VERSION ""

NS_ :

BS_:

BU_: WPC2 RLPSU DPSU APSU PSB SHVU_RR vHS_B2 FCS EMCU SLB ARS RCM CGW_CCU vDummy_HS_B ATS RLHV SGU PFSU ALBCU DSAU SWRC SHVU_FR RCS RRPSU BLTN_CAM SCM DLBCU OHCL RWPC RRHV WPC HOD ASAU

BO_ 862 SBCM_RL_01_200ms: 8 CGW_CCU
 SG_ SBCM_RL_Crc1Val : 0|8@1+ (1,0) [0|0] ""  Vector__XXX
 SG_ RL_CrashUnlockCmd : 10|1@1+ (1,0) [0|0] ""  BLTN_CAM
 SG_ SBCM_RL_AlvCnt1Val : 12|4@1+ (1,0) [0|0] ""  Vector__XXX
 SG_ Warn_RrLftDrSwSta_SBCM : 16|2@1+ (1,0) [0|0] ""  WPC,RWPC,APSU,ATS,BLTN_CAM,WPC2
 SG_ DoorLock_RrLftDrUnLkSta_SBCM : 18|2@1+ (1,0) [0|0] ""  ATS
 SG_ RL_SEAActivated : 20|2@1+ (1,0) [0|0] ""  Vector__XXX
 SG_ RL_SEAWarn : 22|2@1+ (1,0) [0|0] ""  Vector__XXX
 SG_ RL_SEWWarn : 24|2@1+ (1,0) [0|0] ""  Vector__XXX
 SG_ RL_ReleaseWarn : 26|2@1+ (1,0) [0|0] ""  Vector__XXX
 SG_ RL_SWFailAlarm : 28|2@1+ (1,0) [0|0] ""  Vector__XXX
 SG_ RL_ChildLock_ActnFlSta : 30|2@1+ (1,0) [0|0] ""  Vector__XXX
 SG_ RL_MRActivationAlarm : 32|2@1+ (1,0) [0|0] ""  Vector__XXX
 SG_ RL_ChildLock_Status : 34|2@1+ (1,0) [0|0] ""  Vector__XXX
 SG_ USM_RLGhostDoorSta : 36|2@1+ (1,0) [0|0] ""  Vector__XXX
 SG_ DoorLock_PDSLkSwSta_RL : 40|2@1+ (1,0) [0|0] ""  Vector__XXX
 SG_ PDS_TypeOption_RL : 42|2@1+ (1,0) [0|0] ""  Vector__XXX
 SG_ RLDoorPushAlarm : 8|2@1+ (1,0) [0|0] ""  Vector__XXX

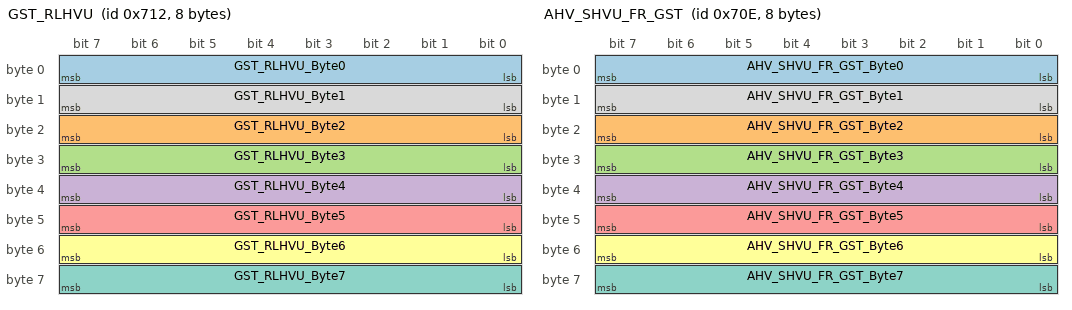
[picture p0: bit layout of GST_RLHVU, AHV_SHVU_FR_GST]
BO_ 1810 GST_RLHVU: 8 CGW_CCU
 SG_ GST_RLHVU_Byte0 : 0|8@1+ (1,0) [0|0] ""  RLHV,RLPSU
 SG_ GST_RLHVU_Byte2 : 16|8@1+ (1,0) [0|0] ""  RLHV,RLPSU
 SG_ GST_RLHVU_Byte3 : 24|8@1+ (1,0) [0|0] ""  RLHV,RLPSU
 SG_ GST_RLHVU_Byte4 : 32|8@1+ (1,0) [0|0] ""  RLHV,RLPSU
 SG_ GST_RLHVU_Byte5 : 40|8@1+ (1,0) [0|0] ""  RLHV,RLPSU
 SG_ GST_RLHVU_Byte6 : 48|8@1+ (1,0) [0|0] ""  RLHV,RLPSU
 SG_ GST_RLHVU_Byte7 : 56|8@1+ (1,0) [0|0] ""  RLHV,RLPSU
 SG_ GST_RLHVU_Byte1 : 8|8@1+ (1,0) [0|0] ""  RLHV,RLPSU

BO_ 1806 AHV_SHVU_FR_GST: 8 SHVU_FR
 SG_ AHV_SHVU_FR_GST_Byte0 : 0|8@1+ (1,0) [0|0] ""  CGW_CCU
 SG_ AHV_SHVU_FR_GST_Byte2 : 16|8@1+ (1,0) [0|0] ""  CGW_CCU
 SG_ AHV_SHVU_FR_GST_Byte3 : 24|8@1+ (1,0) [0|0] ""  CGW_CCU
 SG_ AHV_SHVU_FR_GST_Byte4 : 32|8@1+ (1,0) [0|0] ""  CGW_CCU
 SG_ AHV_SHVU_FR_GST_Byte5 : 40|8@1+ (1,0) [0|0] ""  CGW_CCU
 SG_ AHV_SHVU_FR_GST_Byte6 : 48|8@1+ (1,0) [0|0] ""  CGW_CCU
 SG_ AHV_SHVU_FR_GST_Byte7 : 56|8@1+ (1,0) [0|0] ""  CGW_CCU
 SG_ AHV_SHVU_FR_GST_Byte1 : 8|8@1+ (1,0) [0|0] ""  CGW_CCU

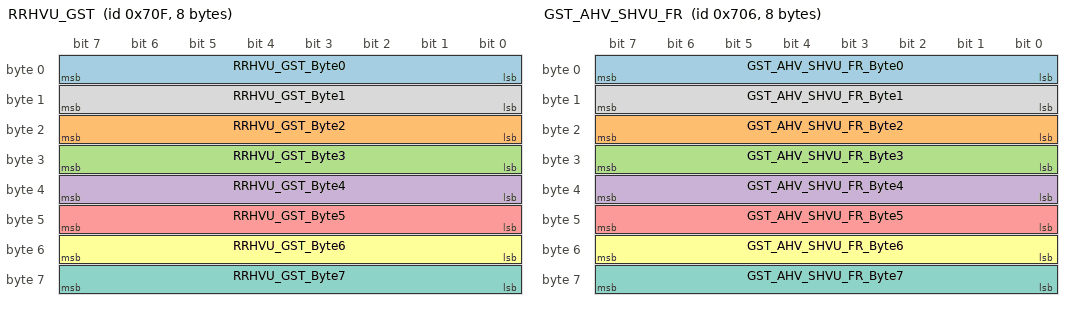
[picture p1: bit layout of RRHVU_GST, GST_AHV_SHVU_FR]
BO_ 1807 RRHVU_GST: 8 RRHV
 SG_ RRHVU_GST_Byte0 : 0|8@1+ (1,0) [0|0] ""  CGW_CCU
 SG_ RRHVU_GST_Byte2 : 16|8@1+ (1,0) [0|0] ""  CGW_CCU
 SG_ RRHVU_GST_Byte3 : 24|8@1+ (1,0) [0|0] ""  CGW_CCU
 SG_ RRHVU_GST_Byte4 : 32|8@1+ (1,0) [0|0] ""  CGW_CCU
 SG_ RRHVU_GST_Byte5 : 40|8@1+ (1,0) [0|0] ""  CGW_CCU
 SG_ RRHVU_GST_Byte6 : 48|8@1+ (1,0) [0|0] ""  CGW_CCU
 SG_ RRHVU_GST_Byte7 : 56|8@1+ (1,0) [0|0] ""  CGW_CCU
 SG_ RRHVU_GST_Byte1 : 8|8@1+ (1,0) [0|0] ""  CGW_CCU

BO_ 1798 GST_AHV_SHVU_FR: 8 CGW_CCU
 SG_ GST_AHV_SHVU_FR_Byte0 : 0|8@1+ (1,0) [0|0] ""  SHVU_FR
 SG_ GST_AHV_SHVU_FR_Byte2 : 16|8@1+ (1,0) [0|0] ""  SHVU_FR
 SG_ GST_AHV_SHVU_FR_Byte3 : 24|8@1+ (1,0) [0|0] ""  SHVU_FR
 SG_ GST_AHV_SHVU_FR_Byte4 : 32|8@1+ (1,0) [0|0] ""  SHVU_FR
 SG_ GST_AHV_SHVU_FR_Byte5 : 40|8@1+ (1,0) [0|0] ""  SHVU_FR
 SG_ GST_AHV_SHVU_FR_Byte6 : 48|8@1+ (1,0) [0|0] ""  SHVU_FR
 SG_ GST_AHV_SHVU_FR_Byte7 : 56|8@1+ (1,0) [0|0] ""  SHVU_FR
 SG_ GST_AHV_SHVU_FR_Byte1 : 8|8@1+ (1,0) [0|0] ""  SHVU_FR

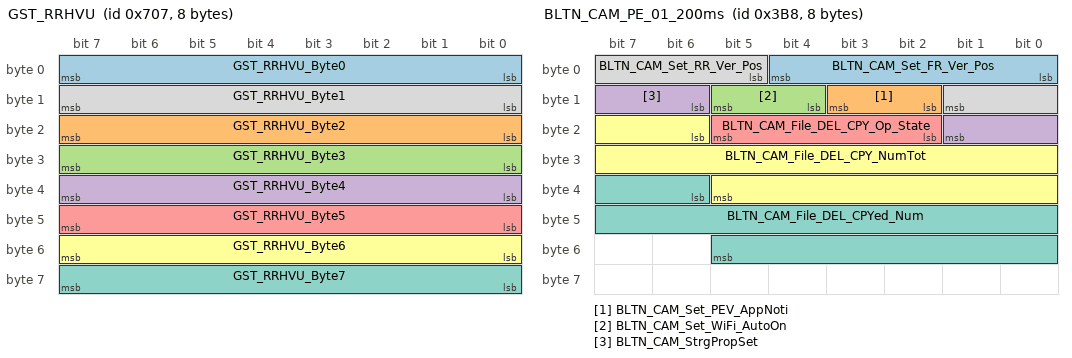
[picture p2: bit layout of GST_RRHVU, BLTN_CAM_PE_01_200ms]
BO_ 1799 GST_RRHVU: 8 CGW_CCU
 SG_ GST_RRHVU_Byte0 : 0|8@1+ (1,0) [0|0] ""  RRHV,SHVU_RR,RRPSU
 SG_ GST_RRHVU_Byte2 : 16|8@1+ (1,0) [0|0] ""  RRHV,SHVU_RR,RRPSU
 SG_ GST_RRHVU_Byte3 : 24|8@1+ (1,0) [0|0] ""  RRHV,SHVU_RR,RRPSU
 SG_ GST_RRHVU_Byte4 : 32|8@1+ (1,0) [0|0] ""  RRHV,SHVU_RR,RRPSU
 SG_ GST_RRHVU_Byte5 : 40|8@1+ (1,0) [0|0] ""  RRHV,SHVU_RR,RRPSU
 SG_ GST_RRHVU_Byte6 : 48|8@1+ (1,0) [0|0] ""  RRHV,SHVU_RR,RRPSU
 SG_ GST_RRHVU_Byte7 : 56|8@1+ (1,0) [0|0] ""  RRHV,SHVU_RR,RRPSU
 SG_ GST_RRHVU_Byte1 : 8|8@1+ (1,0) [0|0] ""  RRHV,SHVU_RR,RRPSU

BO_ 847 Drv_SHVU_03_200ms: 8 SHVU_FR
 SG_ Drv_SHVU_DTCdisplay : 0|8@1+ (1,0) [0|0] ""  Vector__XXX
 SG_ Drv_SHVU_DiagMode : 8|2@1+ (1,0) [0|0] ""  Vector__XXX

BO_ 952 BLTN_CAM_PE_01_200ms: 8 BLTN_CAM
 SG_ BLTN_CAM_Set_FR_Ver_Pos : 0|5@1+ (1,0) [0|0] ""  CGW_CCU
 SG_ BLTN_CAM_Set_PEV_AppNoti : 10|2@1+ (1,0) [0|0] ""  CGW_CCU
 SG_ BLTN_CAM_Set_WiFi_AutoOn : 12|2@1+ (1,0) [0|0] ""  CGW_CCU
 SG_ BLTN_CAM_StrgPropSet : 14|4@1+ (1,0) [0|0] ""  CGW_CCU
 SG_ BLTN_CAM_File_DEL_CPY_Op_State : 18|4@1+ (1,0) [0|0] ""  CGW_CCU
 SG_ BLTN_CAM_File_DEL_CPY_NumTot : 22|16@1+ (1,0) [0|0] ""  CGW_CCU
 SG_ BLTN_CAM_File_DEL_CPYed_Num : 38|16@1+ (1,0) [0|0] ""  CGW_CCU
 SG_ BLTN_CAM_Set_RR_Ver_Pos : 5|5@1+ (1,0) [0|0] ""  CGW_CCU

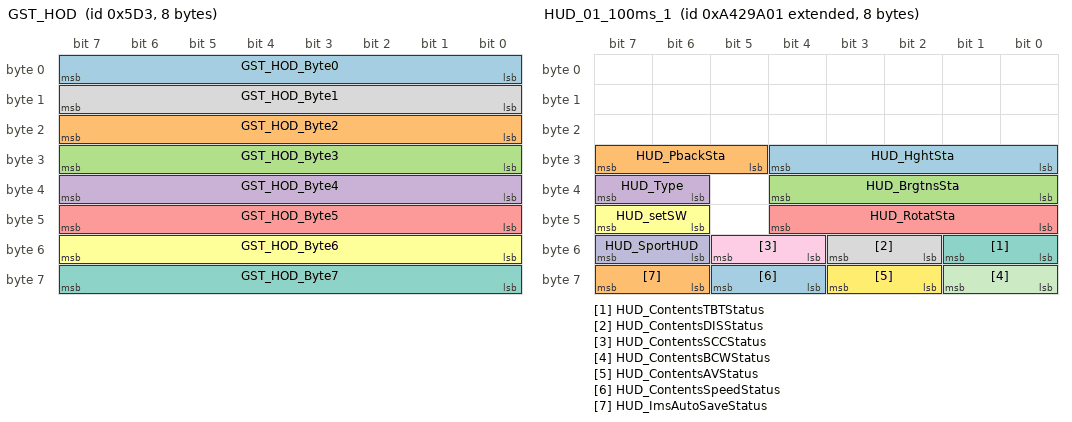
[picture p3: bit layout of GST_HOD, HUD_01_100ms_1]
BO_ 1491 GST_HOD: 8 CGW_CCU
 SG_ GST_HOD_Byte0 : 0|8@1+ (1,0) [0|0] ""  HOD
 SG_ GST_HOD_Byte2 : 16|8@1+ (1,0) [0|0] ""  HOD
 SG_ GST_HOD_Byte3 : 24|8@1+ (1,0) [0|0] ""  HOD
 SG_ GST_HOD_Byte4 : 32|8@1+ (1,0) [0|0] ""  HOD
 SG_ GST_HOD_Byte5 : 40|8@1+ (1,0) [0|0] ""  HOD
 SG_ GST_HOD_Byte6 : 48|8@1+ (1,0) [0|0] ""  HOD
 SG_ GST_HOD_Byte7 : 56|8@1+ (1,0) [0|0] ""  HOD
 SG_ GST_HOD_Byte1 : 8|8@1+ (1,0) [0|0] ""  HOD

BO_ 2319620609 HUD_01_100ms_1: 8 CGW_CCU
 SG_ HUD_HghtSta : 24|5@1+ (1,0) [0|0] ""  Vector__XXX
 SG_ HUD_PbackSta : 29|3@1+ (1,0) [0|0] ""  DPSU
 SG_ HUD_BrgtnsSta : 32|5@1+ (1,0) [0|0] ""  Vector__XXX
 SG_ HUD_Type : 38|2@1+ (1,0) [0|0] ""  Vector__XXX
 SG_ HUD_RotatSta : 40|5@1+ (1,0) [0|0] ""  Vector__XXX
 SG_ HUD_setSW : 46|2@1+ (1,0) [0|0] ""  Vector__XXX
 SG_ HUD_ContentsTBTStatus : 48|2@1+ (1,0) [0|0] ""  Vector__XXX
 SG_ HUD_ContentsDISStatus : 50|2@1+ (1,0) [0|0] ""  Vector__XXX
 SG_ HUD_ContentsSCCStatus : 52|2@1+ (1,0) [0|0] ""  Vector__XXX
 SG_ HUD_SportHUD : 54|2@1+ (1,0) [0|0] ""  Vector__XXX
 SG_ HUD_ContentsBCWStatus : 56|2@1+ (1,0) [0|0] ""  Vector__XXX
 SG_ HUD_ContentsAVStatus : 58|2@1+ (1,0) [0|0] ""  Vector__XXX
 SG_ HUD_ContentsSpeedStatus : 60|2@1+ (1,0) [0|0] ""  Vector__XXX
 SG_ HUD_ImsAutoSaveStatus : 62|2@1+ (1,0) [0|0] ""  Vector__XXX

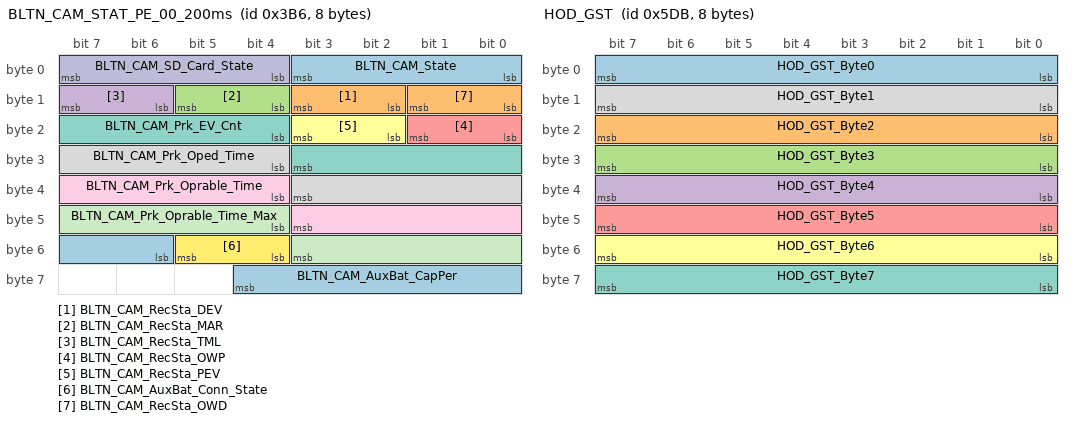
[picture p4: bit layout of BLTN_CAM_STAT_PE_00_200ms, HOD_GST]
BO_ 950 BLTN_CAM_STAT_PE_00_200ms: 8 BLTN_CAM
 SG_ BLTN_CAM_State : 0|4@1+ (1,0) [0|0] ""  CGW_CCU
 SG_ BLTN_CAM_RecSta_DEV : 10|2@1+ (1,0) [0|0] ""  CGW_CCU
 SG_ BLTN_CAM_RecSta_MAR : 12|2@1+ (1,0) [0|0] ""  CGW_CCU
 SG_ BLTN_CAM_RecSta_TML : 14|2@1+ (1,0) [0|0] ""  CGW_CCU
 SG_ BLTN_CAM_RecSta_OWP : 16|2@1+ (1,0) [0|0] ""  CGW_CCU
 SG_ BLTN_CAM_RecSta_PEV : 18|2@1+ (1,0) [0|0] ""  CGW_CCU
 SG_ BLTN_CAM_Prk_EV_Cnt : 20|8@1+ (1,0) [0|0] ""  CGW_CCU
 SG_ BLTN_CAM_Prk_Oped_Time : 28|8@1+ (1,0) [0|0] "Hour"  CGW_CCU
 SG_ BLTN_CAM_Prk_Oprable_Time : 36|8@1+ (1,0) [0|0] "Hour"  CGW_CCU
 SG_ BLTN_CAM_SD_Card_State : 4|4@1+ (1,0) [0|0] ""  CGW_CCU
 SG_ BLTN_CAM_Prk_Oprable_Time_Max : 44|8@1+ (1,0) [0|0] "Hour"  CGW_CCU
 SG_ BLTN_CAM_AuxBat_Conn_State : 52|2@1+ (1,0) [0|0] ""  CGW_CCU
 SG_ BLTN_CAM_AuxBat_CapPer : 54|7@1+ (1,0) [0|0] "%"  CGW_CCU
 SG_ BLTN_CAM_RecSta_OWD : 8|2@1+ (1,0) [0|0] ""  CGW_CCU

BO_ 951 BLTN_CAM_PE_00_200ms: 8 BLTN_CAM
 SG_ BLTN_CAM_RecSet_OWD : 0|2@1+ (1,0) [0|0] ""  CGW_CCU
 SG_ BLTN_CAM_Set_Tim_Stm : 10|2@1+ (1,0) [0|0] ""  CGW_CCU
 SG_ BLTN_CAM_Set_Spd_Stm : 12|2@1+ (1,0) [0|0] ""  CGW_CCU
 SG_ BLTN_CAM_Set_Locatn_Stm : 14|2@1+ (1,0) [0|0] ""  CGW_CCU
 SG_ BLTN_CAM_Set_TrnSig_Stm : 16|2@1+ (1,0) [0|0] ""  CGW_CCU
 SG_ BLTN_CAM_Set_AclBrk_Stm : 18|2@1+ (1,0) [0|0] ""  CGW_CCU
 SG_ BLTN_CAM_RecSet_DEV : 2|2@1+ (1,0) [0|0] ""  CGW_CCU
 SG_ BLTN_CAM_Set_GearPos_Stm : 20|2@1+ (1,0) [0|0] ""  CGW_CCU
 SG_ BLTN_CAM_Set_EVSen_Stm : 22|2@1+ (1,0) [0|0] ""  CGW_CCU
 SG_ BLTN_CAM_Set_StrAngl_Stm : 24|2@1+ (1,0) [0|0] ""  CGW_CCU
 SG_ BLTN_CAM_Set_PrkTime : 30|8@1+ (1,0) [0|0] "Hour"  CGW_CCU
 SG_ BLTN_CAM_Set_EV_BfrTime : 38|5@1+ (1,0) [0|0] ""  CGW_CCU
 SG_ BLTN_CAM_RecSet_OWP : 4|2@1+ (1,0) [0|0] ""  CGW_CCU
 SG_ BLTN_CAM_Set_EV_AftTime : 43|5@1+ (1,0) [0|0] ""  CGW_CCU
 SG_ BLTN_CAM_Set_Drv_TML_Int : 48|4@1+ (1,0) [0|0] ""  CGW_CCU
 SG_ BLTN_CAM_SenSet_DEV : 52|4@1+ (1,0) [0|0] ""  CGW_CCU
 SG_ BLTN_CAM_SenSet_PEV : 56|4@1+ (1,0) [0|0] ""  CGW_CCU
 SG_ BLTN_CAM_RecSet_PEV : 6|2@1+ (1,0) [0|0] ""  CGW_CCU
 SG_ BLTN_CAM_AudRec_Set : 8|2@1+ (1,0) [0|0] ""  CGW_CCU

BO_ 1499 HOD_GST: 8 HOD
 SG_ HOD_GST_Byte0 : 0|8@1+ (1,0) [0|0] ""  CGW_CCU
 SG_ HOD_GST_Byte2 : 16|8@1+ (1,0) [0|0] ""  CGW_CCU
 SG_ HOD_GST_Byte3 : 24|8@1+ (1,0) [0|0] ""  CGW_CCU
 SG_ HOD_GST_Byte4 : 32|8@1+ (1,0) [0|0] ""  CGW_CCU
 SG_ HOD_GST_Byte5 : 40|8@1+ (1,0) [0|0] ""  CGW_CCU
 SG_ HOD_GST_Byte6 : 48|8@1+ (1,0) [0|0] ""  CGW_CCU
 SG_ HOD_GST_Byte7 : 56|8@1+ (1,0) [0|0] ""  CGW_CCU
 SG_ HOD_GST_Byte1 : 8|8@1+ (1,0) [0|0] ""  CGW_CCU

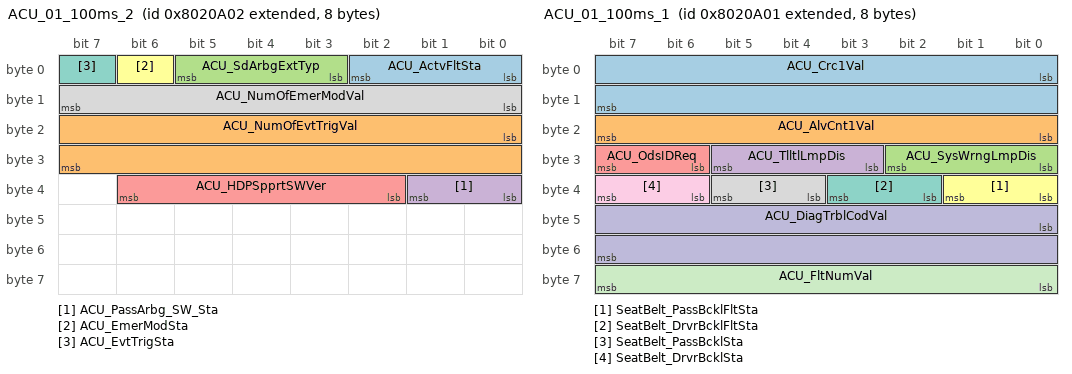
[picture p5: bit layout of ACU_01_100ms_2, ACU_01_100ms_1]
BO_ 2281835010 ACU_01_100ms_2: 8 CGW_CCU
 SG_ ACU_ActvFltSta : 0|3@1+ (1,0) [0|0] ""  Vector__XXX
 SG_ ACU_NumOfEvtTrigVal : 16|16@1+ (1,0) [0|0] ""  Vector__XXX
 SG_ ACU_SdArbgExtTyp : 3|3@1+ (1,0) [0|0] ""  Vector__XXX
 SG_ ACU_PassArbg_SW_Sta : 32|2@1+ (1,0) [0|0] ""  Vector__XXX
 SG_ ACU_HDPSpprtSWVer : 34|5@1+ (1,0) [0|0] ""  Vector__XXX
 SG_ ACU_EmerModSta : 6|1@1+ (1,0) [0|0] ""  Vector__XXX
 SG_ ACU_EvtTrigSta : 7|1@1+ (1,0) [0|0] ""  Vector__XXX
 SG_ ACU_NumOfEmerModVal : 8|8@1+ (1,0) [0|0] ""  Vector__XXX

BO_ 2281835009 ACU_01_100ms_1: 8 CGW_CCU
 SG_ ACU_Crc1Val : 0|16@1+ (1,0) [0|0] ""  OHCL
 SG_ ACU_AlvCnt1Val : 16|8@1+ (1,0) [0|0] ""  OHCL
 SG_ ACU_SysWrngLmpDis : 24|3@1+ (1,0) [0|0] ""  Vector__XXX
 SG_ ACU_TlltlLmpDis : 27|3@1+ (1,0) [0|0] ""  OHCL
 SG_ ACU_OdsIDReq : 30|2@1+ (1,0) [0|0] ""  Vector__XXX
 SG_ SeatBelt_PassBcklFltSta : 32|2@1+ (1,0) [0|0] ""  PSB
 SG_ SeatBelt_DrvrBcklFltSta : 34|2@1+ (1,0) [0|0] ""  PSB
 SG_ SeatBelt_PassBcklSta : 36|2@1+ (1,0) [0|0] ""  PSB,APSU,ATS
 SG_ SeatBelt_DrvrBcklSta : 38|2@1+ (1,0) [0|0] ""  PSB
 SG_ ACU_DiagTrblCodVal : 40|16@1+ (1,0) [0|0] ""  Vector__XXX
 SG_ ACU_FltNumVal : 56|8@1+ (1,0) [0|0] ""  Vector__XXX

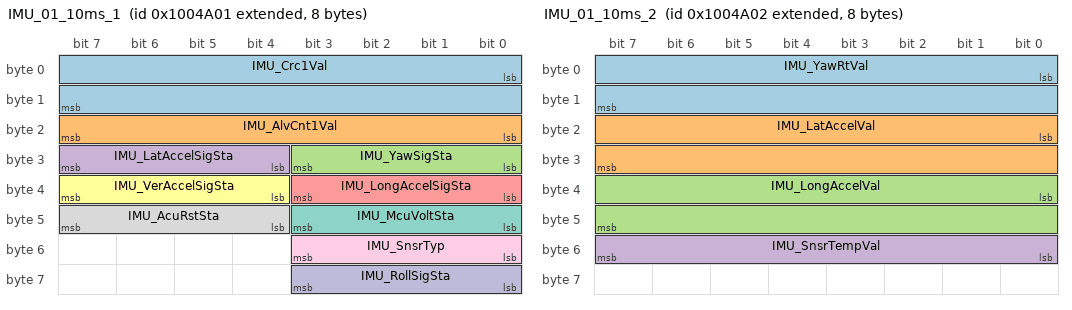
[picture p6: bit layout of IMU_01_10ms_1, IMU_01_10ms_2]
BO_ 2164279809 IMU_01_10ms_1: 8 CGW_CCU
 SG_ IMU_Crc1Val : 0|16@1+ (1,0) [0|0] ""  Vector__XXX
 SG_ IMU_AlvCnt1Val : 16|8@1+ (1,0) [0|0] ""  Vector__XXX
 SG_ IMU_YawSigSta : 24|4@1+ (1,0) [0|0] ""  PSB
 SG_ IMU_LatAccelSigSta : 28|4@1+ (1,0) [0|0] ""  PSB
 SG_ IMU_LongAccelSigSta : 32|4@1+ (1,0) [0|0] ""  PSB
 SG_ IMU_VerAccelSigSta : 36|4@1+ (1,0) [0|0] ""  Vector__XXX
 SG_ IMU_McuVoltSta : 40|4@1+ (1,0) [0|0] ""  Vector__XXX
 SG_ IMU_AcuRstSta : 44|4@1+ (1,0) [0|0] ""  Vector__XXX
 SG_ IMU_SnsrTyp : 48|4@1+ (1,0) [0|0] ""  Vector__XXX
 SG_ IMU_RollSigSta : 56|4@1+ (1,0) [0|0] ""  Vector__XXX

BO_ 2164279811 IMU_01_10ms_3: 8 CGW_CCU
 SG_ IMU_SeralNumVal : 0|48@1+ (1,0) [0|0] ""  Vector__XXX

BO_ 2164279810 IMU_01_10ms_2: 8 CGW_CCU
 SG_ IMU_YawRtVal : 0|16@1+ (0.005,-163.84) [0|0] "¢ª/s"  PSB
 SG_ IMU_LatAccelVal : 16|16@1+ (1.27465E-4,-4.17677312) [0|0] "g"  PSB
 SG_ IMU_LongAccelVal : 32|16@1+ (1.27465E-4,-4.17677312) [0|0] "g"  PSB
 SG_ IMU_SnsrTempVal : 48|8@1+ (1,-68) [0|0] "¡É"  Vector__XXX

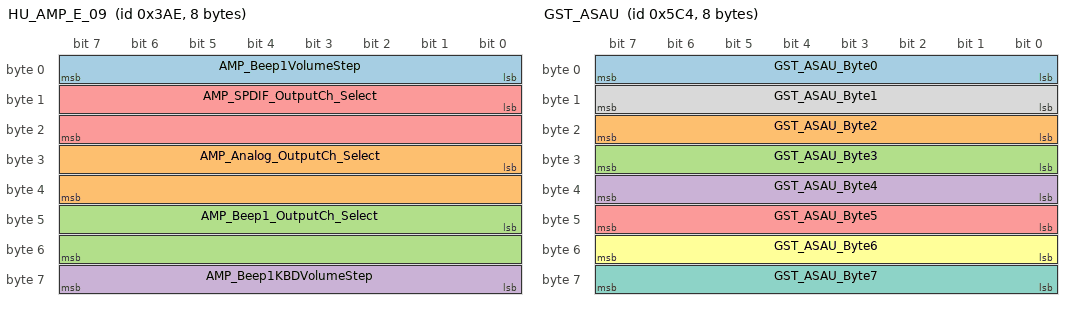
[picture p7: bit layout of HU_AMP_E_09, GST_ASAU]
BO_ 942 HU_AMP_E_09: 8 CGW_CCU
 SG_ AMP_Beep1VolumeStep : 0|8@1+ (1,0) [0|0] ""  ATS
 SG_ AMP_Analog_OutputCh_Select : 24|16@1+ (1,0) [0|0] ""  Vector__XXX
 SG_ AMP_Beep1_OutputCh_Select : 40|16@1+ (1,0) [0|0] ""  Vector__XXX
 SG_ AMP_Beep1KBDVolumeStep : 56|8@1+ (1,0) [0|0] ""  Vector__XXX
 SG_ AMP_SPDIF_OutputCh_Select : 8|16@1+ (1,0) [0|0] ""  Vector__XXX

BO_ 1476 GST_ASAU: 8 CGW_CCU
 SG_ GST_ASAU_Byte0 : 0|8@1+ (1,0) [0|0] ""  ASAU
 SG_ GST_ASAU_Byte2 : 16|8@1+ (1,0) [0|0] ""  ASAU
 SG_ GST_ASAU_Byte3 : 24|8@1+ (1,0) [0|0] ""  ASAU
 SG_ GST_ASAU_Byte4 : 32|8@1+ (1,0) [0|0] ""  ASAU
 SG_ GST_ASAU_Byte5 : 40|8@1+ (1,0) [0|0] ""  ASAU
 SG_ GST_ASAU_Byte6 : 48|8@1+ (1,0) [0|0] ""  ASAU
 SG_ GST_ASAU_Byte7 : 56|8@1+ (1,0) [0|0] ""  ASAU
 SG_ GST_ASAU_Byte1 : 8|8@1+ (1,0) [0|0] ""  ASAU

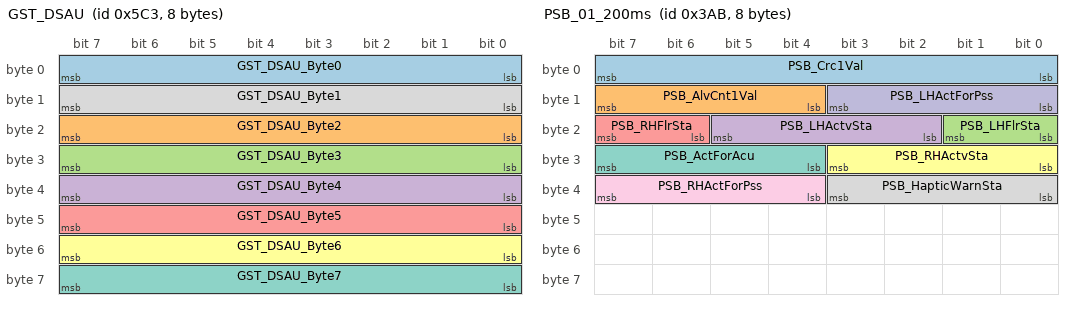
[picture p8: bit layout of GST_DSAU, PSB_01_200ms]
BO_ 1475 GST_DSAU: 8 CGW_CCU
 SG_ GST_DSAU_Byte0 : 0|8@1+ (1,0) [0|0] ""  DSAU
 SG_ GST_DSAU_Byte2 : 16|8@1+ (1,0) [0|0] ""  DSAU
 SG_ GST_DSAU_Byte3 : 24|8@1+ (1,0) [0|0] ""  DSAU
 SG_ GST_DSAU_Byte4 : 32|8@1+ (1,0) [0|0] ""  DSAU
 SG_ GST_DSAU_Byte5 : 40|8@1+ (1,0) [0|0] ""  DSAU
 SG_ GST_DSAU_Byte6 : 48|8@1+ (1,0) [0|0] ""  DSAU
 SG_ GST_DSAU_Byte7 : 56|8@1+ (1,0) [0|0] ""  DSAU
 SG_ GST_DSAU_Byte1 : 8|8@1+ (1,0) [0|0] ""  DSAU

BO_ 2164279812 IMU_01_10ms_4: 8 CGW_CCU
 SG_ IMU_RollRtVal : 0|16@1+ (0.005,-163.84) [0|0] "¢ª/s"  Vector__XXX
 SG_ IMU_VerAccelVal : 16|16@1+ (1.27465E-4,-4.17677312) [0|0] "g"  Vector__XXX

BO_ 939 PSB_01_200ms: 8 PSB
 SG_ PSB_Crc1Val : 0|8@1+ (1,0) [0|0] ""  CGW_CCU
 SG_ PSB_AlvCnt1Val : 12|4@1+ (1,0) [0|0] ""  CGW_CCU
 SG_ PSB_LHFlrSta : 16|2@1+ (1,0) [0|0] ""  CGW_CCU
 SG_ PSB_LHActvSta : 18|4@1+ (1,0) [0|0] ""  CGW_CCU
 SG_ PSB_RHFlrSta : 22|2@1+ (1,0) [0|0] ""  CGW_CCU
 SG_ PSB_RHActvSta : 24|4@1+ (1,0) [0|0] ""  APSU,CGW_CCU
 SG_ PSB_ActForAcu : 28|4@1+ (1,0) [0|0] ""  CGW_CCU
 SG_ PSB_HapticWarnSta : 32|4@1+ (1,0) [0|0] ""  CGW_CCU
 SG_ PSB_RHActForPss : 36|4@1+ (1,0) [0|0] ""  APSU,RLPSU,RRPSU
 SG_ PSB_LHActForPss : 8|4@1+ (1,0) [0|0] ""  RLPSU,RRPSU

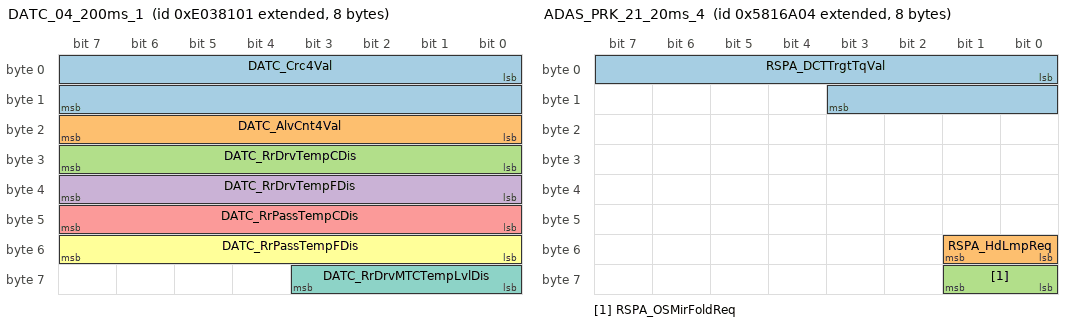
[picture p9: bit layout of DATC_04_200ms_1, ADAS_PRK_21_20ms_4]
BO_ 2382594305 DATC_04_200ms_1: 8 CGW_CCU
 SG_ DATC_Crc4Val : 0|16@1+ (1,0) [0|0] ""  Vector__XXX
 SG_ DATC_AlvCnt4Val : 16|8@1+ (1,0) [0|0] ""  Vector__XXX
 SG_ DATC_RrDrvTempCDis : 24|8@1+ (0.5,14) [0|0] "¡É"  ATS
 SG_ DATC_RrDrvTempFDis : 32|8@1+ (1,56) [0|0] "¢µ"  ATS
 SG_ DATC_RrPassTempCDis : 40|8@1+ (0.5,14) [0|0] "¡É"  Vector__XXX
 SG_ DATC_RrPassTempFDis : 48|8@1+ (1,56) [0|0] "¢µ"  Vector__XXX
 SG_ DATC_RrDrvMTCTempLvlDis : 56|4@1+ (1,0) [0|0] ""  Vector__XXX

BO_ 2239851012 ADAS_PRK_21_20ms_4: 8 CGW_CCU
 SG_ RSPA_DCTTrgtTqVal : 0|12@1- (1,0) [0|0] "Nm"  Vector__XXX
 SG_ RSPA_HdLmpReq : 48|2@1+ (1,0) [0|0] ""  Vector__XXX
 SG_ RSPA_OSMirFoldReq : 56|2@1+ (1,0) [0|0] ""  Vector__XXX

BO_ 934 PTGM_01_200ms: 8 CGW_CCU
 SG_ PTGM_Crc1Val : 0|8@1+ (1,0) [0|0] ""  Vector__XXX
 SG_ PTGM_AlvCnt1Val : 12|4@1+ (1,0) [0|0] ""  Vector__XXX
 SG_ PTGM_HazardSta : 16|2@1+ (1,0) [0|0] ""  Vector__XXX
 SG_ PTGM_ModSta : 18|2@1+ (1,0) [0|0] ""  Vector__XXX
 SG_ PTGM_MovSta : 20|2@1+ (1,0) [0|0] ""  Vector__XXX
 SG_ PTGM_OptTyp : 22|2@1+ (1,0) [0|0] ""  Vector__XXX
 SG_ PTGM_ReleaseRlySta : 24|2@1+ (1,0) [0|0] ""  APSU,PFSU
 SG_ PTGM_TrnkLkSwSta : 26|2@1+ (1,0) [0|0] ""  Vector__XXX
 SG_ PTGM_UsmSetSta : 28|2@1+ (1,0) [0|0] ""  Vector__XXX
 SG_ PTGM_HeightRValue : 32|3@1+ (1,0) [0|0] ""  Vector__XXX
 SG_ PTGM_OpnClsState : 35|4@1+ (1,0) [0|0] ""  Vector__XXX
 SG_ PTGM_CmdWarn : 40|3@1+ (1,0) [0|0] ""  Vector__XXX
 SG_ PTGM_AntiPinchSnsr : 43|2@1+ (1,0) [0|0] ""  Vector__XXX
 SG_ PTGM_AutoWashModeSta : 45|3@1+ (1,0) [0|0] ""  Vector__XXX
 SG_ PTGM_FobSrch_Req : 52|2@1+ (1,0) [0|0] ""  Vector__XXX
 SG_ PTGM_TlgtAwayCloseRValue : 54|2@1+ (1,0) [0|0] ""  Vector__XXX
 SG_ PTGM_TrnkTlgtOption : 56|2@1+ (1,0) [0|0] ""  Vector__XXX
 SG_ PTGM_LatchType : 58|2@1+ (1,0) [0|0] ""  Vector__XXX
 SG_ PTGM_SpeedRValue : 8|4@1+ (1,0) [0|0] ""  Vector__XXX

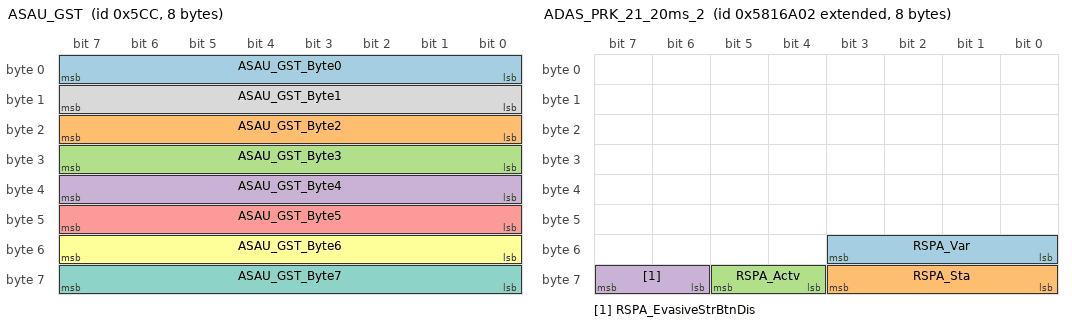
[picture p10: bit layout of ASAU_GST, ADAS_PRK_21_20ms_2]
BO_ 1484 ASAU_GST: 8 ASAU
 SG_ ASAU_GST_Byte0 : 0|8@1+ (1,0) [0|0] ""  CGW_CCU
 SG_ ASAU_GST_Byte2 : 16|8@1+ (1,0) [0|0] ""  CGW_CCU
 SG_ ASAU_GST_Byte3 : 24|8@1+ (1,0) [0|0] ""  CGW_CCU
 SG_ ASAU_GST_Byte4 : 32|8@1+ (1,0) [0|0] ""  CGW_CCU
 SG_ ASAU_GST_Byte5 : 40|8@1+ (1,0) [0|0] ""  CGW_CCU
 SG_ ASAU_GST_Byte6 : 48|8@1+ (1,0) [0|0] ""  CGW_CCU
 SG_ ASAU_GST_Byte7 : 56|8@1+ (1,0) [0|0] ""  CGW_CCU
 SG_ ASAU_GST_Byte1 : 8|8@1+ (1,0) [0|0] ""  CGW_CCU

BO_ 929 SCM_03_200ms: 8 SCM
 SG_ SCM_Opt : 0|2@1+ (1,0) [0|0] ""  DPSU,CGW_CCU
 SG_ Tilt_VirtualLimExist : 10|2@1+ (1,0) [0|0] ""  CGW_CCU
 SG_ Tele_SnsrErr : 12|2@1+ (1,0) [0|0] ""  CGW_CCU
 SG_ Tele_VirtualLim : 14|2@1+ (1,0) [0|0] ""  CGW_CCU
 SG_ Tele_VirtualLimExist : 16|2@1+ (1,0) [0|0] ""  CGW_CCU
 SG_ TiltTele_Profile1MemoryExist : 18|2@1+ (1,0) [0|0] ""  CGW_CCU
 SG_ Tilt_MnlSwSta : 2|2@1+ (1,0) [0|0] ""  CGW_CCU
 SG_ TiltTele_Profile2MemoryExist : 20|2@1+ (1,0) [0|0] ""  CGW_CCU
 SG_ TiltTele_GuestMemoryExist : 22|2@1+ (1,0) [0|0] ""  CGW_CCU
 SG_ TiltTele_IMS1MemoryExist : 24|2@1+ (1,0) [0|0] ""  CGW_CCU
 SG_ TiltTele_IMS2MemoryExist : 26|2@1+ (1,0) [0|0] ""  CGW_CCU
 SG_ TiltTele_IMS3MemoryExist : 28|2@1+ (1,0) [0|0] ""  CGW_CCU
 SG_ TiltTele_ReturnMemoryExist : 30|2@1+ (1,0) [0|0] ""  CGW_CCU
 SG_ Tilt_OpSta : 32|2@1+ (1,0) [0|0] ""  CGW_CCU
 SG_ Tele_OpSta : 34|2@1+ (1,0) [0|0] ""  CGW_CCU
 SG_ Tele_MnlSwSta : 4|2@1+ (1,0) [0|0] ""  CGW_CCU
 SG_ Tilt_SnsrErr : 6|2@1+ (1,0) [0|0] ""  CGW_CCU
 SG_ Tilt_VirtualLim : 8|2@1+ (1,0) [0|0] ""  CGW_CCU

BO_ 2239851010 ADAS_PRK_21_20ms_2: 8 CGW_CCU
 SG_ RSPA_Var : 48|4@1+ (1,0) [0|0] ""  Vector__XXX
 SG_ RSPA_Sta : 56|4@1+ (1,0) [0|0] ""  Vector__XXX
 SG_ RSPA_Actv : 60|2@1+ (1,0) [0|0] ""  Vector__XXX
 SG_ RSPA_EvasiveStrBtnDis : 62|2@1+ (1,0) [0|0] ""  Vector__XXX

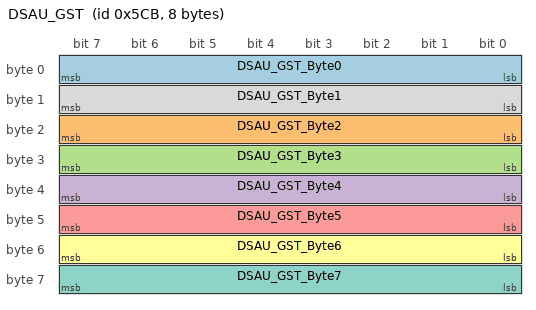
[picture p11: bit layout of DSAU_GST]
BO_ 1483 DSAU_GST: 8 DSAU
 SG_ DSAU_GST_Byte0 : 0|8@1+ (1,0) [0|0] ""  CGW_CCU
 SG_ DSAU_GST_Byte2 : 16|8@1+ (1,0) [0|0] ""  CGW_CCU
 SG_ DSAU_GST_Byte3 : 24|8@1+ (1,0) [0|0] ""  CGW_CCU
 SG_ DSAU_GST_Byte4 : 32|8@1+ (1,0) [0|0] ""  CGW_CCU
 SG_ DSAU_GST_Byte5 : 40|8@1+ (1,0) [0|0] ""  CGW_CCU
 SG_ DSAU_GST_Byte6 : 48|8@1+ (1,0) [0|0] ""  CGW_CCU
 SG_ DSAU_GST_Byte7 : 56|8@1+ (1,0) [0|0] ""  CGW_CCU
 SG_ DSAU_GST_Byte1 : 8|8@1+ (1,0) [0|0] ""  CGW_CCU

BO_TX_BU_ 1807 : RRHV,RRPSU,SHVU_RR;
CM_ BO_ 2281835009 "[P] Periodic";
CM_ SG_ 2281835009 ACU_Crc1Val "ACU_CyclicRedundancyCheck1Value";
CM_ SG_ 2281835009 ACU_AlvCnt1Val "ACU_AliveCounter1Value";
CM_ SG_ 2281835009 ACU_SysWrngLmpDis "ACU_SystemWarningLampDisplay ##2G##ACU - ACU14 - CF_SWL_Ind";
CM_ SG_ 2281835009 ACU_TlltlLmpDis "PAB ON OFF Lamp indication bit. 00X : PAB OFF LAMP, 0YO : PAB ON LAMP";
CM_ SG_ 2281835009 ACU_OdsIDReq "ACU_OdsIDRequest ##2G##ACU - ACU11 - CF_Ods_IDRcv";
CM_ SG_ 2281835009 SeatBelt_PassBcklFltSta "SeatBelt_PassengerBuckleFaultStatus ##2G##ACU - ACU11 - CF_PasBkl_FltStat";
CM_ SG_ 2281835009 SeatBelt_DrvrBcklFltSta "SeatBelt_DriverBuckleFaultStatus ##2G##ACU - ACU11 - CF_DriBkl_FltStat";
CM_ SG_ 2281835009 SeatBelt_PassBcklSta "SeatBelt_PassengerBuckleStatus ##2G##ACU - ACU11 - CF_PasBkl_Stat";
CM_ SG_ 2281835009 SeatBelt_DrvrBcklSta "SeatBelt_DriverBuckleStatus ##2G##ACU - ACU11 - CF_DriBkl_Stat";
CM_ SG_ 2281835009 ACU_DiagTrblCodVal "ACU_DiagnosticTroubleCodeValue ##2G##ACU - ACU11 - CF_Acu_Dtc";
CM_ SG_ 2281835009 ACU_FltNumVal "ACU_FaultNumberValue ##2G##ACU - ACU11 - CF_Acu_NumOfFlt";
CM_ BO_ 2281835010 "[P] Periodic";
CM_ SG_ 2281835010 ACU_ActvFltSta "ACU_ActiveFaultStatus ##2G##ACU - ACU11 - CF_Acu_FltStat";
CM_ SG_ 2281835010 ACU_NumOfEvtTrigVal "EDR trigger counter";
CM_ SG_ 2281835010 ACU_SdArbgExtTyp "ACU_SideAirbagExistanceType ##2G##ACU - ACU11 - CF_Acu_ExtOfSab";
CM_ SG_ 2281835010 ACU_PassArbg_SW_Sta "PAB ON_OFF S/W state for USM";
CM_ SG_ 2281835010 ACU_HDPSpprtSWVer "Software version information of signals related to HDP cooperative control";
CM_ SG_ 2281835010 ACU_EvtTrigSta "EDR triggered information bit";
CM_ SG_ 2281835010 ACU_NumOfEmerModVal "Emergency mode counter";
CM_ BO_ 2239851010 "[P] Periodic";
CM_ SG_ 2239851010 RSPA_Var "RSPA_Variation";
CM_ SG_ 2239851010 RSPA_Sta "RSPA_Status";
CM_ SG_ 2239851010 RSPA_Actv "RSPA_Actvation";
CM_ SG_ 2239851010 RSPA_EvasiveStrBtnDis "RSPA_EvasiveSteeringButtonDisplay";
CM_ BO_ 2239851012 "[P] Periodic";
CM_ SG_ 2239851012 RSPA_DCTTrgtTqVal "RSPA_DCTTargetTorqueValue";
CM_ SG_ 2239851012 RSPA_HdLmpReq "RSPA Head Lamp Request";
CM_ SG_ 2239851012 RSPA_OSMirFoldReq "RSPA_OSMirrorFoldRequest";
CM_ BO_ 1806 "[TP] Transport Protocol";
CM_ BO_ 1484 "[TP] Transport Protocol";
CM_ SG_ 1484 ASAU_GST_Byte0 "Diag Response from ASAU";
CM_ SG_ 1484 ASAU_GST_Byte2 "Diag Response from ASAU";
CM_ SG_ 1484 ASAU_GST_Byte3 "Diag Response from ASAU";
CM_ SG_ 1484 ASAU_GST_Byte4 "Diag Response from ASAU";
CM_ SG_ 1484 ASAU_GST_Byte5 "Diag Response from ASAU";
CM_ SG_ 1484 ASAU_GST_Byte6 "Diag Response from ASAU";
CM_ SG_ 1484 ASAU_GST_Byte7 "Diag Response from ASAU";
CM_ SG_ 1484 ASAU_GST_Byte1 "Diag Response from ASAU";
CM_ BO_ 951 "[PE] Periodic and On Event";
CM_ SG_ 951 BLTN_CAM_RecSet_OWD "Record On/Off Set of On While Driving";
CM_ SG_ 951 BLTN_CAM_Set_Tim_Stm "Record Set of Date and Time Stamp";
CM_ SG_ 951 BLTN_CAM_Set_Spd_Stm "Record Set of Speed Stamp";
CM_ SG_ 951 BLTN_CAM_Set_Locatn_Stm "Record Set of Location Stamp";
CM_ SG_ 951 BLTN_CAM_Set_TrnSig_Stm "Record Set of Turn Signal Stamp";
CM_ SG_ 951 BLTN_CAM_Set_AclBrk_Stm "Record Set of Accelerator Brake Stamp";
CM_ SG_ 951 BLTN_CAM_RecSet_DEV "Record On/Off Set of Driving Event";
CM_ SG_ 951 BLTN_CAM_Set_GearPos_Stm "Record Set of Gear Position Stamp";
CM_ SG_ 951 BLTN_CAM_Set_EVSen_Stm "Record Set of Event Sensitivity Stamp";
CM_ SG_ 951 BLTN_CAM_Set_StrAngl_Stm "Record Set of Steering Angle Stamp";
CM_ SG_ 951 BLTN_CAM_Set_PrkTime "Parking Operation Setting Time, Resolution : hr";
CM_ SG_ 951 BLTN_CAM_Set_EV_BfrTime "Driving Event Time Setting - Before, Resolution : sec";
CM_ SG_ 951 BLTN_CAM_RecSet_OWP "Record On/Off Set of On While Parked, 0x0(Default) : Parking recording function not supported";
CM_ SG_ 951 BLTN_CAM_Set_EV_AftTime "Driving Event Time Setting - After, Resolution : sec";
CM_ SG_ 951 BLTN_CAM_Set_Drv_TML_Int "Record Set of Time-lapse Interval, Resolution : sec";
CM_ SG_ 951 BLTN_CAM_SenSet_DEV "Set of Event  Detection Sensitivity of Driving Mode";
CM_ SG_ 951 BLTN_CAM_SenSet_PEV "Set of Event  Detection Sensitivity of Parking Mode";
CM_ SG_ 951 BLTN_CAM_RecSet_PEV "Record Set of Parked Event, 0x0(Default) : Parking recording function not supported";
CM_ SG_ 951 BLTN_CAM_AudRec_Set "Audio Record On/Off Set";
CM_ BO_ 952 "[PE] Periodic and On Event";
CM_ SG_ 952 BLTN_CAM_Set_FR_Ver_Pos "Front Camera Vertical position setting value.";
CM_ SG_ 952 BLTN_CAM_Set_PEV_AppNoti "Parked Event notification to Connectivity Phone App. On/Off";
CM_ SG_ 952 BLTN_CAM_Set_WiFi_AutoOn "Wifi On/Off User setting";
CM_ SG_ 952 BLTN_CAM_StrgPropSet "Propotion of built-in Cam SD card Propotion set of the Recording Categories";
CM_ SG_ 952 BLTN_CAM_File_DEL_CPY_Op_State "Bulil in Cam Fily copy and delete operating state.";
CM_ SG_ 952 BLTN_CAM_File_DEL_CPY_NumTot "Number of Copied or Deleted files.";
CM_ SG_ 952 BLTN_CAM_File_DEL_CPYed_Num "Total number of the copy or delete file.";
CM_ SG_ 952 BLTN_CAM_Set_RR_Ver_Pos "Rear Camera Vertical position setting value.";
CM_ BO_ 950 "[PE] Periodic and On Event";
CM_ SG_ 950 BLTN_CAM_State "This Signal is for cluster warning popup.";
CM_ SG_ 950 BLTN_CAM_RecSta_DEV "This Signal inform recording status of Driving Event.";
CM_ SG_ 950 BLTN_CAM_RecSta_MAR "This Signal inform recording status of Manual Recording.";
CM_ SG_ 950 BLTN_CAM_RecSta_TML "This Signal inform recording status of Time-lapse.";
CM_ SG_ 950 BLTN_CAM_RecSta_OWP "This Signal inform recording status of On While Parked.";
CM_ SG_ 950 BLTN_CAM_RecSta_PEV "This Signal inform recording status of Parked Event.";
CM_ SG_ 950 BLTN_CAM_Prk_EV_Cnt "The count number of a parked Event.";
CM_ SG_ 950 BLTN_CAM_Prk_Oped_Time "The Parked Opreated time ingormation";
CM_ SG_ 950 BLTN_CAM_Prk_Oprable_Time "The hours of Park Mode Operatable, the time is limited by user max oper. Set.";
CM_ SG_ 950 BLTN_CAM_SD_Card_State "This Signal is for SD card Status in Built-in App menu and CCS Phone App.";
CM_ SG_ 950 BLTN_CAM_Prk_Oprable_Time_Max "The hours of Park Mode Operatable, the time has no limit.";
CM_ SG_ 950 BLTN_CAM_AuxBat_Conn_State "0x0 : Default / 0x1 : Auxiliary Battery is connected.(P-LBM or B-LBM) / 0x2 : Auxiliary Battery Is not connected. - Auxiliary Battery applicable on this vehicle model / 0x3:  Auxiliary Battery is not connected. ? Auxiliary Battery not applicable on this vehicle model";
CM_ SG_ 950 BLTN_CAM_AuxBat_CapPer "The percentage of Aux. Bat.";
CM_ SG_ 950 BLTN_CAM_RecSta_OWD "This Signal inform recording status of On While Driving.";
CM_ BO_ 2382594305 "[PE] Periodic and On Event";
CM_ SG_ 2382594305 DATC_Crc4Val "DATC_CyclicRedundancyCheck4Value";
CM_ SG_ 2382594305 DATC_AlvCnt4Val "DATC_AliveCounter4Value";
CM_ SG_ 2382594305 DATC_RrDrvTempCDis "DATC_RearDriverTemperatureCelciusDisplay";
CM_ SG_ 2382594305 DATC_RrDrvTempFDis "DATC_RearDriverTemperatureFahrenheitDisplay";
CM_ SG_ 2382594305 DATC_RrPassTempCDis "DATC_RearPassengerTemperatureCelciusDisplay";
CM_ SG_ 2382594305 DATC_RrPassTempFDis "DATC_RearPassengerTemperatureFahrenheitDisplay";
CM_ SG_ 2382594305 DATC_RrDrvMTCTempLvlDis "DATC_RearDriverMTCTemperatureLevelDisplay";
CM_ BO_ 1483 "[TP] Transport Protocol";
CM_ SG_ 1483 DSAU_GST_Byte0 "Diag Response from DSAU";
CM_ SG_ 1483 DSAU_GST_Byte2 "Diag Response from DSAU";
CM_ SG_ 1483 DSAU_GST_Byte3 "Diag Response from DSAU";
CM_ SG_ 1483 DSAU_GST_Byte4 "Diag Response from DSAU";
CM_ SG_ 1483 DSAU_GST_Byte5 "Diag Response from DSAU";
CM_ SG_ 1483 DSAU_GST_Byte6 "Diag Response from DSAU";
CM_ SG_ 1483 DSAU_GST_Byte7 "Diag Response from DSAU";
CM_ SG_ 1483 DSAU_GST_Byte1 "Diag Response from DSAU";
CM_ BO_ 847 "[PE] Periodic and On Event";
CM_ BO_ 1798 "[TP] Transport Protocol";
CM_ BO_ 1476 "[TP] Transport Protocol";
CM_ SG_ 1476 GST_ASAU_Byte0 "Diag Request for ASAU";
CM_ SG_ 1476 GST_ASAU_Byte2 "Diag Request for ASAU";
CM_ SG_ 1476 GST_ASAU_Byte3 "Diag Request for ASAU";
CM_ SG_ 1476 GST_ASAU_Byte4 "Diag Request for ASAU";
CM_ SG_ 1476 GST_ASAU_Byte5 "Diag Request for ASAU";
CM_ SG_ 1476 GST_ASAU_Byte6 "Diag Request for ASAU";
CM_ SG_ 1476 GST_ASAU_Byte7 "Diag Request for ASAU";
CM_ SG_ 1476 GST_ASAU_Byte1 "Diag Request for ASAU";
CM_ BO_ 1475 "[TP] Transport Protocol";
CM_ SG_ 1475 GST_DSAU_Byte0 "Diag Request for DSAU";
CM_ SG_ 1475 GST_DSAU_Byte2 "Diag Request for DSAU";
CM_ SG_ 1475 GST_DSAU_Byte3 "Diag Request for DSAU";
CM_ SG_ 1475 GST_DSAU_Byte4 "Diag Request for DSAU";
CM_ SG_ 1475 GST_DSAU_Byte5 "Diag Request for DSAU";
CM_ SG_ 1475 GST_DSAU_Byte6 "Diag Request for DSAU";
CM_ SG_ 1475 GST_DSAU_Byte7 "Diag Request for DSAU";
CM_ SG_ 1475 GST_DSAU_Byte1 "Diag Request for DSAU";
CM_ BO_ 1491 "[TP] Transport Protocol";
CM_ SG_ 1491 GST_HOD_Byte0 "Diag Request for HOD";
CM_ SG_ 1491 GST_HOD_Byte2 "Diag Request for HOD";
CM_ SG_ 1491 GST_HOD_Byte3 "Diag Request for HOD";
CM_ SG_ 1491 GST_HOD_Byte4 "Diag Request for HOD";
CM_ SG_ 1491 GST_HOD_Byte5 "Diag Request for HOD";
CM_ SG_ 1491 GST_HOD_Byte6 "Diag Request for HOD";
CM_ SG_ 1491 GST_HOD_Byte7 "Diag Request for HOD";
CM_ SG_ 1491 GST_HOD_Byte1 "Diag Request for HOD";
CM_ BO_ 1810 "[TP] Transport Protocol";
CM_ BO_ 1799 "[TP] Transport Protocol";
CM_ BO_ 1499 "[TP] Transport Protocol";
CM_ SG_ 1499 HOD_GST_Byte0 "Diag Response from HOD";
CM_ SG_ 1499 HOD_GST_Byte2 "Diag Response from HOD";
CM_ SG_ 1499 HOD_GST_Byte3 "Diag Response from HOD";
CM_ SG_ 1499 HOD_GST_Byte4 "Diag Response from HOD";
CM_ SG_ 1499 HOD_GST_Byte5 "Diag Response from HOD";
CM_ SG_ 1499 HOD_GST_Byte6 "Diag Response from HOD";
CM_ SG_ 1499 HOD_GST_Byte7 "Diag Response from HOD";
CM_ SG_ 1499 HOD_GST_Byte1 "Diag Response from HOD";
CM_ BO_ 2319620609 "[PE] Periodic and On Event";
CM_ SG_ 2319620609 HUD_HghtSta "HUD_HeightStatus";
CM_ SG_ 2319620609 HUD_PbackSta "HUD_PbackStatus";
CM_ SG_ 2319620609 HUD_BrgtnsSta "HUD_BrightnessStatus";
CM_ SG_ 2319620609 HUD_Type "the type of head up display (ex : combiner type, windshield type)";
CM_ SG_ 2319620609 HUD_RotatSta "HUD_RotateStatus";
CM_ SG_ 2319620609 HUD_setSW "the status of head up display on/off";
CM_ SG_ 2319620609 HUD_ContentsTBTStatus "this signal shows the display contents setting status of TBT on HUD";
CM_ SG_ 2319620609 HUD_ContentsDISStatus "this signal shows the display contents status of DIS on HUD";
CM_ SG_ 2319620609 HUD_ContentsSCCStatus "this signal shows the display contents status of SCC on HUD";
CM_ SG_ 2319620609 HUD_SportHUD "this signal shows the display contents status of Sport mode HUD";
CM_ SG_ 2319620609 HUD_ContentsBCWStatus "this signal shows the display contents status of BCW on HUD";
CM_ SG_ 2319620609 HUD_ContentsAVStatus "this signal shows the display contents status of AV on HUD";
CM_ SG_ 2319620609 HUD_ContentsSpeedStatus "this signal shows the Speedometer contents status of HUD";
CM_ SG_ 2319620609 HUD_ImsAutoSaveStatus "this signal shows that Ims Auto Save function status";
CM_ BO_ 942 "[EC] On Event and On Change";
CM_ SG_ 942 AMP_Beep1VolumeStep "Command for Touch Beep Sound Volume Setting 
-range : 0 ~ max
-max : value of AMP_MaxBeep1VolumeState(0x087)
Harman AMP Only
-This Signal's Feedback is AMP_Beep1VolumeState(0x08A)@AMP";
CM_ BO_ 2164279809 "[P] Periodic";
CM_ SG_ 2164279809 IMU_Crc1Val "IMU_CyclicRedundancyCheck1Value";
CM_ SG_ 2164279809 IMU_AlvCnt1Val "IMU_AliveCounter1Value";
CM_ SG_ 2164279809 IMU_YawSigSta "IMU_YawSignalStatus ##2G##YRS - YRS11 - CF_Yrs_YrStat";
CM_ SG_ 2164279809 IMU_LatAccelSigSta "IMU_LateralAccelerationSignalStatus ##2G##YRS - YRS11 - CF_Yrs_LatAcStat";
CM_ SG_ 2164279809 IMU_LongAccelSigSta "IMU_LongitudinalAccelerationSignalStatus ##2G##YRS - YRS12 - CF_Yrs_LongAcStat";
CM_ SG_ 2164279809 IMU_VerAccelSigSta "IMU_Vertial Acceleration Signal Status";
CM_ SG_ 2164279809 IMU_McuVoltSta "IMU_McuVoltageStatus ##2G##YRS - YRS11 - CF_Yrs_MCUStat";
CM_ SG_ 2164279809 IMU_AcuRstSta "IMU_AcuResetStatus ##2G##YRS - YRS12 - CF_IMU_ResetStat";
CM_ SG_ 2164279809 IMU_SnsrTyp "IMU SensorType (Axis information)##2G##YRS - YRS12 - CF_Yrs_Type";
CM_ SG_ 2164279809 IMU_RollSigSta "IMU Rollrate signal status";
CM_ BO_ 2164279810 "[P] Periodic";
CM_ SG_ 2164279810 IMU_YawRtVal "IMU_YawRateValue ##2G##YRS - YRS11 - CR_Yrs_Yr";
CM_ SG_ 2164279810 IMU_LatAccelVal "IMU_LateralAccelerationValue ##2G##YRS - YRS11 - CR_Yrs_LatAc";
CM_ SG_ 2164279810 IMU_LongAccelVal "IMU_LongitudinalAccelerationValue ##2G##YRS - YRS12 - CR_Yrs_LongAc";
CM_ SG_ 2164279810 IMU_SnsrTempVal "IMU_SensorTemperatureValue ##2G##YRS - YRS12 - YRS_Temp";
CM_ BO_ 2164279811 "[P] Periodic";
CM_ SG_ 2164279811 IMU_SeralNumVal "IMU_SerialNumberValue ##2G##YRS - YRS13 - YRS_SeralNo";
CM_ BO_ 2164279812 "[P] Periodic";
CM_ SG_ 2164279812 IMU_RollRtVal "IMU_Roll rate signal value";
CM_ SG_ 2164279812 IMU_VerAccelVal "IMU_Vertial Acceleration value";
CM_ BO_ 939 "[P] Periodic";
CM_ SG_ 939 PSB_Crc1Val "PSB_CyclicRedundancyCheck1Value";
CM_ SG_ 939 PSB_AlvCnt1Val "PSB_AliveCounter1Value";
CM_ SG_ 939 PSB_LHFlrSta "PSB_LeftHandedFailureStatus";
CM_ SG_ 939 PSB_LHActvSta "PSB_LeftHandedActiveStatus";
CM_ SG_ 939 PSB_RHFlrSta "PSB_RightHandedFailureStatus";
CM_ SG_ 939 PSB_RHActvSta "PSB_RightHandedActiveStatus";
CM_ SG_ 939 PSB_ActForAcu "PSB_ActiveForAcu";
CM_ SG_ 939 PSB_HapticWarnSta "PSB_Haptic_Warning_Status";
CM_ SG_ 939 PSB_RHActForPss "PSB_RightHandedActiveStatus_forPss";
CM_ SG_ 939 PSB_LHActForPss "PSB_LeftHandedActiveStatus_forPss";
CM_ BO_ 934 "[PE] Periodic and On Event";
CM_ SG_ 934 PTGM_Crc1Val "PTGM_CyclicRedundancyCheck1Value";
CM_ SG_ 934 PTGM_AlvCnt1Val "PTGM_AliveCounter1Value";
CM_ SG_ 934 PTGM_HazardSta "PTGM_HazardStatus";
CM_ SG_ 934 PTGM_ModSta "PTGM_ModuleStatus";
CM_ SG_ 934 PTGM_MovSta "PTGM_MovingStatus";
CM_ SG_ 934 PTGM_OptTyp "PTGM_OptionType";
CM_ SG_ 934 PTGM_ReleaseRlySta "PTGM_ReleaseRelayStatus";
CM_ SG_ 934 PTGM_TrnkLkSwSta "PTGM_TrunkLockSwitchStatus";
CM_ SG_ 934 PTGM_UsmSetSta "PTGM_UsmSettingStatus";
CM_ SG_ 934 PTGM_FobSrch_Req "FOB Search Request";
CM_ SG_ 934 PTGM_TlgtAwayCloseRValue "PTGM_TailgateAwayCloseRValue";
CM_ SG_ 934 PTGM_TrnkTlgtOption "PTGM_TrnkTlgtOption";
CM_ SG_ 934 PTGM_LatchType "PTGM_LatchType";
CM_ BO_ 1807 "[TP] Transport Protocol";
CM_ BO_ 862 "[PE] Periodic and On Event";
CM_ SG_ 862 SBCM_RL_Crc1Val "SBCM_RL_CyclicRedundancyCheck1Value";
CM_ SG_ 862 RL_CrashUnlockCmd "Rear Lefr Crash Unlock Command";
CM_ SG_ 862 SBCM_RL_AlvCnt1Val "SBCM_RL_AliveCounter1Value";
CM_ SG_ 862 Warn_RrLftDrSwSta_SBCM "Warn_RearLeftDoorSwitchStatus ##2G## -  - C_RLDrSw,CF_Gway_RLDrSw,Warn_RrLftDrSwSta";
CM_ SG_ 862 DoorLock_RrLftDrUnLkSta_SBCM "DoorLock_RearLeftDoorUnLockStatus ##2G## -  - C_RLUnlockState,DoorLock_RrLftDrUnLkSta";
CM_ SG_ 862 RL_SEAActivated "RearLeftSEAActivated";
CM_ SG_ 862 RL_SEAWarn "Rear Left SEA Warning";
CM_ BO_ 929 "[PE] Periodic and On Event";
BA_DEF_ BO_ "DiagState" ENUM "No","Yes" ;
BA_DEF_ BO_ "DiagResponse" ENUM "No","Yes" ;
BA_DEF_ BO_ "DiagRequest" ENUM "No","Yes" ;
BA_DEF_ BO_ "TpMessage" ENUM "No","Yes" ;
BA_DEF_ BO_ "UsrMsgIDSforwardDeviation" INT 0 100 ;
BA_DEF_ BO_ "UsrMsgIDSbackwardDeviation" INT 50 1000 ;
BA_DEF_ BO_ "GenMsgCycleTime" INT 0 2000 ;
BA_DEF_ BO_ "GenMsgStartDelayTime" INT 0 2000 ;
BA_DEF_ BO_ "GenMsgSendType" ENUM "Cyclic","NoMsgSendType" ;
BA_DEF_ BO_ "GenMsgCycleTimeFast" INT 0 500 ;
BA_DEF_ BO_ "GenMsgDelayTime" INT 0 20 ;
BA_DEF_ BO_ "GenMsgILSupport" ENUM "No","Yes" ;
BA_DEF_ BO_ "GenMsgNrOfRepetition" INT 0 3 ;
BA_DEF_ BO_ "NmMessage" ENUM "No","Yes" ;
BA_DEF_ BO_ "NWM-Botschaft" ENUM "No","Yes" ;
BA_DEF_ BO_ "TpTxIndex" INT 0 255 ;
BA_DEF_ BO_ "VFrameFormat" ENUM "StandardCAN","ExtendedCAN","reserved","reserved","reserved","reserved","reserved","reserved","reserved","reserved","reserved","reserved","reserved","reserved","StandardCAN_FD","ExtendedCAN_FD" ;
BA_DEF_ SG_ "UserSigValidity" ENUM "B+","ACC","IG","IG1","IG2","IG3","IG1 or IG2","IG1 or IG3","Undef" ;
BA_DEF_ SG_ "TimeoutValue" STRING ;
BA_DEF_ SG_ "UsrSigPurpose" ENUM "Undef","FN","DIAG","DIAG(Req)","DIAG(Res)","DIAG(Phy)","DEV","CCP(Req)","CCP(Res)","NM","TP" ;
BA_DEF_ SG_ "GenSigStartValue" INT 0 1215752192 ;
BA_DEF_ SG_ "NetworkRequest" ENUM "Yes","No" ;
BA_DEF_ SG_ "NetworkRequestHoldingTime" INT 0 65535 ;
BA_DEF_ SG_ "Description" STRING ;
BA_DEF_ SG_ "Version" STRING ;
BA_DEF_ SG_ "GenSigEnvVarType" ENUM "Int","Float","Undef" ;
BA_DEF_ SG_ "GenSigSendType" ENUM "Cyclic","OnWrite","OnWriteWithRepetition","OnChange","OnChangeWithRepetition","IfActive","IfActiveWithRepetition","NoSigSendType","OnChangeAndIfActive","OnChangeAndIfActiveWithRepetition" ;
BA_DEF_ SG_ "GwSigLatencyTime" INT 0 65536 ;
BA_DEF_ SG_ "GwSigMissingSourceType" ENUM "Undef","OldValue","DefaultValue","InitialValue" ;
BA_DEF_ SG_ "NWM-WakeupAllowed" ENUM "<n.a.>" ;
BA_DEF_ SG_ "RoutingFactor" INT 1 1215752192 ;
BA_DEF_REL_ BU_SG_REL_ "GenSigTimeoutTime" INT 0 7000 ;
BA_DEF_DEF_ "DiagState" "No" ;
BA_DEF_DEF_ "DiagResponse" "No" ;
BA_DEF_DEF_ "DiagRequest" "No" ;
BA_DEF_DEF_ "TpMessage" "No" ;
BA_DEF_DEF_ "UsrMsgIDSforwardDeviation" 10 ;
BA_DEF_DEF_ "UsrMsgIDSbackwardDeviation" 100 ;
BA_DEF_DEF_ "GenMsgCycleTime" 200 ;
BA_DEF_DEF_ "GenMsgStartDelayTime" 0 ;
BA_DEF_DEF_ "GenMsgSendType" "NoMsgSendType" ;
BA_DEF_DEF_ "GenMsgCycleTimeFast" 40 ;
BA_DEF_DEF_ "GenMsgDelayTime" 20 ;
BA_DEF_DEF_ "GenMsgILSupport" "Yes" ;
BA_DEF_DEF_ "GenMsgNrOfRepetition" 3 ;
BA_DEF_DEF_ "NmMessage" "No" ;
BA_DEF_DEF_ "NWM-Botschaft" "No" ;
BA_DEF_DEF_ "TpTxIndex" 0 ;
BA_DEF_DEF_ "VFrameFormat" "StandardCAN" ;
BA_DEF_DEF_ "UserSigValidity" "IG" ;
BA_DEF_DEF_ "TimeoutValue" "" ;
BA_DEF_DEF_ "UsrSigPurpose" "FN" ;
BA_DEF_DEF_ "GenSigStartValue" 0 ;
BA_DEF_DEF_ "NetworkRequest" "No" ;
BA_DEF_DEF_ "NetworkRequestHoldingTime" 0 ;
BA_DEF_DEF_ "Description" "" ;
BA_DEF_DEF_ "Version" "" ;
BA_DEF_DEF_ "GenSigEnvVarType" "Undef" ;
BA_DEF_DEF_ "GenSigSendType" "NoSigSendType" ;
BA_DEF_DEF_ "GwSigLatencyTime" 40 ;
BA_DEF_DEF_ "GwSigMissingSourceType" "Undef" ;
BA_DEF_DEF_ "NWM-WakeupAllowed" "<n.a.>" ;
BA_DEF_DEF_ "RoutingFactor" 1 ;
BA_DEF_DEF_REL_ "GenSigTimeoutTime" 500 ;
BA_ "GenMsgSendType" BO_ 2281835009 0;
BA_ "GenMsgCycleTime" BO_ 2281835009 100;
BA_ "GenMsgCycleTimeFast" BO_ 2281835009 0;
BA_ "GenMsgNrOfRepetition" BO_ 2281835009 0;
BA_ "VFrameFormat" BO_ 2281835009 1;
BA_ "Description" SG_ 2281835009 ACU_Crc1Val "The data area for CRC calculation is based on the data length (DLC) of the message DB.

The CRC shall be calculated over the entire data block (excluding the CRC bytes) including the user data, alive counter and Data ID

 

- CRC Polynomial (0x1021) , Initial Value : 0xFFFF, XOR value : 0x0000, Data ID : Message ID + 0xF800 

- The initial value is for CRC calculation and the message should be sent with the calculated result value. 

- The mathematical expression to 16 bit CRC polynomial is given here. G(x) = x16 + x12 + x5 + 1";
BA_ "GenSigStartValue" SG_ 2281835009 ACU_Crc1Val 65535;
BA_ "UserSigValidity" SG_ 2281835009 ACU_Crc1Val 3;
BA_REL_ "GenSigTimeoutTime" BU_SG_REL_ OHCL SG_ 2281835009 ACU_Crc1Val 1500;
BA_ "Version" SG_ 2281835009 ACU_Crc1Val "18.11.08";
BA_ "Description" SG_ 2281835009 ACU_AlvCnt1Val "For the first transmission request for a data element the counter shall be initialized with 0 and shall be incremented by 1 for every subsequent send request. 

When the counter reaches the maximum value(0xFF), then it shall restart with 0 for the next send request";
BA_ "UserSigValidity" SG_ 2281835009 ACU_AlvCnt1Val 3;
BA_REL_ "GenSigTimeoutTime" BU_SG_REL_ OHCL SG_ 2281835009 ACU_AlvCnt1Val 1500;
BA_ "Version" SG_ 2281835009 ACU_AlvCnt1Val "18.11.08";
BA_ "Description" SG_ 2281835009 ACU_SysWrngLmpDis "This signal means information regarding ACU diagnostic information result & discrimination.



1) Default value : 0x1

2) Default value Transmit condition

    - When the input condition is not determined.

    - When the input condition is not supported.";
BA_ "GenSigStartValue" SG_ 2281835009 ACU_SysWrngLmpDis 1;
BA_ "UserSigValidity" SG_ 2281835009 ACU_SysWrngLmpDis 3;
BA_ "Version" SG_ 2281835009 ACU_SysWrngLmpDis "18.11.05";
BA_ "Description" SG_ 2281835009 ACU_TlltlLmpDis "This signal means information regarding Occupant status.

0) 00Xb : X position means PAB OFF Lamp indication. When this bit set as 1 PAB OFF lamp turns ON. 

    0Y0b : Y position means PAB ON Lamp indication. When this bit set as 1 PAB ON lamp turns ON.



1) Default value : 0x2 (PAB ON Lamp on, PAB OFF Lamp off,)

2) Default value Transmit condition

    - When the input condition is not determined.

    - When the input condition is not supported.";
BA_ "GenSigStartValue" SG_ 2281835009 ACU_TlltlLmpDis 3;
BA_ "UserSigValidity" SG_ 2281835009 ACU_TlltlLmpDis 3;
BA_REL_ "GenSigTimeoutTime" BU_SG_REL_ OHCL SG_ 2281835009 ACU_TlltlLmpDis 1500;
BA_ "Version" SG_ 2281835009 ACU_TlltlLmpDis "20.03.02";
BA_ "Description" SG_ 2281835009 ACU_OdsIDReq "It s a Request to send ODS Identifier. If the Bit is equal to `0` the ODS-B module will transmit the ODS identifier message. ACU sets ¡°ODS ID Received¡± to ¡®1¡¯ after getting the valid ODS ID two times.



1) Default value : 0x0

2) Default value Transmit condition

    - When the input condition is not determined.

    - When the input condition is not supported.";
BA_ "UserSigValidity" SG_ 2281835009 ACU_OdsIDReq 3;
BA_ "Version" SG_ 2281835009 ACU_OdsIDReq "17.12.00";
BA_ "Description" SG_ 2281835009 SeatBelt_PassBcklFltSta "Information of Passenger Seat Belt Buckle switch Fault condition.



1) Default value : 0x0

2) Default value Transmit condition

    - When the input condition is not supported.

¡ØThis signal is valid (updated) only that buckle is connected to ACU directly, 

otherwise transmitted as default value.";
BA_ "UserSigValidity" SG_ 2281835009 SeatBelt_PassBcklFltSta 3;
BA_REL_ "GenSigTimeoutTime" BU_SG_REL_ PSB SG_ 2281835009 SeatBelt_PassBcklFltSta 1500;
BA_ "Version" SG_ 2281835009 SeatBelt_PassBcklFltSta "19.01.08";
BA_ "Description" SG_ 2281835009 SeatBelt_DrvrBcklFltSta "Information of Driver Seat Belt Buckle switch Fault condition.



1) Default value : 0x0

2) Default value Transmit condition

    - When the input condition is not supported.

¡ØThis signal is valid (updated) only that buckle is connected to ACU directly, 

otherwise transmitted as default value.";
BA_ "UserSigValidity" SG_ 2281835009 SeatBelt_DrvrBcklFltSta 3;
BA_REL_ "GenSigTimeoutTime" BU_SG_REL_ PSB SG_ 2281835009 SeatBelt_DrvrBcklFltSta 1500;
BA_ "Version" SG_ 2281835009 SeatBelt_DrvrBcklFltSta "19.01.08";
BA_ "Description" SG_ 2281835009 SeatBelt_PassBcklSta "Information of Passenger Seat Belt Buckle switch Status, whether its Latched or Not .



1) Default value : 0x1

2) Default value Transmit condition

    - When the input condition is not determined.

    - When the input condition is not supported.

¡ØThis signal is valid (updated) only that buckle is connected to ACU directly, 

otherwise transmitted as default value.";
BA_ "GenSigStartValue" SG_ 2281835009 SeatBelt_PassBcklSta 1;
BA_ "UserSigValidity" SG_ 2281835009 SeatBelt_PassBcklSta 3;
BA_REL_ "GenSigTimeoutTime" BU_SG_REL_ PSB SG_ 2281835009 SeatBelt_PassBcklSta 1500;
BA_REL_ "GenSigTimeoutTime" BU_SG_REL_ APSU SG_ 2281835009 SeatBelt_PassBcklSta 1500;
BA_REL_ "GenSigTimeoutTime" BU_SG_REL_ ATS SG_ 2281835009 SeatBelt_PassBcklSta 1500;
BA_ "Version" SG_ 2281835009 SeatBelt_PassBcklSta "19.01.08";
BA_ "Description" SG_ 2281835009 SeatBelt_DrvrBcklSta "Information of Driver Seat Belt Buckle switch Status, whether its Latched or Not.



1) Default value : 0x1

2) Default value Transmit condition

    - When the input condition is not determined.

    - When the input condition is not supported.

¡ØThis signal is valid (updated) only that buckle is connected to ACU directly, 

otherwise transmitted as default value.";
BA_ "GenSigStartValue" SG_ 2281835009 SeatBelt_DrvrBcklSta 1;
BA_ "UserSigValidity" SG_ 2281835009 SeatBelt_DrvrBcklSta 3;
BA_REL_ "GenSigTimeoutTime" BU_SG_REL_ PSB SG_ 2281835009 SeatBelt_DrvrBcklSta 1500;
BA_ "Version" SG_ 2281835009 SeatBelt_DrvrBcklSta "19.01.08";
BA_ "Description" SG_ 2281835009 ACU_DiagTrblCodVal "This signal means information regarding a diagnostic trouble code number.



1) Default value : 0x0

2) Default value Transmit condition

    - When Fault does not exist.";
BA_ "UserSigValidity" SG_ 2281835009 ACU_DiagTrblCodVal 3;
BA_ "Version" SG_ 2281835009 ACU_DiagTrblCodVal "17.12.00";
BA_ "Description" SG_ 2281835009 ACU_FltNumVal "This signal means information regarding number of fault in ACU memory, including active and historic faults.



1) Default value : 0x0

2) Default value Transmit condition

    - When Fault does not exist.";
BA_ "UserSigValidity" SG_ 2281835009 ACU_FltNumVal 3;
BA_ "Version" SG_ 2281835009 ACU_FltNumVal "17.12.00";
BA_ "GenMsgSendType" BO_ 2281835010 0;
BA_ "GenMsgCycleTime" BO_ 2281835010 100;
BA_ "GenMsgCycleTimeFast" BO_ 2281835010 0;
BA_ "GenMsgNrOfRepetition" BO_ 2281835010 0;
BA_ "VFrameFormat" BO_ 2281835010 1;
BA_ "Description" SG_ 2281835010 ACU_ActvFltSta "This signal means information regarding fault status, whether it is an active fault or not.



1) Default value : 0x2

2) Default value Transmit condition

    - When the input condition is not supported.";
BA_ "GenSigStartValue" SG_ 2281835010 ACU_ActvFltSta 2;
BA_ "UserSigValidity" SG_ 2281835010 ACU_ActvFltSta 3;
BA_ "Version" SG_ 2281835010 ACU_ActvFltSta "17.12.00";
BA_ "Description" SG_ 2281835010 ACU_NumOfEvtTrigVal "This signal is incremented by one each time when ACU meet EDR trigger condition

The last value is kept in the next cycle.



1) Value in EOL : always 0x0";
BA_ "UserSigValidity" SG_ 2281835010 ACU_NumOfEvtTrigVal 3;
BA_ "Version" SG_ 2281835010 ACU_NumOfEvtTrigVal "18.04.00";
BA_ "Description" SG_ 2281835010 ACU_SdArbgExtTyp "This signal does not specify the types or variations of the side restraints such as the front side airbag only or both the front and the rear side airbag. If any side restraint is equipped, the signal responds as 'exists'.

¡ØInitial value shall be actual value.";
BA_ "UserSigValidity" SG_ 2281835010 ACU_SdArbgExtTyp 3;
BA_ "Version" SG_ 2281835010 ACU_SdArbgExtTyp "19.07.06";
BA_ "Description" SG_ 2281835010 ACU_PassArbg_SW_Sta "This signal indicates that the state of passenger airbag on/off switch

¡ØBefore EOL : 0x0(NOT APPLIED) transmit,    (Default value : 0x0)";
BA_ "UserSigValidity" SG_ 2281835010 ACU_PassArbg_SW_Sta 3;
BA_ "Version" SG_ 2281835010 ACU_PassArbg_SW_Sta "20.08.07";
BA_ "Description" SG_ 2281835010 ACU_HDPSpprtSWVer "This signal means the software version information of signals related to HDP cooperative control.

If the ACU signal related to HDP cooperative control is modified, this signal is changed.

0x0 : Not Support(intit)

After IGN On, 0x0 is transmitted in the ACU initialization step.

The effective value of ACU_HDPSpprtSWVer is transmitted within1 second after IGN On.";
BA_ "UserSigValidity" SG_ 2281835010 ACU_HDPSpprtSWVer 3;
BA_ "Version" SG_ 2281835010 ACU_HDPSpprtSWVer "21.12.07";
BA_ "Description" SG_ 2281835010 ACU_EmerModSta "This signal is set when  ACU detect Emergency mode status 

 (e.g : During driving, IGN1+ is disconnected)  

1)Value in EOL :  always 0x0 

2)Emergency mode details in ES95910-02";
BA_ "UserSigValidity" SG_ 2281835010 ACU_EmerModSta 3;
BA_ "Version" SG_ 2281835010 ACU_EmerModSta "18.04.00";
BA_ "Description" SG_ 2281835010 ACU_EvtTrigSta "This signal is set when  ACU meet EDR trigger condition.

Event trigger condition is same as EDR Regulation definition(49 CFR PART 563)

This signal is set to '1'  then kept for the current IGN cycle as '1'



1)Value in EOL :  always 0x0";
BA_ "UserSigValidity" SG_ 2281835010 ACU_EvtTrigSta 3;
BA_ "Version" SG_ 2281835010 ACU_EvtTrigSta "18.04.00";
BA_ "Description" SG_ 2281835010 ACU_NumOfEmerModVal "This signal is incremented by one each time when ACU enters into emergency mode.

The last value is kept in the next cycle.



1) Value in EOL : always 0x0

2)Emergency mode details in ES95910-02";
BA_ "UserSigValidity" SG_ 2281835010 ACU_NumOfEmerModVal 3;
BA_ "Version" SG_ 2281835010 ACU_NumOfEmerModVal "18.04.00";
BA_ "GenMsgSendType" BO_ 2239851010 0;
BA_ "GenMsgCycleTime" BO_ 2239851010 100;
BA_ "GenMsgCycleTimeFast" BO_ 2239851010 0;
BA_ "GenMsgNrOfRepetition" BO_ 2239851010 0;
BA_ "VFrameFormat" BO_ 2239851010 1;
BA_ "Description" SG_ 2239851010 RSPA_Var "RSPA variation";
BA_ "UserSigValidity" SG_ 2239851010 RSPA_Var 3;
BA_ "RoutingFactor" SG_ 2239851010 RSPA_Var 5;
BA_ "Version" SG_ 2239851010 RSPA_Var "19.08.08";
BA_ "Description" SG_ 2239851010 RSPA_Sta "ÇöÀç RSPAÀÇ »óÅÂ";
BA_ "GenSigStartValue" SG_ 2239851010 RSPA_Sta 1;
BA_ "UserSigValidity" SG_ 2239851010 RSPA_Sta 3;
BA_ "RoutingFactor" SG_ 2239851010 RSPA_Sta 5;
BA_ "Version" SG_ 2239851010 RSPA_Sta "19.03.11";
BA_ "Description" SG_ 2239851010 RSPA_Actv "RSPA's activation information";
BA_ "UserSigValidity" SG_ 2239851010 RSPA_Actv 3;
BA_ "RoutingFactor" SG_ 2239851010 RSPA_Actv 5;
BA_ "Version" SG_ 2239851010 RSPA_Actv "17.11.00";
BA_ "Description" SG_ 2239851010 RSPA_EvasiveStrBtnDis "Display evasive steering on/off button (RSPA II)";
BA_ "UserSigValidity" SG_ 2239851010 RSPA_EvasiveStrBtnDis 3;
BA_ "RoutingFactor" SG_ 2239851010 RSPA_EvasiveStrBtnDis 5;
BA_ "Version" SG_ 2239851010 RSPA_EvasiveStrBtnDis "19.08.08";
BA_ "GenMsgSendType" BO_ 2239851012 0;
BA_ "GenMsgCycleTime" BO_ 2239851012 100;
BA_ "GenMsgCycleTimeFast" BO_ 2239851012 0;
BA_ "GenMsgNrOfRepetition" BO_ 2239851012 0;
BA_ "VFrameFormat" BO_ 2239851012 1;
BA_ "Description" SG_ 2239851012 RSPA_DCTTrgtTqVal "RSPA request DCT torque value (Nm)

Init value : 00h

If MSB is 1, this signal is - value.

else, this signal is +value.

0~10bit is used for absolute value.";
BA_ "UserSigValidity" SG_ 2239851012 RSPA_DCTTrgtTqVal 3;
BA_ "RoutingFactor" SG_ 2239851012 RSPA_DCTTrgtTqVal 5;
BA_ "Version" SG_ 2239851012 RSPA_DCTTrgtTqVal "19.06.00";
BA_ "Description" SG_ 2239851012 RSPA_HdLmpReq "Head lamp request of RSPA";
BA_ "UserSigValidity" SG_ 2239851012 RSPA_HdLmpReq 3;
BA_ "RoutingFactor" SG_ 2239851012 RSPA_HdLmpReq 5;
BA_ "Version" SG_ 2239851012 RSPA_HdLmpReq "20.10.00";
BA_ "Description" SG_ 2239851012 RSPA_OSMirFoldReq "OS Mirror folding/unfolding request of RSPA";
BA_ "UserSigValidity" SG_ 2239851012 RSPA_OSMirFoldReq 3;
BA_ "RoutingFactor" SG_ 2239851012 RSPA_OSMirFoldReq 5;
BA_ "Version" SG_ 2239851012 RSPA_OSMirFoldReq "19.08.08";
BA_ "GenMsgCycleTime" BO_ 1806 0;
BA_ "GenMsgCycleTimeFast" BO_ 1806 0;
BA_ "GenMsgNrOfRepetition" BO_ 1806 0;
BA_ "DiagResponse" BO_ 1806 1;
BA_ "GenMsgILSupport" BO_ 1806 0;
BA_ "TpMessage" BO_ 1806 1;
BA_ "TpTxIndex" BO_ 1806 106;
BA_ "Description" SG_ 1806 AHV_SHVU_FR_GST_Byte0 "TP Index : 106";
BA_ "UsrSigPurpose" SG_ 1806 AHV_SHVU_FR_GST_Byte0 4;
BA_ "UserSigValidity" SG_ 1806 AHV_SHVU_FR_GST_Byte0 0;
BA_REL_ "GenSigTimeoutTime" BU_SG_REL_ CGW_CCU SG_ 1806 AHV_SHVU_FR_GST_Byte0 0;
BA_ "NetworkRequest" SG_ 1806 AHV_SHVU_FR_GST_Byte0 0;
BA_ "NetworkRequestHoldingTime" SG_ 1806 AHV_SHVU_FR_GST_Byte0 5000;
BA_ "Version" SG_ 1806 AHV_SHVU_FR_GST_Byte0 "21.02.04";
BA_ "Description" SG_ 1806 AHV_SHVU_FR_GST_Byte2 "TP Index : 106";
BA_ "UsrSigPurpose" SG_ 1806 AHV_SHVU_FR_GST_Byte2 4;
BA_ "UserSigValidity" SG_ 1806 AHV_SHVU_FR_GST_Byte2 0;
BA_REL_ "GenSigTimeoutTime" BU_SG_REL_ CGW_CCU SG_ 1806 AHV_SHVU_FR_GST_Byte2 0;
BA_ "NetworkRequest" SG_ 1806 AHV_SHVU_FR_GST_Byte2 0;
BA_ "NetworkRequestHoldingTime" SG_ 1806 AHV_SHVU_FR_GST_Byte2 5000;
BA_ "Version" SG_ 1806 AHV_SHVU_FR_GST_Byte2 "21.02.04";
BA_ "Description" SG_ 1806 AHV_SHVU_FR_GST_Byte3 "TP Index : 106";
BA_ "UsrSigPurpose" SG_ 1806 AHV_SHVU_FR_GST_Byte3 4;
BA_ "UserSigValidity" SG_ 1806 AHV_SHVU_FR_GST_Byte3 0;
BA_REL_ "GenSigTimeoutTime" BU_SG_REL_ CGW_CCU SG_ 1806 AHV_SHVU_FR_GST_Byte3 0;
BA_ "NetworkRequest" SG_ 1806 AHV_SHVU_FR_GST_Byte3 0;
BA_ "NetworkRequestHoldingTime" SG_ 1806 AHV_SHVU_FR_GST_Byte3 5000;
BA_ "Version" SG_ 1806 AHV_SHVU_FR_GST_Byte3 "21.02.04";
BA_ "Description" SG_ 1806 AHV_SHVU_FR_GST_Byte4 "TP Index : 106";
BA_ "UsrSigPurpose" SG_ 1806 AHV_SHVU_FR_GST_Byte4 4;
BA_ "UserSigValidity" SG_ 1806 AHV_SHVU_FR_GST_Byte4 0;
BA_REL_ "GenSigTimeoutTime" BU_SG_REL_ CGW_CCU SG_ 1806 AHV_SHVU_FR_GST_Byte4 0;
BA_ "NetworkRequest" SG_ 1806 AHV_SHVU_FR_GST_Byte4 0;
BA_ "NetworkRequestHoldingTime" SG_ 1806 AHV_SHVU_FR_GST_Byte4 5000;
BA_ "Version" SG_ 1806 AHV_SHVU_FR_GST_Byte4 "21.02.04";
BA_ "Description" SG_ 1806 AHV_SHVU_FR_GST_Byte5 "TP Index : 106";
BA_ "UsrSigPurpose" SG_ 1806 AHV_SHVU_FR_GST_Byte5 4;
BA_ "UserSigValidity" SG_ 1806 AHV_SHVU_FR_GST_Byte5 0;
BA_REL_ "GenSigTimeoutTime" BU_SG_REL_ CGW_CCU SG_ 1806 AHV_SHVU_FR_GST_Byte5 0;
BA_ "NetworkRequest" SG_ 1806 AHV_SHVU_FR_GST_Byte5 0;
BA_ "NetworkRequestHoldingTime" SG_ 1806 AHV_SHVU_FR_GST_Byte5 5000;
BA_ "Version" SG_ 1806 AHV_SHVU_FR_GST_Byte5 "21.02.04";
BA_ "Description" SG_ 1806 AHV_SHVU_FR_GST_Byte6 "TP Index : 106";
BA_ "UsrSigPurpose" SG_ 1806 AHV_SHVU_FR_GST_Byte6 4;
BA_ "UserSigValidity" SG_ 1806 AHV_SHVU_FR_GST_Byte6 0;
BA_REL_ "GenSigTimeoutTime" BU_SG_REL_ CGW_CCU SG_ 1806 AHV_SHVU_FR_GST_Byte6 0;
BA_ "NetworkRequest" SG_ 1806 AHV_SHVU_FR_GST_Byte6 0;
BA_ "NetworkRequestHoldingTime" SG_ 1806 AHV_SHVU_FR_GST_Byte6 5000;
BA_ "Version" SG_ 1806 AHV_SHVU_FR_GST_Byte6 "21.02.04";
BA_ "Description" SG_ 1806 AHV_SHVU_FR_GST_Byte7 "TP Index : 106";
BA_ "UsrSigPurpose" SG_ 1806 AHV_SHVU_FR_GST_Byte7 4;
BA_ "UserSigValidity" SG_ 1806 AHV_SHVU_FR_GST_Byte7 0;
BA_REL_ "GenSigTimeoutTime" BU_SG_REL_ CGW_CCU SG_ 1806 AHV_SHVU_FR_GST_Byte7 0;
BA_ "NetworkRequest" SG_ 1806 AHV_SHVU_FR_GST_Byte7 0;
BA_ "NetworkRequestHoldingTime" SG_ 1806 AHV_SHVU_FR_GST_Byte7 5000;
BA_ "Version" SG_ 1806 AHV_SHVU_FR_GST_Byte7 "21.02.04";
BA_ "Description" SG_ 1806 AHV_SHVU_FR_GST_Byte1 "TP Index : 106";
BA_ "UsrSigPurpose" SG_ 1806 AHV_SHVU_FR_GST_Byte1 4;
BA_ "UserSigValidity" SG_ 1806 AHV_SHVU_FR_GST_Byte1 0;
BA_REL_ "GenSigTimeoutTime" BU_SG_REL_ CGW_CCU SG_ 1806 AHV_SHVU_FR_GST_Byte1 0;
BA_ "NetworkRequest" SG_ 1806 AHV_SHVU_FR_GST_Byte1 0;
BA_ "NetworkRequestHoldingTime" SG_ 1806 AHV_SHVU_FR_GST_Byte1 5000;
BA_ "Version" SG_ 1806 AHV_SHVU_FR_GST_Byte1 "21.02.04";
BA_ "GenMsgCycleTime" BO_ 1484 0;
BA_ "GenMsgCycleTimeFast" BO_ 1484 0;
BA_ "GenMsgNrOfRepetition" BO_ 1484 0;
BA_ "DiagResponse" BO_ 1484 1;
BA_ "GenMsgILSupport" BO_ 1484 0;
BA_ "TpMessage" BO_ 1484 1;
BA_ "TpTxIndex" BO_ 1484 216;
BA_ "Description" SG_ 1484 ASAU_GST_Byte0 "TP Index : 216";
BA_ "UsrSigPurpose" SG_ 1484 ASAU_GST_Byte0 4;
BA_ "UserSigValidity" SG_ 1484 ASAU_GST_Byte0 0;
BA_REL_ "GenSigTimeoutTime" BU_SG_REL_ CGW_CCU SG_ 1484 ASAU_GST_Byte0 0;
BA_ "NetworkRequest" SG_ 1484 ASAU_GST_Byte0 0;
BA_ "NetworkRequestHoldingTime" SG_ 1484 ASAU_GST_Byte0 5000;
BA_ "Version" SG_ 1484 ASAU_GST_Byte0 "21.02.04";
BA_ "Description" SG_ 1484 ASAU_GST_Byte2 "TP Index : 216";
BA_ "UsrSigPurpose" SG_ 1484 ASAU_GST_Byte2 4;
BA_ "UserSigValidity" SG_ 1484 ASAU_GST_Byte2 0;
BA_REL_ "GenSigTimeoutTime" BU_SG_REL_ CGW_CCU SG_ 1484 ASAU_GST_Byte2 0;
BA_ "NetworkRequest" SG_ 1484 ASAU_GST_Byte2 0;
BA_ "NetworkRequestHoldingTime" SG_ 1484 ASAU_GST_Byte2 5000;
BA_ "Version" SG_ 1484 ASAU_GST_Byte2 "21.02.04";
BA_ "Description" SG_ 1484 ASAU_GST_Byte3 "TP Index : 216";
BA_ "UsrSigPurpose" SG_ 1484 ASAU_GST_Byte3 4;
BA_ "UserSigValidity" SG_ 1484 ASAU_GST_Byte3 0;
BA_REL_ "GenSigTimeoutTime" BU_SG_REL_ CGW_CCU SG_ 1484 ASAU_GST_Byte3 0;
BA_ "NetworkRequest" SG_ 1484 ASAU_GST_Byte3 0;
BA_ "NetworkRequestHoldingTime" SG_ 1484 ASAU_GST_Byte3 5000;
BA_ "Version" SG_ 1484 ASAU_GST_Byte3 "21.02.04";
BA_ "Description" SG_ 1484 ASAU_GST_Byte4 "TP Index : 216";
BA_ "UsrSigPurpose" SG_ 1484 ASAU_GST_Byte4 4;
BA_ "UserSigValidity" SG_ 1484 ASAU_GST_Byte4 0;
BA_REL_ "GenSigTimeoutTime" BU_SG_REL_ CGW_CCU SG_ 1484 ASAU_GST_Byte4 0;
BA_ "NetworkRequest" SG_ 1484 ASAU_GST_Byte4 0;
BA_ "NetworkRequestHoldingTime" SG_ 1484 ASAU_GST_Byte4 5000;
BA_ "Version" SG_ 1484 ASAU_GST_Byte4 "21.02.04";
BA_ "Description" SG_ 1484 ASAU_GST_Byte5 "TP Index : 216";
BA_ "UsrSigPurpose" SG_ 1484 ASAU_GST_Byte5 4;
BA_ "UserSigValidity" SG_ 1484 ASAU_GST_Byte5 0;
BA_REL_ "GenSigTimeoutTime" BU_SG_REL_ CGW_CCU SG_ 1484 ASAU_GST_Byte5 0;
BA_ "NetworkRequest" SG_ 1484 ASAU_GST_Byte5 0;
BA_ "NetworkRequestHoldingTime" SG_ 1484 ASAU_GST_Byte5 5000;
BA_ "Version" SG_ 1484 ASAU_GST_Byte5 "21.02.04";
BA_ "Description" SG_ 1484 ASAU_GST_Byte6 "TP Index : 216";
BA_ "UsrSigPurpose" SG_ 1484 ASAU_GST_Byte6 4;
BA_ "UserSigValidity" SG_ 1484 ASAU_GST_Byte6 0;
BA_REL_ "GenSigTimeoutTime" BU_SG_REL_ CGW_CCU SG_ 1484 ASAU_GST_Byte6 0;
BA_ "NetworkRequest" SG_ 1484 ASAU_GST_Byte6 0;
BA_ "NetworkRequestHoldingTime" SG_ 1484 ASAU_GST_Byte6 5000;
BA_ "Version" SG_ 1484 ASAU_GST_Byte6 "21.02.04";
BA_ "Description" SG_ 1484 ASAU_GST_Byte7 "TP Index : 216";
BA_ "UsrSigPurpose" SG_ 1484 ASAU_GST_Byte7 4;
BA_ "UserSigValidity" SG_ 1484 ASAU_GST_Byte7 0;
BA_REL_ "GenSigTimeoutTime" BU_SG_REL_ CGW_CCU SG_ 1484 ASAU_GST_Byte7 0;
BA_ "NetworkRequest" SG_ 1484 ASAU_GST_Byte7 0;
BA_ "NetworkRequestHoldingTime" SG_ 1484 ASAU_GST_Byte7 5000;
BA_ "Version" SG_ 1484 ASAU_GST_Byte7 "21.02.04";
BA_ "Description" SG_ 1484 ASAU_GST_Byte1 "TP Index : 216";
BA_ "UsrSigPurpose" SG_ 1484 ASAU_GST_Byte1 4;
BA_ "UserSigValidity" SG_ 1484 ASAU_GST_Byte1 0;
BA_REL_ "GenSigTimeoutTime" BU_SG_REL_ CGW_CCU SG_ 1484 ASAU_GST_Byte1 0;
BA_ "NetworkRequest" SG_ 1484 ASAU_GST_Byte1 0;
BA_ "NetworkRequestHoldingTime" SG_ 1484 ASAU_GST_Byte1 5000;
BA_ "Version" SG_ 1484 ASAU_GST_Byte1 "21.02.04";
BA_ "GenMsgSendType" BO_ 951 0;
BA_ "Description" SG_ 951 BLTN_CAM_RecSet_OWD "Record On/Off Set of On While Driving";
BA_ "GenSigSendType" SG_ 951 BLTN_CAM_RecSet_OWD 4;
BA_ "UserSigValidity" SG_ 951 BLTN_CAM_RecSet_OWD 0;
BA_REL_ "GenSigTimeoutTime" BU_SG_REL_ CGW_CCU SG_ 951 BLTN_CAM_RecSet_OWD 1500;
BA_ "Version" SG_ 951 BLTN_CAM_RecSet_OWD "21.05.02";
BA_ "Description" SG_ 951 BLTN_CAM_Set_Tim_Stm "Record Set of Date and Time Stamp";
BA_ "GenSigSendType" SG_ 951 BLTN_CAM_Set_Tim_Stm 4;
BA_ "UserSigValidity" SG_ 951 BLTN_CAM_Set_Tim_Stm 0;
BA_REL_ "GenSigTimeoutTime" BU_SG_REL_ CGW_CCU SG_ 951 BLTN_CAM_Set_Tim_Stm 1500;
BA_ "Version" SG_ 951 BLTN_CAM_Set_Tim_Stm "21.05.02";
BA_ "Description" SG_ 951 BLTN_CAM_Set_Spd_Stm "Record Set of Speed Stamp";
BA_ "GenSigSendType" SG_ 951 BLTN_CAM_Set_Spd_Stm 4;
BA_ "UserSigValidity" SG_ 951 BLTN_CAM_Set_Spd_Stm 0;
BA_REL_ "GenSigTimeoutTime" BU_SG_REL_ CGW_CCU SG_ 951 BLTN_CAM_Set_Spd_Stm 1500;
BA_ "Version" SG_ 951 BLTN_CAM_Set_Spd_Stm "21.11.07";
BA_ "Description" SG_ 951 BLTN_CAM_Set_Locatn_Stm "Record Set of Location Stamp";
BA_ "GenSigSendType" SG_ 951 BLTN_CAM_Set_Locatn_Stm 4;
BA_ "UserSigValidity" SG_ 951 BLTN_CAM_Set_Locatn_Stm 0;
BA_REL_ "GenSigTimeoutTime" BU_SG_REL_ CGW_CCU SG_ 951 BLTN_CAM_Set_Locatn_Stm 1500;
BA_ "Version" SG_ 951 BLTN_CAM_Set_Locatn_Stm "21.05.02";
BA_ "Description" SG_ 951 BLTN_CAM_Set_TrnSig_Stm "Record Set of Turn Signal Stamp";
BA_ "GenSigSendType" SG_ 951 BLTN_CAM_Set_TrnSig_Stm 4;
BA_ "UserSigValidity" SG_ 951 BLTN_CAM_Set_TrnSig_Stm 0;
BA_REL_ "GenSigTimeoutTime" BU_SG_REL_ CGW_CCU SG_ 951 BLTN_CAM_Set_TrnSig_Stm 1500;
BA_ "Version" SG_ 951 BLTN_CAM_Set_TrnSig_Stm "21.05.02";
BA_ "Description" SG_ 951 BLTN_CAM_Set_AclBrk_Stm "Record Set of Accelerator Brake Stamp";
BA_ "GenSigSendType" SG_ 951 BLTN_CAM_Set_AclBrk_Stm 4;
BA_ "UserSigValidity" SG_ 951 BLTN_CAM_Set_AclBrk_Stm 0;
BA_REL_ "GenSigTimeoutTime" BU_SG_REL_ CGW_CCU SG_ 951 BLTN_CAM_Set_AclBrk_Stm 1500;
BA_ "Version" SG_ 951 BLTN_CAM_Set_AclBrk_Stm "21.11.07";
BA_ "Description" SG_ 951 BLTN_CAM_RecSet_DEV "Record On/Off Set of Driving Event";
BA_ "GenSigSendType" SG_ 951 BLTN_CAM_RecSet_DEV 4;
BA_ "UserSigValidity" SG_ 951 BLTN_CAM_RecSet_DEV 0;
BA_REL_ "GenSigTimeoutTime" BU_SG_REL_ CGW_CCU SG_ 951 BLTN_CAM_RecSet_DEV 1500;
BA_ "Version" SG_ 951 BLTN_CAM_RecSet_DEV "21.05.02";
BA_ "Description" SG_ 951 BLTN_CAM_Set_GearPos_Stm "Record Set of Gear Position Stamp";
BA_ "GenSigSendType" SG_ 951 BLTN_CAM_Set_GearPos_Stm 4;
BA_ "UserSigValidity" SG_ 951 BLTN_CAM_Set_GearPos_Stm 0;
BA_REL_ "GenSigTimeoutTime" BU_SG_REL_ CGW_CCU SG_ 951 BLTN_CAM_Set_GearPos_Stm 1500;
BA_ "Version" SG_ 951 BLTN_CAM_Set_GearPos_Stm "21.05.02";
BA_ "Description" SG_ 951 BLTN_CAM_Set_EVSen_Stm "Record Set of Event Sensitivity Stamp";
BA_ "GenSigSendType" SG_ 951 BLTN_CAM_Set_EVSen_Stm 4;
BA_ "UserSigValidity" SG_ 951 BLTN_CAM_Set_EVSen_Stm 0;
BA_REL_ "GenSigTimeoutTime" BU_SG_REL_ CGW_CCU SG_ 951 BLTN_CAM_Set_EVSen_Stm 1500;
BA_ "Version" SG_ 951 BLTN_CAM_Set_EVSen_Stm "21.05.02";
BA_ "Description" SG_ 951 BLTN_CAM_Set_StrAngl_Stm "Record Set of Steering Angle Stamp";
BA_ "GenSigSendType" SG_ 951 BLTN_CAM_Set_StrAngl_Stm 4;
BA_ "UserSigValidity" SG_ 951 BLTN_CAM_Set_StrAngl_Stm 0;
BA_REL_ "GenSigTimeoutTime" BU_SG_REL_ CGW_CCU SG_ 951 BLTN_CAM_Set_StrAngl_Stm 1500;
BA_ "Version" SG_ 951 BLTN_CAM_Set_StrAngl_Stm "21.07.05";
BA_ "Description" SG_ 951 BLTN_CAM_Set_PrkTime "Parking Operation Setting Time, Resolution : hr";
BA_ "GenSigSendType" SG_ 951 BLTN_CAM_Set_PrkTime 4;
BA_ "UserSigValidity" SG_ 951 BLTN_CAM_Set_PrkTime 0;
BA_REL_ "GenSigTimeoutTime" BU_SG_REL_ CGW_CCU SG_ 951 BLTN_CAM_Set_PrkTime 1500;
BA_ "Version" SG_ 951 BLTN_CAM_Set_PrkTime "21.11.07";
BA_ "Description" SG_ 951 BLTN_CAM_Set_EV_BfrTime "Driving Event Time Setting - Before, Resolution : sec";
BA_ "GenSigSendType" SG_ 951 BLTN_CAM_Set_EV_BfrTime 4;
BA_ "UserSigValidity" SG_ 951 BLTN_CAM_Set_EV_BfrTime 0;
BA_REL_ "GenSigTimeoutTime" BU_SG_REL_ CGW_CCU SG_ 951 BLTN_CAM_Set_EV_BfrTime 1500;
BA_ "Version" SG_ 951 BLTN_CAM_Set_EV_BfrTime "21.05.02";
BA_ "Description" SG_ 951 BLTN_CAM_RecSet_OWP "Record On/Off Set of On While Parked, 0x0(Default) : Parking recording function not supported";
BA_ "GenSigSendType" SG_ 951 BLTN_CAM_RecSet_OWP 4;
BA_ "UserSigValidity" SG_ 951 BLTN_CAM_RecSet_OWP 0;
BA_REL_ "GenSigTimeoutTime" BU_SG_REL_ CGW_CCU SG_ 951 BLTN_CAM_RecSet_OWP 1500;
BA_ "Version" SG_ 951 BLTN_CAM_RecSet_OWP "21.05.02";
BA_ "Description" SG_ 951 BLTN_CAM_Set_EV_AftTime "Driving Event Time Setting - After, Resolution : sec";
BA_ "GenSigSendType" SG_ 951 BLTN_CAM_Set_EV_AftTime 4;
BA_ "UserSigValidity" SG_ 951 BLTN_CAM_Set_EV_AftTime 0;
BA_REL_ "GenSigTimeoutTime" BU_SG_REL_ CGW_CCU SG_ 951 BLTN_CAM_Set_EV_AftTime 1500;
BA_ "Version" SG_ 951 BLTN_CAM_Set_EV_AftTime "21.05.02";
BA_ "Description" SG_ 951 BLTN_CAM_Set_Drv_TML_Int "Record Set of Time-lapse Interval, Resolution : sec";
BA_ "GenSigSendType" SG_ 951 BLTN_CAM_Set_Drv_TML_Int 4;
BA_ "UserSigValidity" SG_ 951 BLTN_CAM_Set_Drv_TML_Int 0;
BA_REL_ "GenSigTimeoutTime" BU_SG_REL_ CGW_CCU SG_ 951 BLTN_CAM_Set_Drv_TML_Int 1500;
BA_ "Version" SG_ 951 BLTN_CAM_Set_Drv_TML_Int "21.05.02";
BA_ "Description" SG_ 951 BLTN_CAM_SenSet_DEV "Set of Event  Detection Sensitivity of Driving Mode";
BA_ "GenSigSendType" SG_ 951 BLTN_CAM_SenSet_DEV 4;
BA_ "UserSigValidity" SG_ 951 BLTN_CAM_SenSet_DEV 0;
BA_REL_ "GenSigTimeoutTime" BU_SG_REL_ CGW_CCU SG_ 951 BLTN_CAM_SenSet_DEV 1500;
BA_ "Version" SG_ 951 BLTN_CAM_SenSet_DEV "21.05.02";
BA_ "Description" SG_ 951 BLTN_CAM_SenSet_PEV "Set of Event  Detection Sensitivity of Parking Mode";
BA_ "GenSigSendType" SG_ 951 BLTN_CAM_SenSet_PEV 4;
BA_ "UserSigValidity" SG_ 951 BLTN_CAM_SenSet_PEV 0;
BA_REL_ "GenSigTimeoutTime" BU_SG_REL_ CGW_CCU SG_ 951 BLTN_CAM_SenSet_PEV 1500;
BA_ "Version" SG_ 951 BLTN_CAM_SenSet_PEV "21.05.02";
BA_ "Description" SG_ 951 BLTN_CAM_RecSet_PEV "Record Set of Parked Event, 0x0(Default) : Parking recording function not supported";
BA_ "GenSigSendType" SG_ 951 BLTN_CAM_RecSet_PEV 4;
BA_ "UserSigValidity" SG_ 951 BLTN_CAM_RecSet_PEV 0;
BA_REL_ "GenSigTimeoutTime" BU_SG_REL_ CGW_CCU SG_ 951 BLTN_CAM_RecSet_PEV 1500;
BA_ "Version" SG_ 951 BLTN_CAM_RecSet_PEV "21.05.02";
BA_ "Description" SG_ 951 BLTN_CAM_AudRec_Set "Audio Record On/Off Set";
BA_ "GenSigSendType" SG_ 951 BLTN_CAM_AudRec_Set 4;
BA_ "UserSigValidity" SG_ 951 BLTN_CAM_AudRec_Set 0;
BA_REL_ "GenSigTimeoutTime" BU_SG_REL_ CGW_CCU SG_ 951 BLTN_CAM_AudRec_Set 1500;
BA_ "Version" SG_ 951 BLTN_CAM_AudRec_Set "21.05.02";
BA_ "GenMsgSendType" BO_ 952 0;
BA_ "Description" SG_ 952 BLTN_CAM_Set_FR_Ver_Pos "Front Camera Vertical position setting value.";
BA_ "GenSigSendType" SG_ 952 BLTN_CAM_Set_FR_Ver_Pos 4;
BA_ "UserSigValidity" SG_ 952 BLTN_CAM_Set_FR_Ver_Pos 0;
BA_REL_ "GenSigTimeoutTime" BU_SG_REL_ CGW_CCU SG_ 952 BLTN_CAM_Set_FR_Ver_Pos 1500;
BA_ "RoutingFactor" SG_ 952 BLTN_CAM_Set_FR_Ver_Pos 0;
BA_ "Version" SG_ 952 BLTN_CAM_Set_FR_Ver_Pos "21.05.02";
BA_ "Description" SG_ 952 BLTN_CAM_Set_PEV_AppNoti "Parked Event notification to Connectivity Phone App. On/Off";
BA_ "GenSigSendType" SG_ 952 BLTN_CAM_Set_PEV_AppNoti 4;
BA_ "UserSigValidity" SG_ 952 BLTN_CAM_Set_PEV_AppNoti 0;
BA_REL_ "GenSigTimeoutTime" BU_SG_REL_ CGW_CCU SG_ 952 BLTN_CAM_Set_PEV_AppNoti 1500;
BA_ "RoutingFactor" SG_ 952 BLTN_CAM_Set_PEV_AppNoti 0;
BA_ "Version" SG_ 952 BLTN_CAM_Set_PEV_AppNoti "21.05.02";
BA_ "Description" SG_ 952 BLTN_CAM_Set_WiFi_AutoOn "Wifi On/Off User setting";
BA_ "GenSigSendType" SG_ 952 BLTN_CAM_Set_WiFi_AutoOn 4;
BA_ "UserSigValidity" SG_ 952 BLTN_CAM_Set_WiFi_AutoOn 0;
BA_REL_ "GenSigTimeoutTime" BU_SG_REL_ CGW_CCU SG_ 952 BLTN_CAM_Set_WiFi_AutoOn 1500;
BA_ "RoutingFactor" SG_ 952 BLTN_CAM_Set_WiFi_AutoOn 0;
BA_ "Version" SG_ 952 BLTN_CAM_Set_WiFi_AutoOn "21.05.02";
BA_ "Description" SG_ 952 BLTN_CAM_StrgPropSet "Propotion of built-in Cam SD card Propotion set of the Recording Categories";
BA_ "GenSigSendType" SG_ 952 BLTN_CAM_StrgPropSet 4;
BA_ "UserSigValidity" SG_ 952 BLTN_CAM_StrgPropSet 0;
BA_REL_ "GenSigTimeoutTime" BU_SG_REL_ CGW_CCU SG_ 952 BLTN_CAM_StrgPropSet 1500;
BA_ "RoutingFactor" SG_ 952 BLTN_CAM_StrgPropSet 0;
BA_ "Version" SG_ 952 BLTN_CAM_StrgPropSet "21.05.02";
BA_ "Description" SG_ 952 BLTN_CAM_File_DEL_CPY_Op_State "Bulil in Cam Fily copy and delete operating state.";
BA_ "GenSigSendType" SG_ 952 BLTN_CAM_File_DEL_CPY_Op_State 4;
BA_ "UserSigValidity" SG_ 952 BLTN_CAM_File_DEL_CPY_Op_State 0;
BA_REL_ "GenSigTimeoutTime" BU_SG_REL_ CGW_CCU SG_ 952 BLTN_CAM_File_DEL_CPY_Op_State 1500;
BA_ "RoutingFactor" SG_ 952 BLTN_CAM_File_DEL_CPY_Op_State 0;
BA_ "Version" SG_ 952 BLTN_CAM_File_DEL_CPY_Op_State "21.05.02";
BA_ "Description" SG_ 952 BLTN_CAM_File_DEL_CPY_NumTot "Number of Copied or Deleted files.";
BA_ "GenSigSendType" SG_ 952 BLTN_CAM_File_DEL_CPY_NumTot 4;
BA_ "UserSigValidity" SG_ 952 BLTN_CAM_File_DEL_CPY_NumTot 0;
BA_REL_ "GenSigTimeoutTime" BU_SG_REL_ CGW_CCU SG_ 952 BLTN_CAM_File_DEL_CPY_NumTot 1500;
BA_ "RoutingFactor" SG_ 952 BLTN_CAM_File_DEL_CPY_NumTot 0;
BA_ "Version" SG_ 952 BLTN_CAM_File_DEL_CPY_NumTot "21.05.02";
BA_ "Description" SG_ 952 BLTN_CAM_File_DEL_CPYed_Num "Total number of the copy or delete file.";
BA_ "GenSigSendType" SG_ 952 BLTN_CAM_File_DEL_CPYed_Num 4;
BA_ "UserSigValidity" SG_ 952 BLTN_CAM_File_DEL_CPYed_Num 0;
BA_REL_ "GenSigTimeoutTime" BU_SG_REL_ CGW_CCU SG_ 952 BLTN_CAM_File_DEL_CPYed_Num 1500;
BA_ "RoutingFactor" SG_ 952 BLTN_CAM_File_DEL_CPYed_Num 0;
BA_ "Version" SG_ 952 BLTN_CAM_File_DEL_CPYed_Num "21.05.02";
BA_ "Description" SG_ 952 BLTN_CAM_Set_RR_Ver_Pos "Rear Camera Vertical position setting value.";
BA_ "GenSigSendType" SG_ 952 BLTN_CAM_Set_RR_Ver_Pos 4;
BA_ "UserSigValidity" SG_ 952 BLTN_CAM_Set_RR_Ver_Pos 0;
BA_REL_ "GenSigTimeoutTime" BU_SG_REL_ CGW_CCU SG_ 952 BLTN_CAM_Set_RR_Ver_Pos 1500;
BA_ "RoutingFactor" SG_ 952 BLTN_CAM_Set_RR_Ver_Pos 0;
BA_ "Version" SG_ 952 BLTN_CAM_Set_RR_Ver_Pos "21.05.02";
BA_ "GenMsgSendType" BO_ 950 0;
BA_ "Description" SG_ 950 BLTN_CAM_State "This Signal is for cluster warning popup.";
BA_ "UsrSigPurpose" SG_ 950 BLTN_CAM_State 0;
BA_ "GenSigSendType" SG_ 950 BLTN_CAM_State 4;
BA_ "UserSigValidity" SG_ 950 BLTN_CAM_State 1;
BA_REL_ "GenSigTimeoutTime" BU_SG_REL_ CGW_CCU SG_ 950 BLTN_CAM_State 1500;
BA_ "RoutingFactor" SG_ 950 BLTN_CAM_State 0;
BA_ "Version" SG_ 950 BLTN_CAM_State "21.05.02";
BA_ "Description" SG_ 950 BLTN_CAM_RecSta_DEV "This Signal inform recording status of Driving Event.";
BA_ "UsrSigPurpose" SG_ 950 BLTN_CAM_RecSta_DEV 0;
BA_ "GenSigSendType" SG_ 950 BLTN_CAM_RecSta_DEV 4;
BA_ "UserSigValidity" SG_ 950 BLTN_CAM_RecSta_DEV 1;
BA_REL_ "GenSigTimeoutTime" BU_SG_REL_ CGW_CCU SG_ 950 BLTN_CAM_RecSta_DEV 1500;
BA_ "RoutingFactor" SG_ 950 BLTN_CAM_RecSta_DEV 0;
BA_ "Version" SG_ 950 BLTN_CAM_RecSta_DEV "21.05.02";
BA_ "Description" SG_ 950 BLTN_CAM_RecSta_MAR "This Signal inform recording status of Manual Recording.";
BA_ "UsrSigPurpose" SG_ 950 BLTN_CAM_RecSta_MAR 0;
BA_ "GenSigSendType" SG_ 950 BLTN_CAM_RecSta_MAR 4;
BA_ "UserSigValidity" SG_ 950 BLTN_CAM_RecSta_MAR 1;
BA_REL_ "GenSigTimeoutTime" BU_SG_REL_ CGW_CCU SG_ 950 BLTN_CAM_RecSta_MAR 1500;
BA_ "RoutingFactor" SG_ 950 BLTN_CAM_RecSta_MAR 0;
BA_ "Version" SG_ 950 BLTN_CAM_RecSta_MAR "21.05.02";
BA_ "Description" SG_ 950 BLTN_CAM_RecSta_TML "This Signal inform recording status of Time-lapse.";
BA_ "UsrSigPurpose" SG_ 950 BLTN_CAM_RecSta_TML 0;
BA_ "GenSigSendType" SG_ 950 BLTN_CAM_RecSta_TML 4;
BA_ "UserSigValidity" SG_ 950 BLTN_CAM_RecSta_TML 1;
BA_REL_ "GenSigTimeoutTime" BU_SG_REL_ CGW_CCU SG_ 950 BLTN_CAM_RecSta_TML 1500;
BA_ "RoutingFactor" SG_ 950 BLTN_CAM_RecSta_TML 0;
BA_ "Version" SG_ 950 BLTN_CAM_RecSta_TML "21.05.02";
BA_ "Description" SG_ 950 BLTN_CAM_RecSta_OWP "This Signal inform recording status of On While Parked.";
BA_ "UsrSigPurpose" SG_ 950 BLTN_CAM_RecSta_OWP 0;
BA_ "GenSigSendType" SG_ 950 BLTN_CAM_RecSta_OWP 4;
BA_ "UserSigValidity" SG_ 950 BLTN_CAM_RecSta_OWP 1;
BA_REL_ "GenSigTimeoutTime" BU_SG_REL_ CGW_CCU SG_ 950 BLTN_CAM_RecSta_OWP 1500;
BA_ "RoutingFactor" SG_ 950 BLTN_CAM_RecSta_OWP 0;
BA_ "Version" SG_ 950 BLTN_CAM_RecSta_OWP "21.05.02";
BA_ "Description" SG_ 950 BLTN_CAM_RecSta_PEV "This Signal inform recording status of Parked Event.";
BA_ "UsrSigPurpose" SG_ 950 BLTN_CAM_RecSta_PEV 0;
BA_ "GenSigSendType" SG_ 950 BLTN_CAM_RecSta_PEV 4;
BA_ "UserSigValidity" SG_ 950 BLTN_CAM_RecSta_PEV 1;
BA_REL_ "GenSigTimeoutTime" BU_SG_REL_ CGW_CCU SG_ 950 BLTN_CAM_RecSta_PEV 1500;
BA_ "RoutingFactor" SG_ 950 BLTN_CAM_RecSta_PEV 0;
BA_ "Version" SG_ 950 BLTN_CAM_RecSta_PEV "21.05.02";
BA_ "Description" SG_ 950 BLTN_CAM_Prk_EV_Cnt "The count number of a parked Event.";
BA_ "UsrSigPurpose" SG_ 950 BLTN_CAM_Prk_EV_Cnt 0;
BA_ "GenSigSendType" SG_ 950 BLTN_CAM_Prk_EV_Cnt 4;
BA_ "UserSigValidity" SG_ 950 BLTN_CAM_Prk_EV_Cnt 1;
BA_REL_ "GenSigTimeoutTime" BU_SG_REL_ CGW_CCU SG_ 950 BLTN_CAM_Prk_EV_Cnt 1500;
BA_ "RoutingFactor" SG_ 950 BLTN_CAM_Prk_EV_Cnt 0;
BA_ "Version" SG_ 950 BLTN_CAM_Prk_EV_Cnt "21.05.02";
BA_ "Description" SG_ 950 BLTN_CAM_Prk_Oped_Time "The Parked Opreated time ingormation";
BA_ "UsrSigPurpose" SG_ 950 BLTN_CAM_Prk_Oped_Time 0;
BA_ "GenSigSendType" SG_ 950 BLTN_CAM_Prk_Oped_Time 4;
BA_ "UserSigValidity" SG_ 950 BLTN_CAM_Prk_Oped_Time 1;
BA_REL_ "GenSigTimeoutTime" BU_SG_REL_ CGW_CCU SG_ 950 BLTN_CAM_Prk_Oped_Time 1500;
BA_ "RoutingFactor" SG_ 950 BLTN_CAM_Prk_Oped_Time 0;
BA_ "Version" SG_ 950 BLTN_CAM_Prk_Oped_Time "21.06.08";
BA_ "Description" SG_ 950 BLTN_CAM_Prk_Oprable_Time "The hours of Park Mode Operatable, the time is limited by user max oper. Set.";
BA_ "UsrSigPurpose" SG_ 950 BLTN_CAM_Prk_Oprable_Time 0;
BA_ "GenSigSendType" SG_ 950 BLTN_CAM_Prk_Oprable_Time 4;
BA_ "UserSigValidity" SG_ 950 BLTN_CAM_Prk_Oprable_Time 1;
BA_REL_ "GenSigTimeoutTime" BU_SG_REL_ CGW_CCU SG_ 950 BLTN_CAM_Prk_Oprable_Time 1500;
BA_ "RoutingFactor" SG_ 950 BLTN_CAM_Prk_Oprable_Time 0;
BA_ "Version" SG_ 950 BLTN_CAM_Prk_Oprable_Time "21.07.04";
BA_ "Description" SG_ 950 BLTN_CAM_SD_Card_State "This Signal is for SD card Status in Built-in App menu and CCS Phone App.";
BA_ "UsrSigPurpose" SG_ 950 BLTN_CAM_SD_Card_State 0;
BA_ "GenSigSendType" SG_ 950 BLTN_CAM_SD_Card_State 4;
BA_ "UserSigValidity" SG_ 950 BLTN_CAM_SD_Card_State 1;
BA_REL_ "GenSigTimeoutTime" BU_SG_REL_ CGW_CCU SG_ 950 BLTN_CAM_SD_Card_State 1500;
BA_ "NetworkRequest" SG_ 950 BLTN_CAM_SD_Card_State 0;
BA_ "NetworkRequestHoldingTime" SG_ 950 BLTN_CAM_SD_Card_State 1000;
BA_ "RoutingFactor" SG_ 950 BLTN_CAM_SD_Card_State 0;
BA_ "Version" SG_ 950 BLTN_CAM_SD_Card_State "21.12.00";
BA_ "Description" SG_ 950 BLTN_CAM_Prk_Oprable_Time_Max "The hours of Park Mode Operatable, the time has no limit.";
BA_ "UsrSigPurpose" SG_ 950 BLTN_CAM_Prk_Oprable_Time_Max 0;
BA_ "GenSigSendType" SG_ 950 BLTN_CAM_Prk_Oprable_Time_Max 4;
BA_ "UserSigValidity" SG_ 950 BLTN_CAM_Prk_Oprable_Time_Max 1;
BA_REL_ "GenSigTimeoutTime" BU_SG_REL_ CGW_CCU SG_ 950 BLTN_CAM_Prk_Oprable_Time_Max 1500;
BA_ "RoutingFactor" SG_ 950 BLTN_CAM_Prk_Oprable_Time_Max 0;
BA_ "Version" SG_ 950 BLTN_CAM_Prk_Oprable_Time_Max "21.07.04";
BA_ "Description" SG_ 950 BLTN_CAM_AuxBat_Conn_State "The auxiliary Battery conntction information.";
BA_ "UsrSigPurpose" SG_ 950 BLTN_CAM_AuxBat_Conn_State 0;
BA_ "GenSigSendType" SG_ 950 BLTN_CAM_AuxBat_Conn_State 4;
BA_ "UserSigValidity" SG_ 950 BLTN_CAM_AuxBat_Conn_State 0;
BA_REL_ "GenSigTimeoutTime" BU_SG_REL_ CGW_CCU SG_ 950 BLTN_CAM_AuxBat_Conn_State 1500;
BA_ "RoutingFactor" SG_ 950 BLTN_CAM_AuxBat_Conn_State 0;
BA_ "Version" SG_ 950 BLTN_CAM_AuxBat_Conn_State "21.07.04";
BA_ "Description" SG_ 950 BLTN_CAM_AuxBat_CapPer "The percentage of Aux. Bat.";
BA_ "UsrSigPurpose" SG_ 950 BLTN_CAM_AuxBat_CapPer 0;
BA_ "GenSigSendType" SG_ 950 BLTN_CAM_AuxBat_CapPer 4;
BA_ "UserSigValidity" SG_ 950 BLTN_CAM_AuxBat_CapPer 1;
BA_REL_ "GenSigTimeoutTime" BU_SG_REL_ CGW_CCU SG_ 950 BLTN_CAM_AuxBat_CapPer 1500;
BA_ "RoutingFactor" SG_ 950 BLTN_CAM_AuxBat_CapPer 0;
BA_ "Version" SG_ 950 BLTN_CAM_AuxBat_CapPer "21.05.02";
BA_ "Description" SG_ 950 BLTN_CAM_RecSta_OWD "This Signal inform recording status of On While Driving.";
BA_ "UsrSigPurpose" SG_ 950 BLTN_CAM_RecSta_OWD 0;
BA_ "GenSigSendType" SG_ 950 BLTN_CAM_RecSta_OWD 4;
BA_ "UserSigValidity" SG_ 950 BLTN_CAM_RecSta_OWD 1;
BA_REL_ "GenSigTimeoutTime" BU_SG_REL_ CGW_CCU SG_ 950 BLTN_CAM_RecSta_OWD 1500;
BA_ "RoutingFactor" SG_ 950 BLTN_CAM_RecSta_OWD 0;
BA_ "Version" SG_ 950 BLTN_CAM_RecSta_OWD "21.05.02";
BA_ "GenMsgSendType" BO_ 2382594305 0;
BA_ "VFrameFormat" BO_ 2382594305 1;
BA_ "Description" SG_ 2382594305 DATC_Crc4Val "The data area for CRC calculation is based on the data length (DLC) of the message DB.

The CRC shall be calculated over the entire data block (excluding the CRC bytes) including the user data, alive counter and Data ID

 

- CRC Polynomial (0x1021) , Initial Value : 0xFFFF, XOR value : 0x0000, Data ID : Message ID + 0xF800 

- The initial value is for CRC calculation and the message should be sent with the calculated result value. 

- The mathematical expression to 16 bit CRC polynomial is given here. G(x) = x16 + x12 + x5 + 1";
BA_ "GenSigSendType" SG_ 2382594305 DATC_Crc4Val 4;
BA_ "GenSigStartValue" SG_ 2382594305 DATC_Crc4Val 65535;
BA_ "UserSigValidity" SG_ 2382594305 DATC_Crc4Val 3;
BA_ "Version" SG_ 2382594305 DATC_Crc4Val "18.11.08";
BA_ "Description" SG_ 2382594305 DATC_AlvCnt4Val "For the first transmission request for a data element the counter shall be initialized with 0 and shall be incremented by 1 for every subsequent send request. 

When the counter reaches the maximum value(0xFF), then it shall restart with 0 for the next send request";
BA_ "GenSigSendType" SG_ 2382594305 DATC_AlvCnt4Val 4;
BA_ "UserSigValidity" SG_ 2382594305 DATC_AlvCnt4Val 3;
BA_ "Version" SG_ 2382594305 DATC_AlvCnt4Val "18.11.08";
BA_ "Description" SG_ 2382594305 DATC_RrDrvTempCDis "if Rear passenger Push Rear TEMP(¡ã/ ¡å) button 

Its temperature is increased/decreased by 0.5¡É from high(32¡É) to low(17¡É).";
BA_ "GenSigSendType" SG_ 2382594305 DATC_RrDrvTempCDis 4;
BA_ "UserSigValidity" SG_ 2382594305 DATC_RrDrvTempCDis 6;
BA_REL_ "GenSigTimeoutTime" BU_SG_REL_ ATS SG_ 2382594305 DATC_RrDrvTempCDis 1500;
BA_ "Version" SG_ 2382594305 DATC_RrDrvTempCDis "19.05.03";
BA_ "Description" SG_ 2382594305 DATC_RrDrvTempFDis "if Rear passenger Push Rear TEMP(¡ã/ ¡å) button 

Its temperature is increased/decreased by 1¢µ from high(90¢µ) to low(62¢µ).";
BA_ "GenSigSendType" SG_ 2382594305 DATC_RrDrvTempFDis 4;
BA_ "UserSigValidity" SG_ 2382594305 DATC_RrDrvTempFDis 6;
BA_REL_ "GenSigTimeoutTime" BU_SG_REL_ ATS SG_ 2382594305 DATC_RrDrvTempFDis 1500;
BA_ "Version" SG_ 2382594305 DATC_RrDrvTempFDis "19.05.03";
BA_ "Description" SG_ 2382594305 DATC_RrPassTempCDis "its temperature is increased/decreased by 0.5¡Éfrom high(32¡É) to low(17¡É)";
BA_ "GenSigSendType" SG_ 2382594305 DATC_RrPassTempCDis 4;
BA_ "UserSigValidity" SG_ 2382594305 DATC_RrPassTempCDis 3;
BA_ "Version" SG_ 2382594305 DATC_RrPassTempCDis "19.05.03";
BA_ "Description" SG_ 2382594305 DATC_RrPassTempFDis "its temperature is increased/decreased by 1¢µ from high(90¢µ) to low(62¢µ)";
BA_ "GenSigSendType" SG_ 2382594305 DATC_RrPassTempFDis 4;
BA_ "UserSigValidity" SG_ 2382594305 DATC_RrPassTempFDis 3;
BA_ "Version" SG_ 2382594305 DATC_RrPassTempFDis "19.05.03";
BA_ "Description" SG_ 2382594305 DATC_RrDrvMTCTempLvlDis "This signal indicates step of Rear blower Graphic.

This signal occurs when Rear Blower switch(button) is selected either manually or automatically.";
BA_ "GenSigSendType" SG_ 2382594305 DATC_RrDrvMTCTempLvlDis 4;
BA_ "UserSigValidity" SG_ 2382594305 DATC_RrDrvMTCTempLvlDis 7;
BA_ "Version" SG_ 2382594305 DATC_RrDrvMTCTempLvlDis "17.11.00";
BA_ "GenMsgCycleTime" BO_ 1483 0;
BA_ "GenMsgCycleTimeFast" BO_ 1483 0;
BA_ "GenMsgNrOfRepetition" BO_ 1483 0;
BA_ "DiagResponse" BO_ 1483 1;
BA_ "GenMsgILSupport" BO_ 1483 0;
BA_ "TpMessage" BO_ 1483 1;
BA_ "TpTxIndex" BO_ 1483 215;
BA_ "Description" SG_ 1483 DSAU_GST_Byte0 "TP Index : 215";
BA_ "UsrSigPurpose" SG_ 1483 DSAU_GST_Byte0 4;
BA_ "UserSigValidity" SG_ 1483 DSAU_GST_Byte0 0;
BA_REL_ "GenSigTimeoutTime" BU_SG_REL_ CGW_CCU SG_ 1483 DSAU_GST_Byte0 0;
BA_ "NetworkRequest" SG_ 1483 DSAU_GST_Byte0 0;
BA_ "NetworkRequestHoldingTime" SG_ 1483 DSAU_GST_Byte0 5000;
BA_ "Version" SG_ 1483 DSAU_GST_Byte0 "21.02.04";
BA_ "Description" SG_ 1483 DSAU_GST_Byte2 "TP Index : 215";
BA_ "UsrSigPurpose" SG_ 1483 DSAU_GST_Byte2 4;
BA_ "UserSigValidity" SG_ 1483 DSAU_GST_Byte2 0;
BA_REL_ "GenSigTimeoutTime" BU_SG_REL_ CGW_CCU SG_ 1483 DSAU_GST_Byte2 0;
BA_ "NetworkRequest" SG_ 1483 DSAU_GST_Byte2 0;
BA_ "NetworkRequestHoldingTime" SG_ 1483 DSAU_GST_Byte2 5000;
BA_ "Version" SG_ 1483 DSAU_GST_Byte2 "21.02.04";
BA_ "Description" SG_ 1483 DSAU_GST_Byte3 "TP Index : 215";
BA_ "UsrSigPurpose" SG_ 1483 DSAU_GST_Byte3 4;
BA_ "UserSigValidity" SG_ 1483 DSAU_GST_Byte3 0;
BA_REL_ "GenSigTimeoutTime" BU_SG_REL_ CGW_CCU SG_ 1483 DSAU_GST_Byte3 0;
BA_ "NetworkRequest" SG_ 1483 DSAU_GST_Byte3 0;
BA_ "NetworkRequestHoldingTime" SG_ 1483 DSAU_GST_Byte3 5000;
BA_ "Version" SG_ 1483 DSAU_GST_Byte3 "21.02.04";
BA_ "Description" SG_ 1483 DSAU_GST_Byte4 "TP Index : 215";
BA_ "UsrSigPurpose" SG_ 1483 DSAU_GST_Byte4 4;
BA_ "UserSigValidity" SG_ 1483 DSAU_GST_Byte4 0;
BA_REL_ "GenSigTimeoutTime" BU_SG_REL_ CGW_CCU SG_ 1483 DSAU_GST_Byte4 0;
BA_ "NetworkRequest" SG_ 1483 DSAU_GST_Byte4 0;
BA_ "NetworkRequestHoldingTime" SG_ 1483 DSAU_GST_Byte4 5000;
BA_ "Version" SG_ 1483 DSAU_GST_Byte4 "21.02.04";
BA_ "Description" SG_ 1483 DSAU_GST_Byte5 "TP Index : 215";
BA_ "UsrSigPurpose" SG_ 1483 DSAU_GST_Byte5 4;
BA_ "UserSigValidity" SG_ 1483 DSAU_GST_Byte5 0;
BA_REL_ "GenSigTimeoutTime" BU_SG_REL_ CGW_CCU SG_ 1483 DSAU_GST_Byte5 0;
BA_ "NetworkRequest" SG_ 1483 DSAU_GST_Byte5 0;
BA_ "NetworkRequestHoldingTime" SG_ 1483 DSAU_GST_Byte5 5000;
BA_ "Version" SG_ 1483 DSAU_GST_Byte5 "21.02.04";
BA_ "Description" SG_ 1483 DSAU_GST_Byte6 "TP Index : 215";
BA_ "UsrSigPurpose" SG_ 1483 DSAU_GST_Byte6 4;
BA_ "UserSigValidity" SG_ 1483 DSAU_GST_Byte6 0;
BA_REL_ "GenSigTimeoutTime" BU_SG_REL_ CGW_CCU SG_ 1483 DSAU_GST_Byte6 0;
BA_ "NetworkRequest" SG_ 1483 DSAU_GST_Byte6 0;
BA_ "NetworkRequestHoldingTime" SG_ 1483 DSAU_GST_Byte6 5000;
BA_ "Version" SG_ 1483 DSAU_GST_Byte6 "21.02.04";
BA_ "Description" SG_ 1483 DSAU_GST_Byte7 "TP Index : 215";
BA_ "UsrSigPurpose" SG_ 1483 DSAU_GST_Byte7 4;
BA_ "UserSigValidity" SG_ 1483 DSAU_GST_Byte7 0;
BA_REL_ "GenSigTimeoutTime" BU_SG_REL_ CGW_CCU SG_ 1483 DSAU_GST_Byte7 0;
BA_ "NetworkRequest" SG_ 1483 DSAU_GST_Byte7 0;
BA_ "NetworkRequestHoldingTime" SG_ 1483 DSAU_GST_Byte7 5000;
BA_ "Version" SG_ 1483 DSAU_GST_Byte7 "21.02.04";
BA_ "Description" SG_ 1483 DSAU_GST_Byte1 "TP Index : 215";
BA_ "UsrSigPurpose" SG_ 1483 DSAU_GST_Byte1 4;
BA_ "UserSigValidity" SG_ 1483 DSAU_GST_Byte1 0;
BA_REL_ "GenSigTimeoutTime" BU_SG_REL_ CGW_CCU SG_ 1483 DSAU_GST_Byte1 0;
BA_ "NetworkRequest" SG_ 1483 DSAU_GST_Byte1 0;
BA_ "NetworkRequestHoldingTime" SG_ 1483 DSAU_GST_Byte1 5000;
BA_ "Version" SG_ 1483 DSAU_GST_Byte1 "21.02.04";
BA_ "GenMsgSendType" BO_ 847 0;
BA_ "Description" SG_ 847 Drv_SHVU_DTCdisplay "This signal indicates DTC Code of Self-Diagnostic mode (Driver Seat)";
BA_ "GenSigSendType" SG_ 847 Drv_SHVU_DTCdisplay 4;
BA_ "UserSigValidity" SG_ 847 Drv_SHVU_DTCdisplay 3;
BA_ "NetworkRequest" SG_ 847 Drv_SHVU_DTCdisplay 0;
BA_ "NetworkRequestHoldingTime" SG_ 847 Drv_SHVU_DTCdisplay 5000;
BA_ "Version" SG_ 847 Drv_SHVU_DTCdisplay "19.03.01";
BA_ "Description" SG_ 847 Drv_SHVU_DiagMode "This signal indicates operating mode of SHVU (Self-Diagnostic mode or normal mode)";
BA_ "GenSigSendType" SG_ 847 Drv_SHVU_DiagMode 4;
BA_ "UserSigValidity" SG_ 847 Drv_SHVU_DiagMode 3;
BA_ "NetworkRequest" SG_ 847 Drv_SHVU_DiagMode 0;
BA_ "NetworkRequestHoldingTime" SG_ 847 Drv_SHVU_DiagMode 5000;
BA_ "Version" SG_ 847 Drv_SHVU_DiagMode "19.03.01";
BA_ "GenMsgCycleTime" BO_ 1798 0;
BA_ "GenMsgCycleTimeFast" BO_ 1798 0;
BA_ "GenMsgNrOfRepetition" BO_ 1798 0;
BA_ "DiagRequest" BO_ 1798 1;
BA_ "GenMsgILSupport" BO_ 1798 0;
BA_ "TpMessage" BO_ 1798 1;
BA_ "TpTxIndex" BO_ 1798 106;
BA_ "Description" SG_ 1798 GST_AHV_SHVU_FR_Byte0 "TP Index : 106";
BA_ "UsrSigPurpose" SG_ 1798 GST_AHV_SHVU_FR_Byte0 3;
BA_ "UserSigValidity" SG_ 1798 GST_AHV_SHVU_FR_Byte0 0;
BA_REL_ "GenSigTimeoutTime" BU_SG_REL_ SHVU_FR SG_ 1798 GST_AHV_SHVU_FR_Byte0 0;
BA_ "NetworkRequest" SG_ 1798 GST_AHV_SHVU_FR_Byte0 0;
BA_ "NetworkRequestHoldingTime" SG_ 1798 GST_AHV_SHVU_FR_Byte0 5000;
BA_ "Version" SG_ 1798 GST_AHV_SHVU_FR_Byte0 "21.02.04";
BA_ "Description" SG_ 1798 GST_AHV_SHVU_FR_Byte2 "TP Index : 106";
BA_ "UsrSigPurpose" SG_ 1798 GST_AHV_SHVU_FR_Byte2 3;
BA_ "UserSigValidity" SG_ 1798 GST_AHV_SHVU_FR_Byte2 0;
BA_REL_ "GenSigTimeoutTime" BU_SG_REL_ SHVU_FR SG_ 1798 GST_AHV_SHVU_FR_Byte2 0;
BA_ "NetworkRequest" SG_ 1798 GST_AHV_SHVU_FR_Byte2 0;
BA_ "NetworkRequestHoldingTime" SG_ 1798 GST_AHV_SHVU_FR_Byte2 5000;
BA_ "Version" SG_ 1798 GST_AHV_SHVU_FR_Byte2 "21.02.04";
BA_ "Description" SG_ 1798 GST_AHV_SHVU_FR_Byte3 "TP Index : 106";
BA_ "UsrSigPurpose" SG_ 1798 GST_AHV_SHVU_FR_Byte3 3;
BA_ "UserSigValidity" SG_ 1798 GST_AHV_SHVU_FR_Byte3 0;
BA_REL_ "GenSigTimeoutTime" BU_SG_REL_ SHVU_FR SG_ 1798 GST_AHV_SHVU_FR_Byte3 0;
BA_ "NetworkRequest" SG_ 1798 GST_AHV_SHVU_FR_Byte3 0;
BA_ "NetworkRequestHoldingTime" SG_ 1798 GST_AHV_SHVU_FR_Byte3 5000;
BA_ "Version" SG_ 1798 GST_AHV_SHVU_FR_Byte3 "21.02.04";
BA_ "Description" SG_ 1798 GST_AHV_SHVU_FR_Byte4 "TP Index : 106";
BA_ "UsrSigPurpose" SG_ 1798 GST_AHV_SHVU_FR_Byte4 3;
BA_ "UserSigValidity" SG_ 1798 GST_AHV_SHVU_FR_Byte4 0;
BA_REL_ "GenSigTimeoutTime" BU_SG_REL_ SHVU_FR SG_ 1798 GST_AHV_SHVU_FR_Byte4 0;
BA_ "NetworkRequest" SG_ 1798 GST_AHV_SHVU_FR_Byte4 0;
BA_ "NetworkRequestHoldingTime" SG_ 1798 GST_AHV_SHVU_FR_Byte4 5000;
BA_ "Version" SG_ 1798 GST_AHV_SHVU_FR_Byte4 "21.02.04";
BA_ "Description" SG_ 1798 GST_AHV_SHVU_FR_Byte5 "TP Index : 106";
BA_ "UsrSigPurpose" SG_ 1798 GST_AHV_SHVU_FR_Byte5 3;
BA_ "UserSigValidity" SG_ 1798 GST_AHV_SHVU_FR_Byte5 0;
BA_REL_ "GenSigTimeoutTime" BU_SG_REL_ SHVU_FR SG_ 1798 GST_AHV_SHVU_FR_Byte5 0;
BA_ "NetworkRequest" SG_ 1798 GST_AHV_SHVU_FR_Byte5 0;
BA_ "NetworkRequestHoldingTime" SG_ 1798 GST_AHV_SHVU_FR_Byte5 5000;
BA_ "Version" SG_ 1798 GST_AHV_SHVU_FR_Byte5 "21.02.04";
BA_ "Description" SG_ 1798 GST_AHV_SHVU_FR_Byte6 "TP Index : 106";
BA_ "UsrSigPurpose" SG_ 1798 GST_AHV_SHVU_FR_Byte6 3;
BA_ "UserSigValidity" SG_ 1798 GST_AHV_SHVU_FR_Byte6 0;
BA_REL_ "GenSigTimeoutTime" BU_SG_REL_ SHVU_FR SG_ 1798 GST_AHV_SHVU_FR_Byte6 0;
BA_ "NetworkRequest" SG_ 1798 GST_AHV_SHVU_FR_Byte6 0;
BA_ "NetworkRequestHoldingTime" SG_ 1798 GST_AHV_SHVU_FR_Byte6 5000;
BA_ "Version" SG_ 1798 GST_AHV_SHVU_FR_Byte6 "21.02.04";
BA_ "Description" SG_ 1798 GST_AHV_SHVU_FR_Byte7 "TP Index : 106";
BA_ "UsrSigPurpose" SG_ 1798 GST_AHV_SHVU_FR_Byte7 3;
BA_ "UserSigValidity" SG_ 1798 GST_AHV_SHVU_FR_Byte7 0;
BA_REL_ "GenSigTimeoutTime" BU_SG_REL_ SHVU_FR SG_ 1798 GST_AHV_SHVU_FR_Byte7 0;
BA_ "NetworkRequest" SG_ 1798 GST_AHV_SHVU_FR_Byte7 0;
BA_ "NetworkRequestHoldingTime" SG_ 1798 GST_AHV_SHVU_FR_Byte7 5000;
BA_ "Version" SG_ 1798 GST_AHV_SHVU_FR_Byte7 "21.02.04";
BA_ "Description" SG_ 1798 GST_AHV_SHVU_FR_Byte1 "TP Index : 106";
BA_ "UsrSigPurpose" SG_ 1798 GST_AHV_SHVU_FR_Byte1 3;
BA_ "UserSigValidity" SG_ 1798 GST_AHV_SHVU_FR_Byte1 0;
BA_REL_ "GenSigTimeoutTime" BU_SG_REL_ SHVU_FR SG_ 1798 GST_AHV_SHVU_FR_Byte1 0;
BA_ "NetworkRequest" SG_ 1798 GST_AHV_SHVU_FR_Byte1 0;
BA_ "NetworkRequestHoldingTime" SG_ 1798 GST_AHV_SHVU_FR_Byte1 5000;
BA_ "Version" SG_ 1798 GST_AHV_SHVU_FR_Byte1 "21.02.04";
BA_ "GenMsgCycleTime" BO_ 1476 0;
BA_ "GenMsgCycleTimeFast" BO_ 1476 0;
BA_ "GenMsgNrOfRepetition" BO_ 1476 0;
BA_ "DiagRequest" BO_ 1476 1;
BA_ "GenMsgILSupport" BO_ 1476 0;
BA_ "TpMessage" BO_ 1476 1;
BA_ "TpTxIndex" BO_ 1476 216;
BA_ "Description" SG_ 1476 GST_ASAU_Byte0 "TP Index : 216";
BA_ "UsrSigPurpose" SG_ 1476 GST_ASAU_Byte0 3;
BA_ "UserSigValidity" SG_ 1476 GST_ASAU_Byte0 0;
BA_REL_ "GenSigTimeoutTime" BU_SG_REL_ ASAU SG_ 1476 GST_ASAU_Byte0 0;
BA_ "NetworkRequest" SG_ 1476 GST_ASAU_Byte0 0;
BA_ "NetworkRequestHoldingTime" SG_ 1476 GST_ASAU_Byte0 5000;
BA_ "Version" SG_ 1476 GST_ASAU_Byte0 "21.02.04";
BA_ "Description" SG_ 1476 GST_ASAU_Byte2 "TP Index : 216";
BA_ "UsrSigPurpose" SG_ 1476 GST_ASAU_Byte2 3;
BA_ "UserSigValidity" SG_ 1476 GST_ASAU_Byte2 0;
BA_REL_ "GenSigTimeoutTime" BU_SG_REL_ ASAU SG_ 1476 GST_ASAU_Byte2 0;
BA_ "NetworkRequest" SG_ 1476 GST_ASAU_Byte2 0;
BA_ "NetworkRequestHoldingTime" SG_ 1476 GST_ASAU_Byte2 5000;
BA_ "Version" SG_ 1476 GST_ASAU_Byte2 "21.02.04";
BA_ "Description" SG_ 1476 GST_ASAU_Byte3 "TP Index : 216";
BA_ "UsrSigPurpose" SG_ 1476 GST_ASAU_Byte3 3;
BA_ "UserSigValidity" SG_ 1476 GST_ASAU_Byte3 0;
BA_REL_ "GenSigTimeoutTime" BU_SG_REL_ ASAU SG_ 1476 GST_ASAU_Byte3 0;
BA_ "NetworkRequest" SG_ 1476 GST_ASAU_Byte3 0;
BA_ "NetworkRequestHoldingTime" SG_ 1476 GST_ASAU_Byte3 5000;
BA_ "Version" SG_ 1476 GST_ASAU_Byte3 "21.02.04";
BA_ "Description" SG_ 1476 GST_ASAU_Byte4 "TP Index : 216";
BA_ "UsrSigPurpose" SG_ 1476 GST_ASAU_Byte4 3;
BA_ "UserSigValidity" SG_ 1476 GST_ASAU_Byte4 0;
BA_REL_ "GenSigTimeoutTime" BU_SG_REL_ ASAU SG_ 1476 GST_ASAU_Byte4 0;
BA_ "NetworkRequest" SG_ 1476 GST_ASAU_Byte4 0;
BA_ "NetworkRequestHoldingTime" SG_ 1476 GST_ASAU_Byte4 5000;
BA_ "Version" SG_ 1476 GST_ASAU_Byte4 "21.02.04";
BA_ "Description" SG_ 1476 GST_ASAU_Byte5 "TP Index : 216";
BA_ "UsrSigPurpose" SG_ 1476 GST_ASAU_Byte5 3;
BA_ "UserSigValidity" SG_ 1476 GST_ASAU_Byte5 0;
BA_REL_ "GenSigTimeoutTime" BU_SG_REL_ ASAU SG_ 1476 GST_ASAU_Byte5 0;
BA_ "NetworkRequest" SG_ 1476 GST_ASAU_Byte5 0;
BA_ "NetworkRequestHoldingTime" SG_ 1476 GST_ASAU_Byte5 5000;
BA_ "Version" SG_ 1476 GST_ASAU_Byte5 "21.02.04";
BA_ "Description" SG_ 1476 GST_ASAU_Byte6 "TP Index : 216";
BA_ "UsrSigPurpose" SG_ 1476 GST_ASAU_Byte6 3;
BA_ "UserSigValidity" SG_ 1476 GST_ASAU_Byte6 0;
BA_REL_ "GenSigTimeoutTime" BU_SG_REL_ ASAU SG_ 1476 GST_ASAU_Byte6 0;
BA_ "NetworkRequest" SG_ 1476 GST_ASAU_Byte6 0;
BA_ "NetworkRequestHoldingTime" SG_ 1476 GST_ASAU_Byte6 5000;
BA_ "Version" SG_ 1476 GST_ASAU_Byte6 "21.02.04";
BA_ "Description" SG_ 1476 GST_ASAU_Byte7 "TP Index : 216";
BA_ "UsrSigPurpose" SG_ 1476 GST_ASAU_Byte7 3;
BA_ "UserSigValidity" SG_ 1476 GST_ASAU_Byte7 0;
BA_REL_ "GenSigTimeoutTime" BU_SG_REL_ ASAU SG_ 1476 GST_ASAU_Byte7 0;
BA_ "NetworkRequest" SG_ 1476 GST_ASAU_Byte7 0;
BA_ "NetworkRequestHoldingTime" SG_ 1476 GST_ASAU_Byte7 5000;
BA_ "Version" SG_ 1476 GST_ASAU_Byte7 "21.02.04";
BA_ "Description" SG_ 1476 GST_ASAU_Byte1 "TP Index : 216";
BA_ "UsrSigPurpose" SG_ 1476 GST_ASAU_Byte1 3;
BA_ "UserSigValidity" SG_ 1476 GST_ASAU_Byte1 0;
BA_REL_ "GenSigTimeoutTime" BU_SG_REL_ ASAU SG_ 1476 GST_ASAU_Byte1 0;
BA_ "NetworkRequest" SG_ 1476 GST_ASAU_Byte1 0;
BA_ "NetworkRequestHoldingTime" SG_ 1476 GST_ASAU_Byte1 5000;
BA_ "Version" SG_ 1476 GST_ASAU_Byte1 "21.02.04";
BA_ "GenMsgCycleTime" BO_ 1475 0;
BA_ "GenMsgCycleTimeFast" BO_ 1475 0;
BA_ "GenMsgNrOfRepetition" BO_ 1475 0;
BA_ "DiagRequest" BO_ 1475 1;
BA_ "GenMsgILSupport" BO_ 1475 0;
BA_ "TpMessage" BO_ 1475 1;
BA_ "TpTxIndex" BO_ 1475 215;
BA_ "Description" SG_ 1475 GST_DSAU_Byte0 "TP Index : 215";
BA_ "UsrSigPurpose" SG_ 1475 GST_DSAU_Byte0 3;
BA_ "UserSigValidity" SG_ 1475 GST_DSAU_Byte0 0;
BA_REL_ "GenSigTimeoutTime" BU_SG_REL_ DSAU SG_ 1475 GST_DSAU_Byte0 0;
BA_ "NetworkRequest" SG_ 1475 GST_DSAU_Byte0 0;
BA_ "NetworkRequestHoldingTime" SG_ 1475 GST_DSAU_Byte0 5000;
BA_ "Version" SG_ 1475 GST_DSAU_Byte0 "21.02.04";
BA_ "Description" SG_ 1475 GST_DSAU_Byte2 "TP Index : 215";
BA_ "UsrSigPurpose" SG_ 1475 GST_DSAU_Byte2 3;
BA_ "UserSigValidity" SG_ 1475 GST_DSAU_Byte2 0;
BA_REL_ "GenSigTimeoutTime" BU_SG_REL_ DSAU SG_ 1475 GST_DSAU_Byte2 0;
BA_ "NetworkRequest" SG_ 1475 GST_DSAU_Byte2 0;
BA_ "NetworkRequestHoldingTime" SG_ 1475 GST_DSAU_Byte2 5000;
BA_ "Version" SG_ 1475 GST_DSAU_Byte2 "21.02.04";
BA_ "Description" SG_ 1475 GST_DSAU_Byte3 "TP Index : 215";
BA_ "UsrSigPurpose" SG_ 1475 GST_DSAU_Byte3 3;
BA_ "UserSigValidity" SG_ 1475 GST_DSAU_Byte3 0;
BA_REL_ "GenSigTimeoutTime" BU_SG_REL_ DSAU SG_ 1475 GST_DSAU_Byte3 0;
BA_ "NetworkRequest" SG_ 1475 GST_DSAU_Byte3 0;
BA_ "NetworkRequestHoldingTime" SG_ 1475 GST_DSAU_Byte3 5000;
BA_ "Version" SG_ 1475 GST_DSAU_Byte3 "21.02.04";
BA_ "Description" SG_ 1475 GST_DSAU_Byte4 "TP Index : 215";
BA_ "UsrSigPurpose" SG_ 1475 GST_DSAU_Byte4 3;
BA_ "UserSigValidity" SG_ 1475 GST_DSAU_Byte4 0;
BA_REL_ "GenSigTimeoutTime" BU_SG_REL_ DSAU SG_ 1475 GST_DSAU_Byte4 0;
BA_ "NetworkRequest" SG_ 1475 GST_DSAU_Byte4 0;
BA_ "NetworkRequestHoldingTime" SG_ 1475 GST_DSAU_Byte4 5000;
BA_ "Version" SG_ 1475 GST_DSAU_Byte4 "21.02.04";
BA_ "Description" SG_ 1475 GST_DSAU_Byte5 "TP Index : 215";
BA_ "UsrSigPurpose" SG_ 1475 GST_DSAU_Byte5 3;
BA_ "UserSigValidity" SG_ 1475 GST_DSAU_Byte5 0;
BA_REL_ "GenSigTimeoutTime" BU_SG_REL_ DSAU SG_ 1475 GST_DSAU_Byte5 0;
BA_ "NetworkRequest" SG_ 1475 GST_DSAU_Byte5 0;
BA_ "NetworkRequestHoldingTime" SG_ 1475 GST_DSAU_Byte5 5000;
BA_ "Version" SG_ 1475 GST_DSAU_Byte5 "21.02.04";
BA_ "Description" SG_ 1475 GST_DSAU_Byte6 "TP Index : 215";
BA_ "UsrSigPurpose" SG_ 1475 GST_DSAU_Byte6 3;
BA_ "UserSigValidity" SG_ 1475 GST_DSAU_Byte6 0;
BA_REL_ "GenSigTimeoutTime" BU_SG_REL_ DSAU SG_ 1475 GST_DSAU_Byte6 0;
BA_ "NetworkRequest" SG_ 1475 GST_DSAU_Byte6 0;
BA_ "NetworkRequestHoldingTime" SG_ 1475 GST_DSAU_Byte6 5000;
BA_ "Version" SG_ 1475 GST_DSAU_Byte6 "21.02.04";
BA_ "Description" SG_ 1475 GST_DSAU_Byte7 "TP Index : 215";
BA_ "UsrSigPurpose" SG_ 1475 GST_DSAU_Byte7 3;
BA_ "UserSigValidity" SG_ 1475 GST_DSAU_Byte7 0;
BA_REL_ "GenSigTimeoutTime" BU_SG_REL_ DSAU SG_ 1475 GST_DSAU_Byte7 0;
BA_ "NetworkRequest" SG_ 1475 GST_DSAU_Byte7 0;
BA_ "NetworkRequestHoldingTime" SG_ 1475 GST_DSAU_Byte7 5000;
BA_ "Version" SG_ 1475 GST_DSAU_Byte7 "21.02.04";
BA_ "Description" SG_ 1475 GST_DSAU_Byte1 "TP Index : 215";
BA_ "UsrSigPurpose" SG_ 1475 GST_DSAU_Byte1 3;
BA_ "UserSigValidity" SG_ 1475 GST_DSAU_Byte1 0;
BA_REL_ "GenSigTimeoutTime" BU_SG_REL_ DSAU SG_ 1475 GST_DSAU_Byte1 0;
BA_ "NetworkRequest" SG_ 1475 GST_DSAU_Byte1 0;
BA_ "NetworkRequestHoldingTime" SG_ 1475 GST_DSAU_Byte1 5000;
BA_ "Version" SG_ 1475 GST_DSAU_Byte1 "21.02.04";
BA_ "GenMsgCycleTime" BO_ 1491 0;
BA_ "GenMsgCycleTimeFast" BO_ 1491 0;
BA_ "GenMsgNrOfRepetition" BO_ 1491 0;
BA_ "DiagRequest" BO_ 1491 1;
BA_ "GenMsgILSupport" BO_ 1491 0;
BA_ "TpMessage" BO_ 1491 1;
BA_ "TpTxIndex" BO_ 1491 220;
BA_ "Description" SG_ 1491 GST_HOD_Byte0 "TP Index : 220";
BA_ "UsrSigPurpose" SG_ 1491 GST_HOD_Byte0 3;
BA_ "UserSigValidity" SG_ 1491 GST_HOD_Byte0 0;
BA_REL_ "GenSigTimeoutTime" BU_SG_REL_ HOD SG_ 1491 GST_HOD_Byte0 0;
BA_ "NetworkRequest" SG_ 1491 GST_HOD_Byte0 0;
BA_ "NetworkRequestHoldingTime" SG_ 1491 GST_HOD_Byte0 5000;
BA_ "Version" SG_ 1491 GST_HOD_Byte0 "21.02.04";
BA_ "Description" SG_ 1491 GST_HOD_Byte2 "TP Index : 220";
BA_ "UsrSigPurpose" SG_ 1491 GST_HOD_Byte2 3;
BA_ "UserSigValidity" SG_ 1491 GST_HOD_Byte2 0;
BA_REL_ "GenSigTimeoutTime" BU_SG_REL_ HOD SG_ 1491 GST_HOD_Byte2 0;
BA_ "NetworkRequest" SG_ 1491 GST_HOD_Byte2 0;
BA_ "NetworkRequestHoldingTime" SG_ 1491 GST_HOD_Byte2 5000;
BA_ "Version" SG_ 1491 GST_HOD_Byte2 "21.02.04";
BA_ "Description" SG_ 1491 GST_HOD_Byte3 "TP Index : 220";
BA_ "UsrSigPurpose" SG_ 1491 GST_HOD_Byte3 3;
BA_ "UserSigValidity" SG_ 1491 GST_HOD_Byte3 0;
BA_REL_ "GenSigTimeoutTime" BU_SG_REL_ HOD SG_ 1491 GST_HOD_Byte3 0;
BA_ "NetworkRequest" SG_ 1491 GST_HOD_Byte3 0;
BA_ "NetworkRequestHoldingTime" SG_ 1491 GST_HOD_Byte3 5000;
BA_ "Version" SG_ 1491 GST_HOD_Byte3 "21.02.04";
BA_ "Description" SG_ 1491 GST_HOD_Byte4 "TP Index : 220";
BA_ "UsrSigPurpose" SG_ 1491 GST_HOD_Byte4 3;
BA_ "UserSigValidity" SG_ 1491 GST_HOD_Byte4 0;
BA_REL_ "GenSigTimeoutTime" BU_SG_REL_ HOD SG_ 1491 GST_HOD_Byte4 0;
BA_ "NetworkRequest" SG_ 1491 GST_HOD_Byte4 0;
BA_ "NetworkRequestHoldingTime" SG_ 1491 GST_HOD_Byte4 5000;
BA_ "Version" SG_ 1491 GST_HOD_Byte4 "21.02.04";
BA_ "Description" SG_ 1491 GST_HOD_Byte5 "TP Index : 220";
BA_ "UsrSigPurpose" SG_ 1491 GST_HOD_Byte5 3;
BA_ "UserSigValidity" SG_ 1491 GST_HOD_Byte5 0;
BA_REL_ "GenSigTimeoutTime" BU_SG_REL_ HOD SG_ 1491 GST_HOD_Byte5 0;
BA_ "NetworkRequest" SG_ 1491 GST_HOD_Byte5 0;
BA_ "NetworkRequestHoldingTime" SG_ 1491 GST_HOD_Byte5 5000;
BA_ "Version" SG_ 1491 GST_HOD_Byte5 "21.02.04";
BA_ "Description" SG_ 1491 GST_HOD_Byte6 "TP Index : 220";
BA_ "UsrSigPurpose" SG_ 1491 GST_HOD_Byte6 3;
BA_ "UserSigValidity" SG_ 1491 GST_HOD_Byte6 0;
BA_REL_ "GenSigTimeoutTime" BU_SG_REL_ HOD SG_ 1491 GST_HOD_Byte6 0;
BA_ "NetworkRequest" SG_ 1491 GST_HOD_Byte6 0;
BA_ "NetworkRequestHoldingTime" SG_ 1491 GST_HOD_Byte6 5000;
BA_ "Version" SG_ 1491 GST_HOD_Byte6 "21.02.04";
BA_ "Description" SG_ 1491 GST_HOD_Byte7 "TP Index : 220";
BA_ "UsrSigPurpose" SG_ 1491 GST_HOD_Byte7 3;
BA_ "UserSigValidity" SG_ 1491 GST_HOD_Byte7 0;
BA_REL_ "GenSigTimeoutTime" BU_SG_REL_ HOD SG_ 1491 GST_HOD_Byte7 0;
BA_ "NetworkRequest" SG_ 1491 GST_HOD_Byte7 0;
BA_ "NetworkRequestHoldingTime" SG_ 1491 GST_HOD_Byte7 5000;
BA_ "Version" SG_ 1491 GST_HOD_Byte7 "21.02.04";
BA_ "Description" SG_ 1491 GST_HOD_Byte1 "TP Index : 220";
BA_ "UsrSigPurpose" SG_ 1491 GST_HOD_Byte1 3;
BA_ "UserSigValidity" SG_ 1491 GST_HOD_Byte1 0;
BA_REL_ "GenSigTimeoutTime" BU_SG_REL_ HOD SG_ 1491 GST_HOD_Byte1 0;
BA_ "NetworkRequest" SG_ 1491 GST_HOD_Byte1 0;
BA_ "NetworkRequestHoldingTime" SG_ 1491 GST_HOD_Byte1 5000;
BA_ "Version" SG_ 1491 GST_HOD_Byte1 "21.02.04";
BA_ "GenMsgCycleTime" BO_ 1810 0;
BA_ "GenMsgCycleTimeFast" BO_ 1810 0;
BA_ "GenMsgNrOfRepetition" BO_ 1810 0;
BA_ "DiagRequest" BO_ 1810 1;
BA_ "GenMsgILSupport" BO_ 1810 0;
BA_ "TpMessage" BO_ 1810 1;
BA_ "TpTxIndex" BO_ 1810 160;
BA_ "Description" SG_ 1810 GST_RLHVU_Byte0 "TP Index : 160";
BA_ "UsrSigPurpose" SG_ 1810 GST_RLHVU_Byte0 3;
BA_ "UserSigValidity" SG_ 1810 GST_RLHVU_Byte0 0;
BA_REL_ "GenSigTimeoutTime" BU_SG_REL_ RLHV SG_ 1810 GST_RLHVU_Byte0 0;
BA_REL_ "GenSigTimeoutTime" BU_SG_REL_ RLPSU SG_ 1810 GST_RLHVU_Byte0 0;
BA_ "NetworkRequest" SG_ 1810 GST_RLHVU_Byte0 0;
BA_ "NetworkRequestHoldingTime" SG_ 1810 GST_RLHVU_Byte0 5000;
BA_ "Version" SG_ 1810 GST_RLHVU_Byte0 "21.02.04";
BA_ "Description" SG_ 1810 GST_RLHVU_Byte2 "TP Index : 160";
BA_ "UsrSigPurpose" SG_ 1810 GST_RLHVU_Byte2 3;
BA_ "UserSigValidity" SG_ 1810 GST_RLHVU_Byte2 0;
BA_REL_ "GenSigTimeoutTime" BU_SG_REL_ RLHV SG_ 1810 GST_RLHVU_Byte2 0;
BA_REL_ "GenSigTimeoutTime" BU_SG_REL_ RLPSU SG_ 1810 GST_RLHVU_Byte2 0;
BA_ "NetworkRequest" SG_ 1810 GST_RLHVU_Byte2 0;
BA_ "NetworkRequestHoldingTime" SG_ 1810 GST_RLHVU_Byte2 5000;
BA_ "Version" SG_ 1810 GST_RLHVU_Byte2 "21.02.04";
BA_ "Description" SG_ 1810 GST_RLHVU_Byte3 "TP Index : 160";
BA_ "UsrSigPurpose" SG_ 1810 GST_RLHVU_Byte3 3;
BA_ "UserSigValidity" SG_ 1810 GST_RLHVU_Byte3 0;
BA_REL_ "GenSigTimeoutTime" BU_SG_REL_ RLHV SG_ 1810 GST_RLHVU_Byte3 0;
BA_REL_ "GenSigTimeoutTime" BU_SG_REL_ RLPSU SG_ 1810 GST_RLHVU_Byte3 0;
BA_ "NetworkRequest" SG_ 1810 GST_RLHVU_Byte3 0;
BA_ "NetworkRequestHoldingTime" SG_ 1810 GST_RLHVU_Byte3 5000;
BA_ "Version" SG_ 1810 GST_RLHVU_Byte3 "21.02.04";
BA_ "Description" SG_ 1810 GST_RLHVU_Byte4 "TP Index : 160";
BA_ "UsrSigPurpose" SG_ 1810 GST_RLHVU_Byte4 3;
BA_ "UserSigValidity" SG_ 1810 GST_RLHVU_Byte4 0;
BA_REL_ "GenSigTimeoutTime" BU_SG_REL_ RLHV SG_ 1810 GST_RLHVU_Byte4 0;
BA_REL_ "GenSigTimeoutTime" BU_SG_REL_ RLPSU SG_ 1810 GST_RLHVU_Byte4 0;
BA_ "NetworkRequest" SG_ 1810 GST_RLHVU_Byte4 0;
BA_ "NetworkRequestHoldingTime" SG_ 1810 GST_RLHVU_Byte4 5000;
BA_ "Version" SG_ 1810 GST_RLHVU_Byte4 "21.02.04";
BA_ "Description" SG_ 1810 GST_RLHVU_Byte5 "TP Index : 160";
BA_ "UsrSigPurpose" SG_ 1810 GST_RLHVU_Byte5 3;
BA_ "UserSigValidity" SG_ 1810 GST_RLHVU_Byte5 0;
BA_REL_ "GenSigTimeoutTime" BU_SG_REL_ RLHV SG_ 1810 GST_RLHVU_Byte5 0;
BA_REL_ "GenSigTimeoutTime" BU_SG_REL_ RLPSU SG_ 1810 GST_RLHVU_Byte5 0;
BA_ "NetworkRequest" SG_ 1810 GST_RLHVU_Byte5 0;
BA_ "NetworkRequestHoldingTime" SG_ 1810 GST_RLHVU_Byte5 5000;
BA_ "Version" SG_ 1810 GST_RLHVU_Byte5 "21.02.04";
BA_ "Description" SG_ 1810 GST_RLHVU_Byte6 "TP Index : 160";
BA_ "UsrSigPurpose" SG_ 1810 GST_RLHVU_Byte6 3;
BA_ "UserSigValidity" SG_ 1810 GST_RLHVU_Byte6 0;
BA_REL_ "GenSigTimeoutTime" BU_SG_REL_ RLHV SG_ 1810 GST_RLHVU_Byte6 0;
BA_REL_ "GenSigTimeoutTime" BU_SG_REL_ RLPSU SG_ 1810 GST_RLHVU_Byte6 0;
BA_ "NetworkRequest" SG_ 1810 GST_RLHVU_Byte6 0;
BA_ "NetworkRequestHoldingTime" SG_ 1810 GST_RLHVU_Byte6 5000;
BA_ "Version" SG_ 1810 GST_RLHVU_Byte6 "21.02.04";
BA_ "Description" SG_ 1810 GST_RLHVU_Byte7 "TP Index : 160";
BA_ "UsrSigPurpose" SG_ 1810 GST_RLHVU_Byte7 3;
BA_ "UserSigValidity" SG_ 1810 GST_RLHVU_Byte7 0;
BA_REL_ "GenSigTimeoutTime" BU_SG_REL_ RLHV SG_ 1810 GST_RLHVU_Byte7 0;
BA_REL_ "GenSigTimeoutTime" BU_SG_REL_ RLPSU SG_ 1810 GST_RLHVU_Byte7 0;
BA_ "NetworkRequest" SG_ 1810 GST_RLHVU_Byte7 0;
BA_ "NetworkRequestHoldingTime" SG_ 1810 GST_RLHVU_Byte7 5000;
BA_ "Version" SG_ 1810 GST_RLHVU_Byte7 "21.02.04";
BA_ "Description" SG_ 1810 GST_RLHVU_Byte1 "TP Index : 160";
BA_ "UsrSigPurpose" SG_ 1810 GST_RLHVU_Byte1 3;
BA_ "UserSigValidity" SG_ 1810 GST_RLHVU_Byte1 0;
BA_REL_ "GenSigTimeoutTime" BU_SG_REL_ RLHV SG_ 1810 GST_RLHVU_Byte1 0;
BA_REL_ "GenSigTimeoutTime" BU_SG_REL_ RLPSU SG_ 1810 GST_RLHVU_Byte1 0;
BA_ "NetworkRequest" SG_ 1810 GST_RLHVU_Byte1 0;
BA_ "NetworkRequestHoldingTime" SG_ 1810 GST_RLHVU_Byte1 5000;
BA_ "Version" SG_ 1810 GST_RLHVU_Byte1 "21.02.04";
BA_ "GenMsgCycleTime" BO_ 1799 0;
BA_ "GenMsgCycleTimeFast" BO_ 1799 0;
BA_ "GenMsgNrOfRepetition" BO_ 1799 0;
BA_ "DiagRequest" BO_ 1799 1;
BA_ "GenMsgILSupport" BO_ 1799 0;
BA_ "TpMessage" BO_ 1799 1;
BA_ "TpTxIndex" BO_ 1799 165;
BA_ "Description" SG_ 1799 GST_RRHVU_Byte0 "TP Index : 165";
BA_ "UsrSigPurpose" SG_ 1799 GST_RRHVU_Byte0 3;
BA_ "UserSigValidity" SG_ 1799 GST_RRHVU_Byte0 0;
BA_REL_ "GenSigTimeoutTime" BU_SG_REL_ RRHV SG_ 1799 GST_RRHVU_Byte0 0;
BA_REL_ "GenSigTimeoutTime" BU_SG_REL_ SHVU_RR SG_ 1799 GST_RRHVU_Byte0 0;
BA_REL_ "GenSigTimeoutTime" BU_SG_REL_ RRPSU SG_ 1799 GST_RRHVU_Byte0 0;
BA_ "NetworkRequest" SG_ 1799 GST_RRHVU_Byte0 0;
BA_ "NetworkRequestHoldingTime" SG_ 1799 GST_RRHVU_Byte0 5000;
BA_ "Version" SG_ 1799 GST_RRHVU_Byte0 "21.02.04";
BA_ "Description" SG_ 1799 GST_RRHVU_Byte2 "TP Index : 165";
BA_ "UsrSigPurpose" SG_ 1799 GST_RRHVU_Byte2 3;
BA_ "UserSigValidity" SG_ 1799 GST_RRHVU_Byte2 0;
BA_REL_ "GenSigTimeoutTime" BU_SG_REL_ RRHV SG_ 1799 GST_RRHVU_Byte2 0;
BA_REL_ "GenSigTimeoutTime" BU_SG_REL_ SHVU_RR SG_ 1799 GST_RRHVU_Byte2 0;
BA_REL_ "GenSigTimeoutTime" BU_SG_REL_ RRPSU SG_ 1799 GST_RRHVU_Byte2 0;
BA_ "NetworkRequest" SG_ 1799 GST_RRHVU_Byte2 0;
BA_ "NetworkRequestHoldingTime" SG_ 1799 GST_RRHVU_Byte2 5000;
BA_ "Version" SG_ 1799 GST_RRHVU_Byte2 "21.02.04";
BA_ "Description" SG_ 1799 GST_RRHVU_Byte3 "TP Index : 165";
BA_ "UsrSigPurpose" SG_ 1799 GST_RRHVU_Byte3 3;
BA_ "UserSigValidity" SG_ 1799 GST_RRHVU_Byte3 0;
BA_REL_ "GenSigTimeoutTime" BU_SG_REL_ RRHV SG_ 1799 GST_RRHVU_Byte3 0;
BA_REL_ "GenSigTimeoutTime" BU_SG_REL_ SHVU_RR SG_ 1799 GST_RRHVU_Byte3 0;
BA_REL_ "GenSigTimeoutTime" BU_SG_REL_ RRPSU SG_ 1799 GST_RRHVU_Byte3 0;
BA_ "NetworkRequest" SG_ 1799 GST_RRHVU_Byte3 0;
BA_ "NetworkRequestHoldingTime" SG_ 1799 GST_RRHVU_Byte3 5000;
BA_ "Version" SG_ 1799 GST_RRHVU_Byte3 "21.02.04";
BA_ "Description" SG_ 1799 GST_RRHVU_Byte4 "TP Index : 165";
BA_ "UsrSigPurpose" SG_ 1799 GST_RRHVU_Byte4 3;
BA_ "UserSigValidity" SG_ 1799 GST_RRHVU_Byte4 0;
BA_REL_ "GenSigTimeoutTime" BU_SG_REL_ RRHV SG_ 1799 GST_RRHVU_Byte4 0;
BA_REL_ "GenSigTimeoutTime" BU_SG_REL_ SHVU_RR SG_ 1799 GST_RRHVU_Byte4 0;
BA_REL_ "GenSigTimeoutTime" BU_SG_REL_ RRPSU SG_ 1799 GST_RRHVU_Byte4 0;
BA_ "NetworkRequest" SG_ 1799 GST_RRHVU_Byte4 0;
BA_ "NetworkRequestHoldingTime" SG_ 1799 GST_RRHVU_Byte4 5000;
BA_ "Version" SG_ 1799 GST_RRHVU_Byte4 "21.02.04";
BA_ "Description" SG_ 1799 GST_RRHVU_Byte5 "TP Index : 165";
BA_ "UsrSigPurpose" SG_ 1799 GST_RRHVU_Byte5 3;
BA_ "UserSigValidity" SG_ 1799 GST_RRHVU_Byte5 0;
BA_REL_ "GenSigTimeoutTime" BU_SG_REL_ RRHV SG_ 1799 GST_RRHVU_Byte5 0;
BA_REL_ "GenSigTimeoutTime" BU_SG_REL_ SHVU_RR SG_ 1799 GST_RRHVU_Byte5 0;
BA_REL_ "GenSigTimeoutTime" BU_SG_REL_ RRPSU SG_ 1799 GST_RRHVU_Byte5 0;
BA_ "NetworkRequest" SG_ 1799 GST_RRHVU_Byte5 0;
BA_ "NetworkRequestHoldingTime" SG_ 1799 GST_RRHVU_Byte5 5000;
BA_ "Version" SG_ 1799 GST_RRHVU_Byte5 "21.02.04";
BA_ "Description" SG_ 1799 GST_RRHVU_Byte6 "TP Index : 165";
BA_ "UsrSigPurpose" SG_ 1799 GST_RRHVU_Byte6 3;
BA_ "UserSigValidity" SG_ 1799 GST_RRHVU_Byte6 0;
BA_REL_ "GenSigTimeoutTime" BU_SG_REL_ RRHV SG_ 1799 GST_RRHVU_Byte6 0;
BA_REL_ "GenSigTimeoutTime" BU_SG_REL_ SHVU_RR SG_ 1799 GST_RRHVU_Byte6 0;
BA_REL_ "GenSigTimeoutTime" BU_SG_REL_ RRPSU SG_ 1799 GST_RRHVU_Byte6 0;
BA_ "NetworkRequest" SG_ 1799 GST_RRHVU_Byte6 0;
BA_ "NetworkRequestHoldingTime" SG_ 1799 GST_RRHVU_Byte6 5000;
BA_ "Version" SG_ 1799 GST_RRHVU_Byte6 "21.02.04";
BA_ "Description" SG_ 1799 GST_RRHVU_Byte7 "TP Index : 165";
BA_ "UsrSigPurpose" SG_ 1799 GST_RRHVU_Byte7 3;
BA_ "UserSigValidity" SG_ 1799 GST_RRHVU_Byte7 0;
BA_REL_ "GenSigTimeoutTime" BU_SG_REL_ RRHV SG_ 1799 GST_RRHVU_Byte7 0;
BA_REL_ "GenSigTimeoutTime" BU_SG_REL_ SHVU_RR SG_ 1799 GST_RRHVU_Byte7 0;
BA_REL_ "GenSigTimeoutTime" BU_SG_REL_ RRPSU SG_ 1799 GST_RRHVU_Byte7 0;
BA_ "NetworkRequest" SG_ 1799 GST_RRHVU_Byte7 0;
BA_ "NetworkRequestHoldingTime" SG_ 1799 GST_RRHVU_Byte7 5000;
BA_ "Version" SG_ 1799 GST_RRHVU_Byte7 "21.02.04";
BA_ "Description" SG_ 1799 GST_RRHVU_Byte1 "TP Index : 165";
BA_ "UsrSigPurpose" SG_ 1799 GST_RRHVU_Byte1 3;
BA_ "UserSigValidity" SG_ 1799 GST_RRHVU_Byte1 0;
BA_REL_ "GenSigTimeoutTime" BU_SG_REL_ RRHV SG_ 1799 GST_RRHVU_Byte1 0;
BA_REL_ "GenSigTimeoutTime" BU_SG_REL_ SHVU_RR SG_ 1799 GST_RRHVU_Byte1 0;
BA_REL_ "GenSigTimeoutTime" BU_SG_REL_ RRPSU SG_ 1799 GST_RRHVU_Byte1 0;
BA_ "NetworkRequest" SG_ 1799 GST_RRHVU_Byte1 0;
BA_ "NetworkRequestHoldingTime" SG_ 1799 GST_RRHVU_Byte1 5000;
BA_ "Version" SG_ 1799 GST_RRHVU_Byte1 "21.02.04";
BA_ "GenMsgCycleTime" BO_ 1499 0;
BA_ "GenMsgCycleTimeFast" BO_ 1499 0;
BA_ "GenMsgNrOfRepetition" BO_ 1499 0;
BA_ "DiagResponse" BO_ 1499 1;
BA_ "GenMsgILSupport" BO_ 1499 0;
BA_ "TpMessage" BO_ 1499 1;
BA_ "TpTxIndex" BO_ 1499 220;
BA_ "Description" SG_ 1499 HOD_GST_Byte0 "TP Index : 220";
BA_ "UsrSigPurpose" SG_ 1499 HOD_GST_Byte0 4;
BA_ "UserSigValidity" SG_ 1499 HOD_GST_Byte0 0;
BA_REL_ "GenSigTimeoutTime" BU_SG_REL_ CGW_CCU SG_ 1499 HOD_GST_Byte0 0;
BA_ "NetworkRequest" SG_ 1499 HOD_GST_Byte0 0;
BA_ "NetworkRequestHoldingTime" SG_ 1499 HOD_GST_Byte0 5000;
BA_ "Version" SG_ 1499 HOD_GST_Byte0 "21.02.04";
BA_ "Description" SG_ 1499 HOD_GST_Byte2 "TP Index : 220";
BA_ "UsrSigPurpose" SG_ 1499 HOD_GST_Byte2 4;
BA_ "UserSigValidity" SG_ 1499 HOD_GST_Byte2 0;
BA_REL_ "GenSigTimeoutTime" BU_SG_REL_ CGW_CCU SG_ 1499 HOD_GST_Byte2 0;
BA_ "NetworkRequest" SG_ 1499 HOD_GST_Byte2 0;
BA_ "NetworkRequestHoldingTime" SG_ 1499 HOD_GST_Byte2 5000;
BA_ "Version" SG_ 1499 HOD_GST_Byte2 "21.02.04";
BA_ "Description" SG_ 1499 HOD_GST_Byte3 "TP Index : 220";
BA_ "UsrSigPurpose" SG_ 1499 HOD_GST_Byte3 4;
BA_ "UserSigValidity" SG_ 1499 HOD_GST_Byte3 0;
BA_REL_ "GenSigTimeoutTime" BU_SG_REL_ CGW_CCU SG_ 1499 HOD_GST_Byte3 0;
BA_ "NetworkRequest" SG_ 1499 HOD_GST_Byte3 0;
BA_ "NetworkRequestHoldingTime" SG_ 1499 HOD_GST_Byte3 5000;
BA_ "Version" SG_ 1499 HOD_GST_Byte3 "21.02.04";
BA_ "Description" SG_ 1499 HOD_GST_Byte4 "TP Index : 220";
BA_ "UsrSigPurpose" SG_ 1499 HOD_GST_Byte4 4;
BA_ "UserSigValidity" SG_ 1499 HOD_GST_Byte4 0;
BA_REL_ "GenSigTimeoutTime" BU_SG_REL_ CGW_CCU SG_ 1499 HOD_GST_Byte4 0;
BA_ "NetworkRequest" SG_ 1499 HOD_GST_Byte4 0;
BA_ "NetworkRequestHoldingTime" SG_ 1499 HOD_GST_Byte4 5000;
BA_ "Version" SG_ 1499 HOD_GST_Byte4 "21.02.04";
BA_ "Description" SG_ 1499 HOD_GST_Byte5 "TP Index : 220";
BA_ "UsrSigPurpose" SG_ 1499 HOD_GST_Byte5 4;
BA_ "UserSigValidity" SG_ 1499 HOD_GST_Byte5 0;
BA_REL_ "GenSigTimeoutTime" BU_SG_REL_ CGW_CCU SG_ 1499 HOD_GST_Byte5 0;
BA_ "NetworkRequest" SG_ 1499 HOD_GST_Byte5 0;
BA_ "NetworkRequestHoldingTime" SG_ 1499 HOD_GST_Byte5 5000;
BA_ "Version" SG_ 1499 HOD_GST_Byte5 "21.02.04";
BA_ "Description" SG_ 1499 HOD_GST_Byte6 "TP Index : 220";
BA_ "UsrSigPurpose" SG_ 1499 HOD_GST_Byte6 4;
BA_ "UserSigValidity" SG_ 1499 HOD_GST_Byte6 0;
BA_REL_ "GenSigTimeoutTime" BU_SG_REL_ CGW_CCU SG_ 1499 HOD_GST_Byte6 0;
BA_ "NetworkRequest" SG_ 1499 HOD_GST_Byte6 0;
BA_ "NetworkRequestHoldingTime" SG_ 1499 HOD_GST_Byte6 5000;
BA_ "Version" SG_ 1499 HOD_GST_Byte6 "21.02.04";
BA_ "Description" SG_ 1499 HOD_GST_Byte7 "TP Index : 220";
BA_ "UsrSigPurpose" SG_ 1499 HOD_GST_Byte7 4;
BA_ "UserSigValidity" SG_ 1499 HOD_GST_Byte7 0;
BA_REL_ "GenSigTimeoutTime" BU_SG_REL_ CGW_CCU SG_ 1499 HOD_GST_Byte7 0;
BA_ "NetworkRequest" SG_ 1499 HOD_GST_Byte7 0;
BA_ "NetworkRequestHoldingTime" SG_ 1499 HOD_GST_Byte7 5000;
BA_ "Version" SG_ 1499 HOD_GST_Byte7 "21.02.04";
BA_ "Description" SG_ 1499 HOD_GST_Byte1 "TP Index : 220";
BA_ "UsrSigPurpose" SG_ 1499 HOD_GST_Byte1 4;
BA_ "UserSigValidity" SG_ 1499 HOD_GST_Byte1 0;
BA_REL_ "GenSigTimeoutTime" BU_SG_REL_ CGW_CCU SG_ 1499 HOD_GST_Byte1 0;
BA_ "NetworkRequest" SG_ 1499 HOD_GST_Byte1 0;
BA_ "NetworkRequestHoldingTime" SG_ 1499 HOD_GST_Byte1 5000;
BA_ "Version" SG_ 1499 HOD_GST_Byte1 "21.02.04";
BA_ "GenMsgSendType" BO_ 2319620609 0;
BA_ "GenMsgCycleTime" BO_ 2319620609 100;
BA_ "VFrameFormat" BO_ 2319620609 1;
BA_ "Description" SG_ 2319620609 HUD_HghtSta "This signal indicates that the HUD Height Status.";
BA_ "GenSigSendType" SG_ 2319620609 HUD_HghtSta 4;
BA_ "GenSigStartValue" SG_ 2319620609 HUD_HghtSta 9;
BA_ "UserSigValidity" SG_ 2319620609 HUD_HghtSta 3;
BA_ "Version" SG_ 2319620609 HUD_HghtSta "20.02.00";
BA_ "Description" SG_ 2319620609 HUD_PbackSta "Status signal for HUD interoperation with IMS

(The number of memory is expanded.)";
BA_ "GenSigSendType" SG_ 2319620609 HUD_PbackSta 4;
BA_ "UserSigValidity" SG_ 2319620609 HUD_PbackSta 3;
BA_REL_ "GenSigTimeoutTime" BU_SG_REL_ DPSU SG_ 2319620609 HUD_PbackSta 1500;
BA_ "Version" SG_ 2319620609 HUD_PbackSta "20.02.00";
BA_ "Description" SG_ 2319620609 HUD_BrgtnsSta "This signal indicates that the Hud Brightness Status.";
BA_ "GenSigSendType" SG_ 2319620609 HUD_BrgtnsSta 4;
BA_ "GenSigStartValue" SG_ 2319620609 HUD_BrgtnsSta 14;
BA_ "UserSigValidity" SG_ 2319620609 HUD_BrgtnsSta 3;
BA_ "Version" SG_ 2319620609 HUD_BrgtnsSta "20.02.00";
BA_ "Description" SG_ 2319620609 HUD_Type "the type of head up display (ex : combiner type, windshield type)";
BA_ "GenSigSendType" SG_ 2319620609 HUD_Type 4;
BA_ "GenSigStartValue" SG_ 2319620609 HUD_Type 3;
BA_ "TimeoutValue" SG_ 2319620609 HUD_Type "0x3";
BA_ "UserSigValidity" SG_ 2319620609 HUD_Type 3;
BA_ "Version" SG_ 2319620609 HUD_Type "20.04.02";
BA_ "Description" SG_ 2319620609 HUD_RotatSta "The status signal of HUD rotation";
BA_ "GenSigSendType" SG_ 2319620609 HUD_RotatSta 4;
BA_ "UserSigValidity" SG_ 2319620609 HUD_RotatSta 3;
BA_ "Version" SG_ 2319620609 HUD_RotatSta "20.02.00";
BA_ "Description" SG_ 2319620609 HUD_setSW "the status of head up display on/off";
BA_ "GenSigSendType" SG_ 2319620609 HUD_setSW 4;
BA_ "UserSigValidity" SG_ 2319620609 HUD_setSW 3;
BA_ "Version" SG_ 2319620609 HUD_setSW "20.02.00";
BA_ "Description" SG_ 2319620609 HUD_ContentsTBTStatus "this signal shows the display contents setting status of TBT on HUD";
BA_ "GenSigSendType" SG_ 2319620609 HUD_ContentsTBTStatus 4;
BA_ "GenSigStartValue" SG_ 2319620609 HUD_ContentsTBTStatus 1;
BA_ "UserSigValidity" SG_ 2319620609 HUD_ContentsTBTStatus 3;
BA_ "Version" SG_ 2319620609 HUD_ContentsTBTStatus "20.02.00";
BA_ "Description" SG_ 2319620609 HUD_ContentsDISStatus "this signal shows the display contents status of DIS on HUD";
BA_ "GenSigSendType" SG_ 2319620609 HUD_ContentsDISStatus 4;
BA_ "GenSigStartValue" SG_ 2319620609 HUD_ContentsDISStatus 1;
BA_ "UserSigValidity" SG_ 2319620609 HUD_ContentsDISStatus 3;
BA_ "Version" SG_ 2319620609 HUD_ContentsDISStatus "20.02.00";
BA_ "Description" SG_ 2319620609 HUD_ContentsSCCStatus "this signal shows the display contents status of SCC on HUD";
BA_ "GenSigSendType" SG_ 2319620609 HUD_ContentsSCCStatus 4;
BA_ "GenSigStartValue" SG_ 2319620609 HUD_ContentsSCCStatus 1;
BA_ "UserSigValidity" SG_ 2319620609 HUD_ContentsSCCStatus 3;
BA_ "Version" SG_ 2319620609 HUD_ContentsSCCStatus "20.02.00";
BA_ "Description" SG_ 2319620609 HUD_SportHUD "this signal shows the display contents status of Sport mode HUD";
BA_ "GenSigSendType" SG_ 2319620609 HUD_SportHUD 4;
BA_ "GenSigStartValue" SG_ 2319620609 HUD_SportHUD 3;
BA_ "UserSigValidity" SG_ 2319620609 HUD_SportHUD 3;
BA_ "Version" SG_ 2319620609 HUD_SportHUD "20.03.02";
BA_ "Description" SG_ 2319620609 HUD_ContentsBCWStatus "this signal shows the display contents status of BCW on HUD";
BA_ "GenSigSendType" SG_ 2319620609 HUD_ContentsBCWStatus 4;
BA_ "GenSigStartValue" SG_ 2319620609 HUD_ContentsBCWStatus 1;
BA_ "UserSigValidity" SG_ 2319620609 HUD_ContentsBCWStatus 3;
BA_ "Version" SG_ 2319620609 HUD_ContentsBCWStatus "20.02.00";
BA_ "Description" SG_ 2319620609 HUD_ContentsAVStatus "this signal shows the display contents status of AV on HUD";
BA_ "GenSigSendType" SG_ 2319620609 HUD_ContentsAVStatus 4;
BA_ "UserSigValidity" SG_ 2319620609 HUD_ContentsAVStatus 3;
BA_ "Version" SG_ 2319620609 HUD_ContentsAVStatus "20.02.00";
BA_ "Description" SG_ 2319620609 HUD_ContentsSpeedStatus "this signal shows the Speedometer contents status of HUD";
BA_ "GenSigSendType" SG_ 2319620609 HUD_ContentsSpeedStatus 4;
BA_ "GenSigStartValue" SG_ 2319620609 HUD_ContentsSpeedStatus 3;
BA_ "UserSigValidity" SG_ 2319620609 HUD_ContentsSpeedStatus 3;
BA_ "Version" SG_ 2319620609 HUD_ContentsSpeedStatus "20.10.02";
BA_ "Description" SG_ 2319620609 HUD_ImsAutoSaveStatus "this signal shows that Ims Auto Save function status";
BA_ "GenSigSendType" SG_ 2319620609 HUD_ImsAutoSaveStatus 4;
BA_ "GenSigStartValue" SG_ 2319620609 HUD_ImsAutoSaveStatus 3;
BA_ "UserSigValidity" SG_ 2319620609 HUD_ImsAutoSaveStatus 3;
BA_ "Version" SG_ 2319620609 HUD_ImsAutoSaveStatus "20.12.04";
BA_ "GenMsgCycleTime" BO_ 942 0;
BA_ "Description" SG_ 942 AMP_Beep1VolumeStep "16.03.03_";
BA_ "GenSigSendType" SG_ 942 AMP_Beep1VolumeStep 4;
BA_ "GenSigStartValue" SG_ 942 AMP_Beep1VolumeStep 255;
BA_ "UserSigValidity" SG_ 942 AMP_Beep1VolumeStep 1;
BA_REL_ "GenSigTimeoutTime" BU_SG_REL_ ATS SG_ 942 AMP_Beep1VolumeStep 0;
BA_ "NetworkRequest" SG_ 942 AMP_Beep1VolumeStep 0;
BA_ "Version" SG_ 942 AMP_Beep1VolumeStep "19.02.03";
BA_ "Description" SG_ 942 AMP_Analog_OutputCh_Select "Command for Set Analog Output Channel to identify which Speakers will output Sound

- per bit, 0 means 'Not Output Channel' and 1 means 'Output Channel'

bit0 : FL / bit1 : FR / bit2 : RL / bit3 : RR / bit4 : CTR / bit5 : Surround L /

bit6 : Surround R / bit7 : SWF / bit8 : Headrest L / bit9 : Headrest R / bit10 : Loof L /

bit11 : Loof CTR / bit12 : Loof R / bit13~bit15 : Reserved

- This Signal's Feedback is AMP_Analog_OutputCh_State@AMP";
BA_ "GenSigSendType" SG_ 942 AMP_Analog_OutputCh_Select 4;
BA_ "UserSigValidity" SG_ 942 AMP_Analog_OutputCh_Select 1;
BA_ "Version" SG_ 942 AMP_Analog_OutputCh_Select "20.01.01";
BA_ "Description" SG_ 942 AMP_Beep1_OutputCh_Select "Command for Set Beep1 Output Channel to identify which Speakers will output Sound

- per bit, 0 means 'Not Output Channel' and 1 means 'Output Channel'

bit0 : FL / bit1 : FR / bit2 : RL / bit3 : RR / bit4 : CTR / bit5 : Surround L /

bit6 : Surround R / bit7 : SWF / bit8 : Headrest L / bit9 : Headrest R / bit10 : Loof L /

bit11 : Loof CTR / bit12 : Loof R / bit13~bit15 : Reserved

- This Signal's Feedback is AMP_Beep1_OutputCh_State@AMP";
BA_ "GenSigSendType" SG_ 942 AMP_Beep1_OutputCh_Select 4;
BA_ "GenSigStartValue" SG_ 942 AMP_Beep1_OutputCh_Select 65535;
BA_ "UserSigValidity" SG_ 942 AMP_Beep1_OutputCh_Select 1;
BA_ "Version" SG_ 942 AMP_Beep1_OutputCh_Select "19.12.08";
BA_ "Description" SG_ 942 AMP_Beep1KBDVolumeStep "Command for AVN keyboard Touch Beep Sound Volume Setting 

-range : 0 ~ max

-max : value of AMP_MaxBeep1VolumeState

This Signal's Feedback is AMP_Beep1KBDVolumeState@AMP";
BA_ "GenSigSendType" SG_ 942 AMP_Beep1KBDVolumeStep 4;
BA_ "GenSigStartValue" SG_ 942 AMP_Beep1KBDVolumeStep 255;
BA_ "UserSigValidity" SG_ 942 AMP_Beep1KBDVolumeStep 1;
BA_ "Version" SG_ 942 AMP_Beep1KBDVolumeStep "20.06.01";
BA_ "Description" SG_ 942 AMP_SPDIF_OutputCh_Select "Command for Set SPDIF Output Channel to identify which Speakers will output Sound

- per bit, 0 means 'Not Output Channel' and 1 means 'Output Channel'

bit0 : FL / bit1 : FR / bit2 : RL / bit3 : RR / bit4 : CTR / bit5 : Surround L /

bit6 : Surround R / bit7 : SWF / bit8 : Headrest L / bit9 : Headrest R / bit10 : Loof L /

bit11 : Loof CTR / bit12 : Loof R / bit13~bit15 : Reserved

- This Signal's Feedback is AMP_SPDIF_OutputCh_State@AMP";
BA_ "GenSigSendType" SG_ 942 AMP_SPDIF_OutputCh_Select 4;
BA_ "GenSigStartValue" SG_ 942 AMP_SPDIF_OutputCh_Select 255;
BA_ "UserSigValidity" SG_ 942 AMP_SPDIF_OutputCh_Select 1;
BA_ "Version" SG_ 942 AMP_SPDIF_OutputCh_Select "19.12.02";
BA_ "GenMsgSendType" BO_ 2164279809 0;
BA_ "GenMsgCycleTime" BO_ 2164279809 50;
BA_ "GenMsgCycleTimeFast" BO_ 2164279809 0;
BA_ "GenMsgNrOfRepetition" BO_ 2164279809 0;
BA_ "VFrameFormat" BO_ 2164279809 1;
BA_ "Description" SG_ 2164279809 IMU_Crc1Val "The data area for CRC calculation is based on the data length (DLC) of the message DB.

The CRC shall be calculated over the entire data block (excluding the CRC bytes) including the user data, alive counter and Data ID

 

- CRC Polynomial (0x1021) , Initial Value : 0xFFFF, XOR value : 0x0000, Data ID : Message ID + 0xF800 

- The initial value is for CRC calculation and the message should be sent with the calculated result value. 

- The mathematical expression to 16 bit CRC polynomial is given here. G(x) = x16 + x12 + x5 + 1";
BA_ "GenSigStartValue" SG_ 2164279809 IMU_Crc1Val 65535;
BA_ "UserSigValidity" SG_ 2164279809 IMU_Crc1Val 3;
BA_ "RoutingFactor" SG_ 2164279809 IMU_Crc1Val 5;
BA_ "Version" SG_ 2164279809 IMU_Crc1Val "20.06.01";
BA_ "Description" SG_ 2164279809 IMU_AlvCnt1Val "For the first transmission request for a data element the counter shall be initialized with 0 and shall be incremented by 1 for every subsequent send request. 

When the counter reaches the maximum value(0xFF), then it shall restart with 0 for the next send request";
BA_ "UserSigValidity" SG_ 2164279809 IMU_AlvCnt1Val 3;
BA_ "RoutingFactor" SG_ 2164279809 IMU_AlvCnt1Val 5;
BA_ "Version" SG_ 2164279809 IMU_AlvCnt1Val "20.06.01";
BA_ "Description" SG_ 2164279809 IMU_YawSigSta "This signal indicates failure status of yaw rate signal and yaw rate sensing element.



0000B : No failure 



xxx1B : IMU_Yawrate_failure



xx1xB : Initialization is running



x1xxB : Reserved



1xxxB : Reserved



This signal represents the physical error in MEMs sensor or microprocessor error in air bag control unit, but it does not contain the signal plausibility error check result. Signal plausibility error check has to be accomplished to each control unit using the own plausibility error check criterion.



The initialization time is the time that takes for the sensor to operate normally after power on. The maximum initialization time does not exceed the ACU CAN valid message transmission time. In the initial startup condition, the time does not exceed 1500ms and In case of ACU Only Reset, it does not 600ms.



The sensor status information is selected from one among 0000B, xxx1B, and xx1xB.";
BA_ "GenSigStartValue" SG_ 2164279809 IMU_YawSigSta 2;
BA_ "UserSigValidity" SG_ 2164279809 IMU_YawSigSta 3;
BA_ "RoutingFactor" SG_ 2164279809 IMU_YawSigSta 5;
BA_ "Version" SG_ 2164279809 IMU_YawSigSta "20.03.05";
BA_ "Description" SG_ 2164279809 IMU_LatAccelSigSta "This signal indicates failure status of lateral acceleration signal and sensing element.



0000B : No failure



xxx1B : IMU_Lateral acceleration failure



xx1xB : Initialization is running



x1xxB : Reserved



1xxxB : Reserved



This signal represents the physical error in MEMs sensor or microprocessor error in air bag control unit, but it does not contain the signal plausibility error check result. Signal plausibility error check has to be accomplished to each control unit using the own plausibility error check criterion.



The initialization time is the time that takes for the sensor to operate normally after power on. The maximum initialization time does not exceed the ACU CAN valid message transmission time. In the initial startup condition, the time does not exceed 1500ms and In case of ACU Only Reset, it does not 600ms.



The sensor status information is selected from one among 0000B, xxx1B, and xx1xB.";
BA_ "GenSigStartValue" SG_ 2164279809 IMU_LatAccelSigSta 2;
BA_ "UserSigValidity" SG_ 2164279809 IMU_LatAccelSigSta 3;
BA_ "RoutingFactor" SG_ 2164279809 IMU_LatAccelSigSta 5;
BA_ "Version" SG_ 2164279809 IMU_LatAccelSigSta "20.03.05";
BA_ "Description" SG_ 2164279809 IMU_LongAccelSigSta "This signal indicates failure status of longitudinal acceleration signal and sensing element.



0000B : No failure 



xxx1B : IMU_Longitudial acceleration failure



xx1xB : Initialization is running



x1xxB : Reserved



1xxxB : Reserved



This signal represents the physical error in MEMs sensor or microprocessor error in air bag control unit, but it does not contain the signal plausibility error check result. Signal plausibility error check has to be accomplished to each control unit using the own plausibility error check criterion.



The initialization time is the time that takes for the sensor to operate normally after power on. The maximum initialization time does not exceed the ACU CAN valid message transmission time. In the initial startup condition, the time does not exceed 1500ms and In case of ACU Only Reset, it does not 600ms.



The sensor status information is selected from one among 0000B, xxx1B, and xx1xB.";
BA_ "GenSigStartValue" SG_ 2164279809 IMU_LongAccelSigSta 2;
BA_ "UserSigValidity" SG_ 2164279809 IMU_LongAccelSigSta 3;
BA_ "RoutingFactor" SG_ 2164279809 IMU_LongAccelSigSta 5;
BA_ "Version" SG_ 2164279809 IMU_LongAccelSigSta "20.03.05";
BA_ "Description" SG_ 2164279809 IMU_VerAccelSigSta "This signal indicates failure status of  vertial acceleration signal and yaw rate sensing element.



0000B : No failure 



xxx1B : IMU_Vertial acceleration failure



xx1xB : Initialization is running



x1xxB : Reserved



1xxxB : Reserved



This signal represents the physical error in MEMs sensor or microprocessor error in air bag control unit, but it does not contain the signal plausibility error check result. Signal plausibility error check has to be accomplished to each control unit using the own plausibility error check criterion.



The initialization time is the time that takes for the sensor to operate normally after power on. The maximum initialization time does not exceed the ACU CAN valid message transmission time. In the initial startup condition, the time does not exceed 1500ms and In case of ACU Only Reset, it does not 600ms.



The sensor status information is selected from one among 0000B, xxx1B, and xx1xB.";
BA_ "GenSigStartValue" SG_ 2164279809 IMU_VerAccelSigSta 2;
BA_ "UserSigValidity" SG_ 2164279809 IMU_VerAccelSigSta 3;
BA_ "RoutingFactor" SG_ 2164279809 IMU_VerAccelSigSta 5;
BA_ "Version" SG_ 2164279809 IMU_VerAccelSigSta "20.03.05";
BA_ "Description" SG_ 2164279809 IMU_McuVoltSta "This signal indicates the failure status of MCU.



0000B : No failure



xxx1B : MCU failure



xx1xB : Under voltage detected



x1xxB : Over voltage detected



1xxxB : Bus off failure



The status information(xxx1B) occurs when MCU error is detected or qualified. Low-voltage detected bit(xx1xB) and high-voltage detected bit(x1xxB) mean the vehicle ignition voltage status diagnosed by ACU, which do not indicate the MCU failure status.";
BA_ "UserSigValidity" SG_ 2164279809 IMU_McuVoltSta 3;
BA_ "RoutingFactor" SG_ 2164279809 IMU_McuVoltSta 5;
BA_ "Version" SG_ 2164279809 IMU_McuVoltSta "20.03.05";
BA_ "Description" SG_ 2164279809 IMU_AcuRstSta "This signal indicates the status of IMU.



0000B : Normal mode 



xxx1B : IMU Reset mode



xx1xB : Reserved



x1xxB : Reserved



1xxxB : Reserved



If ACU reset is required, ACU will send IMU RESET bit(XXX1B) up to 30 times and perform a reset. If RESET acknowledge signal is received from the ESC, the ACU interrupts the reset signal transmission and performs a reset immediately. Detailed logic follows ES95920-75.";
BA_ "UserSigValidity" SG_ 2164279809 IMU_AcuRstSta 3;
BA_ "RoutingFactor" SG_ 2164279809 IMU_AcuRstSta 5;
BA_ "Version" SG_ 2164279809 IMU_AcuRstSta "20.03.05";
BA_ "Description" SG_ 2164279809 IMU_SnsrTyp "This signal indicates supported signals that are correspond to sensor type.

0001B = IMU (yaw rate and lateral acceleration)

0010B = IMU (yaw rate, lateral and longitudinal acceleration)

0100B = IMU (yaw / roll rate, lateral and longitudinal acceleration)

1000B = IMU (yaw / roll rate, lateral, longitudinal and vertical acceleration)

All other values are reserved

¡Ø Initial value shall be actual value.

This signal indicates all sensor types available for the corresponding vehicle. whether to provide actual sensor information for each vehicle is determined according to a PEL (Product equipment list) component.";
BA_ "GenSigStartValue" SG_ 2164279809 IMU_SnsrTyp 2;
BA_ "UserSigValidity" SG_ 2164279809 IMU_SnsrTyp 3;
BA_ "RoutingFactor" SG_ 2164279809 IMU_SnsrTyp 5;
BA_ "Version" SG_ 2164279809 IMU_SnsrTyp "20.03.05";
BA_ "Description" SG_ 2164279809 IMU_RollSigSta "This signal indicates failure status of roll rate signal and roll rate sensing element.



0000B : No failure 



xxx1B : IMU_Roll rate failure



xx1xB : Initialization is running



x1xxB : Reserved



1xxxB : Reserved



This signal represents the physical error in MEMs sensor or microprocessor error in air bag control unit, but it does not contain the signal plausibility error check result. Signal plausibility error check has to be accomplished to each control unit using the own plausibility error check criterion.



The initialization time is the time that takes for the sensor to operate normally after power on. The maximum initialization time does not exceed the ACU CAN valid message transmission time. In the initial startup condition, the time does not exceed 1500ms and In case of ACU Only Reset, it does not 600ms.



The sensor status information is selected from one among 0000B, xxx1B, and xx1xB.";
BA_ "GenSigStartValue" SG_ 2164279809 IMU_RollSigSta 2;
BA_ "UserSigValidity" SG_ 2164279809 IMU_RollSigSta 3;
BA_ "RoutingFactor" SG_ 2164279809 IMU_RollSigSta 5;
BA_ "Version" SG_ 2164279809 IMU_RollSigSta "20.03.05";
BA_ "GenMsgSendType" BO_ 2164279810 0;
BA_ "GenMsgCycleTime" BO_ 2164279810 50;
BA_ "GenMsgCycleTimeFast" BO_ 2164279810 0;
BA_ "GenMsgNrOfRepetition" BO_ 2164279810 0;
BA_ "VFrameFormat" BO_ 2164279810 1;
BA_ "Description" SG_ 2164279810 IMU_YawRtVal "This signal indicates Information regarding yaw rate.



physical range : -163.84..163.83 ¢ª/s = 0000H..FFFEh



Conversion : (PH) = ((HEX)-8000H)*0.005[¢ª/s/digit]



                            = (HEX)*0.005[¢ª/s/digit] - 163.84[¢ª/s]



                     FFFFh = Error 



Physical range and the resolution applied to the conversion rules may differ from the actual sensor specifications specified in the ES95920-75.



If the digital output range of the actual sensor is over -163.84¡Æ/s ~ +163.83¡Æ/s, CAN message will show minimum and the maximum values. However, if the digital output range of the actual sensor is smaller than physical range of CAN, CAN message will only output to the maximum and minimum values of the digital output.";
BA_ "GenSigStartValue" SG_ 2164279810 IMU_YawRtVal 32768;
BA_ "UserSigValidity" SG_ 2164279810 IMU_YawRtVal 3;
BA_ "RoutingFactor" SG_ 2164279810 IMU_YawRtVal 5;
BA_ "Version" SG_ 2164279810 IMU_YawRtVal "20.03.05";
BA_ "Description" SG_ 2164279810 IMU_LatAccelVal "This signal indicates Information regarding lateral acceleration.



physical range : -4.1768g..4.1765g = 0000H..FFFEh



Conversion : (PH) = ((HEX)-8000H)*0.000127465[g/digit]



                            = (HEX)*0.000127465[g/digit] - 4.17677312[g]



                    FFFFh = Error



Physical range and the resolution applied to the conversion rules may differ from the actual sensor specifications specified in the ES95920-75.



If the digital output range of the actual sensor is over -4.1768g..4.1765g, CAN message will show minimum and the maximum values. However, if the digital output range of the actual sensor is smaller than physical range of CAN, CAN message will only output to the maximum and minimum values of the digital output.";
BA_ "GenSigStartValue" SG_ 2164279810 IMU_LatAccelVal 32768;
BA_ "UserSigValidity" SG_ 2164279810 IMU_LatAccelVal 3;
BA_ "RoutingFactor" SG_ 2164279810 IMU_LatAccelVal 5;
BA_ "Version" SG_ 2164279810 IMU_LatAccelVal "20.03.05";
BA_ "Description" SG_ 2164279810 IMU_LongAccelVal "This signal indicates information regarding longitudinal acceleration.



physical range : -4.1768g..4.1765g = 0000H..FFFEh



Conversion : (PH) = ((HEX)-8000H)*0.000127465[g/digit]



                            = (HEX)*0.000127465[g/digit] - 4.17677312[g]



                     FFFFh = Error



Physical range and the resolution applied to the conversion rules may differ from the actual sensor specifications specified in the ES95920-75.



If the digital output range of the actual sensor is over -4.1768g..4.1765g, CAN message will show minimum and the maximum values. However, if the digital output range of the actual sensor is smaller than physical range of CAN, CAN message will only output to the maximum and minimum values of the digital output.";
BA_ "GenSigStartValue" SG_ 2164279810 IMU_LongAccelVal 32768;
BA_ "UserSigValidity" SG_ 2164279810 IMU_LongAccelVal 3;
BA_ "RoutingFactor" SG_ 2164279810 IMU_LongAccelVal 5;
BA_ "Version" SG_ 2164279810 IMU_LongAccelVal "20.03.05";
BA_ "Description" SG_ 2164279810 IMU_SnsrTempVal "The temperature is measured on sensing element chip in ACU, so it may be different from the display indicator temperature of the vehicle.



Physical range: -68¡ÆC = 00h, +60 ¡ÆC = 80h, +187¡ÆC = FFh



Quantization LSB: 1[¡ÆC/digit]



Temperature [¡ÆC] = (Hex value - 80h) * 1 [¡ÆC/digit] + 60[¡ÆC]



                           = (Hex value) * 1 [¡ÆC/digit] - 68[¡ÆC]



¡Ø Start Value : 44h

¡ØThis information is only for chipset with yaw sensor.";
BA_ "GenSigStartValue" SG_ 2164279810 IMU_SnsrTempVal 68;
BA_ "UserSigValidity" SG_ 2164279810 IMU_SnsrTempVal 3;
BA_ "RoutingFactor" SG_ 2164279810 IMU_SnsrTempVal 5;
BA_ "Version" SG_ 2164279810 IMU_SnsrTempVal "20.03.05";
BA_ "GenMsgSendType" BO_ 2164279811 0;
BA_ "GenMsgCycleTime" BO_ 2164279811 50;
BA_ "GenMsgCycleTimeFast" BO_ 2164279811 0;
BA_ "GenMsgNrOfRepetition" BO_ 2164279811 0;
BA_ "VFrameFormat" BO_ 2164279811 1;
BA_ "Description" SG_ 2164279811 IMU_SeralNumVal "IMU serial number in range of 



0x000000000000 = 0......0xFFFFFFFFFFFF

¡ØInitial value shall be actual value

¡ØThis information is only for chipset with yaw sensor.";
BA_ "UserSigValidity" SG_ 2164279811 IMU_SeralNumVal 3;
BA_ "RoutingFactor" SG_ 2164279811 IMU_SeralNumVal 5;
BA_ "Version" SG_ 2164279811 IMU_SeralNumVal "20.03.05";
BA_ "GenMsgSendType" BO_ 2164279812 0;
BA_ "GenMsgCycleTime" BO_ 2164279812 50;
BA_ "GenMsgCycleTimeFast" BO_ 2164279812 0;
BA_ "GenMsgNrOfRepetition" BO_ 2164279812 0;
BA_ "VFrameFormat" BO_ 2164279812 1;
BA_ "Description" SG_ 2164279812 IMU_RollRtVal "This signal indicates Information regarding Roll rate.



physical range : -163.84..163.83 ¢ª/s = 0000H..FFFEh



Conversion : (PH) = ((HEX)-8000H)*0.005[¢ª/s/digit]



                            = (HEX)*0.005[¢ª/s/digit] - 163.84[¢ª/s]



                     FFFFh = Error 



Physical range and the resolution applied to the conversion rules may differ from the actual sensor requirement specifications specified in the ES95920-75.



If the digital output range of the actual sensor is over -163.84¡Æ/s ~ +163.83¡Æ/s, CAN message will show minimum and the maximum values. However, if the digital output range of the actual sensor is smaller than physical range of CAN, CAN message will only output to the maximum and minimum values of the digital output.



This signal does not carry out the zero compensation of the sensor itself or the vehicle level. If necessary, a separate compensation logic should be implemented in the receiving controller.";
BA_ "GenSigStartValue" SG_ 2164279812 IMU_RollRtVal 32768;
BA_ "UserSigValidity" SG_ 2164279812 IMU_RollRtVal 3;
BA_ "RoutingFactor" SG_ 2164279812 IMU_RollRtVal 5;
BA_ "Version" SG_ 2164279812 IMU_RollRtVal "20.03.05";
BA_ "Description" SG_ 2164279812 IMU_VerAccelVal "This signal indicates Information regarding Vertical acceleration.



physical range : -4.1768g..4.1765g = 0000H..FFFEh



Conversion : (PH) = ((HEX)-8000H)*0.000127465[g/digit]



                            = (HEX)*0.000127465[g/digit] - 4.17677312[g]



                    FFFFh = Error



Physical range and the resolution applied to the conversion rules may differ from the actual sensor requirement specifications specified in the ES95920-75.



If the digital output range of the actual sensor is over -4.1768g..4.1765g, CAN message will show minimum and the maximum values. However, if the digital output range of the actual sensor is smaller than physical range of CAN, CAN message will only output to the maximum and minimum values of the digital output.

This signal does not carry out the zero compensation of the sensor itself or the vehicle level. If necessary, a separate compensation logic should be implemented in the receiving controller.";
BA_ "GenSigStartValue" SG_ 2164279812 IMU_VerAccelVal 32768;
BA_ "UserSigValidity" SG_ 2164279812 IMU_VerAccelVal 3;
BA_ "RoutingFactor" SG_ 2164279812 IMU_VerAccelVal 5;
BA_ "Version" SG_ 2164279812 IMU_VerAccelVal "20.03.05";
BA_ "GenMsgSendType" BO_ 939 0;
BA_ "GenMsgCycleTimeFast" BO_ 939 0;
BA_ "GenMsgNrOfRepetition" BO_ 939 0;
BA_ "Description" SG_ 939 PSB_Crc1Val "The data area for CRC calculation is based on the data length (DLC) of the message DB.

The CRC shall be calculated over the entire data block (excluding the CRC bytes) including the user data, alive counter and Data ID 

 

- CRC Polynomial (0x1D) , Initial Value : 0x00, XOR value : 0xFF, Data ID Mode : Both, Data ID : Message ID + 0xF800 

- The initial value is for CRC calculation and the message should be sent with the calculated result value. 

The mathematical expression to 8 bit CRC polynomial is given here. G(x) = x8 + x4 + x3 + x2 + 1";
BA_ "UserSigValidity" SG_ 939 PSB_Crc1Val 0;
BA_REL_ "GenSigTimeoutTime" BU_SG_REL_ CGW_CCU SG_ 939 PSB_Crc1Val 1500;
BA_ "Version" SG_ 939 PSB_Crc1Val "18.11.08";
BA_ "Description" SG_ 939 PSB_AlvCnt1Val "For the first transmission request for a data element the counter shall be initialized with 0 and shall be incremented by 1

for every subsequent send request. When the counter reaches the maximum value(0xE), then it shall restart with 0 for the next send request";
BA_ "UserSigValidity" SG_ 939 PSB_AlvCnt1Val 0;
BA_REL_ "GenSigTimeoutTime" BU_SG_REL_ CGW_CCU SG_ 939 PSB_AlvCnt1Val 1500;
BA_ "Version" SG_ 939 PSB_AlvCnt1Val "18.11.08";
BA_ "Description" SG_ 939 PSB_LHFlrSta "Information about availability of PSB_LH (LH Pre-Safe S/Belt).";
BA_ "UserSigValidity" SG_ 939 PSB_LHFlrSta 0;
BA_REL_ "GenSigTimeoutTime" BU_SG_REL_ CGW_CCU SG_ 939 PSB_LHFlrSta 1500;
BA_ "Version" SG_ 939 PSB_LHFlrSta "18.02.03";
BA_ "Description" SG_ 939 PSB_LHActvSta "Seat belt active state. This signal is for the monitoring of Pre-Safe S/Belt.

If there is a request, but no realization by the Pre-Safe S/Belt -> failure entry in the SCC(Radar).";
BA_ "UserSigValidity" SG_ 939 PSB_LHActvSta 0;
BA_REL_ "GenSigTimeoutTime" BU_SG_REL_ CGW_CCU SG_ 939 PSB_LHActvSta 1500;
BA_ "Version" SG_ 939 PSB_LHActvSta "18.02.03";
BA_ "Description" SG_ 939 PSB_RHFlrSta "Information about availability of PSB_RH (LH Pre-Safe S/Belt).";
BA_ "UserSigValidity" SG_ 939 PSB_RHFlrSta 0;
BA_REL_ "GenSigTimeoutTime" BU_SG_REL_ CGW_CCU SG_ 939 PSB_RHFlrSta 1500;
BA_ "Version" SG_ 939 PSB_RHFlrSta "18.02.03";
BA_ "Description" SG_ 939 PSB_RHActvSta "Seat belt active state. This signal is for the monitoring of Pre-Safe S/Belt.

If there is a request, but no realization by the Pre-Safe S/Belt -> failure entry in the SCC(Radar).";
BA_ "UserSigValidity" SG_ 939 PSB_RHActvSta 0;
BA_REL_ "GenSigTimeoutTime" BU_SG_REL_ APSU SG_ 939 PSB_RHActvSta 1500;
BA_REL_ "GenSigTimeoutTime" BU_SG_REL_ CGW_CCU SG_ 939 PSB_RHActvSta 1500;
BA_ "Version" SG_ 939 PSB_RHActvSta "18.02.03";
BA_ "Description" SG_ 939 PSB_ActForAcu "This signal indicates status of Pre-Safe S/Belt activation by ACU commends.";
BA_ "UserSigValidity" SG_ 939 PSB_ActForAcu 0;
BA_REL_ "GenSigTimeoutTime" BU_SG_REL_ CGW_CCU SG_ 939 PSB_ActForAcu 1500;
BA_ "Version" SG_ 939 PSB_ActForAcu "18.02.03";
BA_ "Description" SG_ 939 PSB_HapticWarnSta "This signal indicates sattus of Pre-active S/Belt Haptic activation by HDP commends";
BA_ "UserSigValidity" SG_ 939 PSB_HapticWarnSta 0;
BA_REL_ "GenSigTimeoutTime" BU_SG_REL_ CGW_CCU SG_ 939 PSB_HapticWarnSta 1500;
BA_ "Version" SG_ 939 PSB_HapticWarnSta "20.03.00";
BA_ "Description" SG_ 939 PSB_RHActForPss "Seat belt active state. 

This signal is for the monitoring of Pre-Safe S/Belt  in conjunction with PSS.

If there is a request, but no realization by the Pre-Safe S/Belt -> failure entry in the SCC(Radar).";
BA_ "UserSigValidity" SG_ 939 PSB_RHActForPss 0;
BA_REL_ "GenSigTimeoutTime" BU_SG_REL_ APSU SG_ 939 PSB_RHActForPss 1500;
BA_REL_ "GenSigTimeoutTime" BU_SG_REL_ RLPSU SG_ 939 PSB_RHActForPss 1500;
BA_REL_ "GenSigTimeoutTime" BU_SG_REL_ RRPSU SG_ 939 PSB_RHActForPss 1500;
BA_ "Version" SG_ 939 PSB_RHActForPss "21.04.00";
BA_ "Description" SG_ 939 PSB_LHActForPss "Seat belt active state. 

This signal is for the monitoring of Pre-Safe S/Belt in conjunction with PSS.

If there is a request, but no realization by the Pre-Safe S/Belt -> failure entry in the SCC(Radar).";
BA_ "UserSigValidity" SG_ 939 PSB_LHActForPss 0;
BA_REL_ "GenSigTimeoutTime" BU_SG_REL_ RLPSU SG_ 939 PSB_LHActForPss 1500;
BA_REL_ "GenSigTimeoutTime" BU_SG_REL_ RRPSU SG_ 939 PSB_LHActForPss 1500;
BA_ "Version" SG_ 939 PSB_LHActForPss "21.04.00";
BA_ "GenMsgSendType" BO_ 934 0;
BA_ "Description" SG_ 934 PTGM_Crc1Val "The data area for CRC calculation is based on the data length (DLC) of the message DB.

The CRC shall be calculated over the entire data block (excluding the CRC bytes) including the user data, alive counter and Data ID 

 

- CRC Polynomial (0x1D) , Initial Value : 0x00, XOR value : 0xFF, Data ID Mode : Both, Data ID : Message ID + 0xF800 

- The initial value is for CRC calculation and the message should be sent with the calculated result value. 

The mathematical expression to 8 bit CRC polynomial is given here. G(x) = x8 + x4 + x3 + x2 + 1";
BA_ "GenSigSendType" SG_ 934 PTGM_Crc1Val 4;
BA_ "GenSigStartValue" SG_ 934 PTGM_Crc1Val 255;
BA_ "UserSigValidity" SG_ 934 PTGM_Crc1Val 0;
BA_ "Version" SG_ 934 PTGM_Crc1Val "18.11.08";
BA_ "Description" SG_ 934 PTGM_AlvCnt1Val "For the first transmission request for a data element the counter shall be initialized with 0 and shall be incremented by 1

for every subsequent send request. When the counter reaches the maximum value(0xE), then it shall restart with 0 for the next send request";
BA_ "GenSigSendType" SG_ 934 PTGM_AlvCnt1Val 4;
BA_ "UserSigValidity" SG_ 934 PTGM_AlvCnt1Val 0;
BA_ "Version" SG_ 934 PTGM_AlvCnt1Val "18.11.08";
BA_ "Description" SG_ 934 PTGM_HazardSta "-(Old)C_PTHazard";
BA_ "GenSigSendType" SG_ 934 PTGM_HazardSta 4;
BA_ "GenSigStartValue" SG_ 934 PTGM_HazardSta 2;
BA_ "UserSigValidity" SG_ 934 PTGM_HazardSta 0;
BA_ "NetworkRequest" SG_ 934 PTGM_HazardSta 0;
BA_ "NetworkRequestHoldingTime" SG_ 934 PTGM_HazardSta 5000;
BA_ "Version" SG_ 934 PTGM_HazardSta "21.07.05";
BA_ "Description" SG_ 934 PTGM_ModSta "PTGM Moudule Status";
BA_ "GenSigSendType" SG_ 934 PTGM_ModSta 4;
BA_ "UserSigValidity" SG_ 934 PTGM_ModSta 0;
BA_ "NetworkRequest" SG_ 934 PTGM_ModSta 0;
BA_ "NetworkRequestHoldingTime" SG_ 934 PTGM_ModSta 5000;
BA_ "Version" SG_ 934 PTGM_ModSta "21.07.05";
BA_ "Description" SG_ 934 PTGM_MovSta "PTGM Status (stop or moving)";
BA_ "GenSigSendType" SG_ 934 PTGM_MovSta 4;
BA_ "UserSigValidity" SG_ 934 PTGM_MovSta 0;
BA_ "NetworkRequest" SG_ 934 PTGM_MovSta 0;
BA_ "NetworkRequestHoldingTime" SG_ 934 PTGM_MovSta 5000;
BA_ "Version" SG_ 934 PTGM_MovSta "21.07.05";
BA_ "GenSigSendType" SG_ 934 PTGM_OptTyp 4;
BA_ "UserSigValidity" SG_ 934 PTGM_OptTyp 0;
BA_ "NetworkRequest" SG_ 934 PTGM_OptTyp 0;
BA_ "NetworkRequestHoldingTime" SG_ 934 PTGM_OptTyp 5000;
BA_ "Version" SG_ 934 PTGM_OptTyp "21.07.05";
BA_ "GenSigSendType" SG_ 934 PTGM_ReleaseRlySta 4;
BA_ "UserSigValidity" SG_ 934 PTGM_ReleaseRlySta 0;
BA_REL_ "GenSigTimeoutTime" BU_SG_REL_ APSU SG_ 934 PTGM_ReleaseRlySta 1500;
BA_REL_ "GenSigTimeoutTime" BU_SG_REL_ PFSU SG_ 934 PTGM_ReleaseRlySta 1500;
BA_ "NetworkRequest" SG_ 934 PTGM_ReleaseRlySta 0;
BA_ "NetworkRequestHoldingTime" SG_ 934 PTGM_ReleaseRlySta 5000;
BA_ "Version" SG_ 934 PTGM_ReleaseRlySta "21.07.05";
BA_ "Description" SG_ 934 PTGM_TrnkLkSwSta "-(Old)C_Trunk_Lock_Sw";
BA_ "GenSigSendType" SG_ 934 PTGM_TrnkLkSwSta 4;
BA_ "UserSigValidity" SG_ 934 PTGM_TrnkLkSwSta 0;
BA_ "NetworkRequest" SG_ 934 PTGM_TrnkLkSwSta 0;
BA_ "NetworkRequestHoldingTime" SG_ 934 PTGM_TrnkLkSwSta 5000;
BA_ "Version" SG_ 934 PTGM_TrnkLkSwSta "21.07.05";
BA_ "Description" SG_ 934 PTGM_UsmSetSta "PTGM USM Setting Signal";
BA_ "GenSigSendType" SG_ 934 PTGM_UsmSetSta 4;
BA_ "UserSigValidity" SG_ 934 PTGM_UsmSetSta 3;
BA_ "NetworkRequest" SG_ 934 PTGM_UsmSetSta 0;
BA_ "NetworkRequestHoldingTime" SG_ 934 PTGM_UsmSetSta 5000;
BA_ "Version" SG_ 934 PTGM_UsmSetSta "17.11.00";
BA_ "Description" SG_ 934 PTGM_HeightRValue "PTG Opening Height USM Setting Signal";
BA_ "GenSigSendType" SG_ 934 PTGM_HeightRValue 4;
BA_ "UserSigValidity" SG_ 934 PTGM_HeightRValue 0;
BA_ "NetworkRequest" SG_ 934 PTGM_HeightRValue 0;
BA_ "Version" SG_ 934 PTGM_HeightRValue "21.07.05";
BA_ "Description" SG_ 934 PTGM_OpnClsState "This signal indicates PTGM Open/Close Status";
BA_ "GenSigSendType" SG_ 934 PTGM_OpnClsState 4;
BA_ "UserSigValidity" SG_ 934 PTGM_OpnClsState 0;
BA_ "Version" SG_ 934 PTGM_OpnClsState "21.07.05";
BA_ "Description" SG_ 934 PTGM_CmdWarn "This signal indicates PTGM Warning Status";
BA_ "GenSigSendType" SG_ 934 PTGM_CmdWarn 4;
BA_ "UserSigValidity" SG_ 934 PTGM_CmdWarn 3;
BA_ "Version" SG_ 934 PTGM_CmdWarn "21.07.05";
BA_ "Description" SG_ 934 PTGM_AntiPinchSnsr "This signal indicates Anti-Pinch Sensor Applied Status";
BA_ "GenSigSendType" SG_ 934 PTGM_AntiPinchSnsr 4;
BA_ "UserSigValidity" SG_ 934 PTGM_AntiPinchSnsr 0;
BA_ "Version" SG_ 934 PTGM_AntiPinchSnsr "18.02.03";
BA_ "Description" SG_ 934 PTGM_AutoWashModeSta "PTGM Auto Wash Mode Status Signal";
BA_ "GenSigSendType" SG_ 934 PTGM_AutoWashModeSta 4;
BA_ "TimeoutValue" SG_ 934 PTGM_AutoWashModeSta "0x0";
BA_ "UserSigValidity" SG_ 934 PTGM_AutoWashModeSta 0;
BA_ "Version" SG_ 934 PTGM_AutoWashModeSta "22.01.03";
BA_ "Description" SG_ 934 PTGM_FobSrch_Req "FOB Search Request";
BA_ "GenSigSendType" SG_ 934 PTGM_FobSrch_Req 4;
BA_ "UserSigValidity" SG_ 934 PTGM_FobSrch_Req 0;
BA_ "NetworkRequest" SG_ 934 PTGM_FobSrch_Req 0;
BA_ "NetworkRequestHoldingTime" SG_ 934 PTGM_FobSrch_Req 5000;
BA_ "Version" SG_ 934 PTGM_FobSrch_Req "19.01.11";
BA_ "Description" SG_ 934 PTGM_TlgtAwayCloseRValue "Tailgate Away Close USM On/Off Setting Signal";
BA_ "GenSigSendType" SG_ 934 PTGM_TlgtAwayCloseRValue 4;
BA_ "UserSigValidity" SG_ 934 PTGM_TlgtAwayCloseRValue 0;
BA_ "NetworkRequest" SG_ 934 PTGM_TlgtAwayCloseRValue 0;
BA_ "NetworkRequestHoldingTime" SG_ 934 PTGM_TlgtAwayCloseRValue 5000;
BA_ "Version" SG_ 934 PTGM_TlgtAwayCloseRValue "19.01.10";
BA_ "Description" SG_ 934 PTGM_TrnkTlgtOption "PTGM(Power Tail Gate Module) Option Signal";
BA_ "GenSigSendType" SG_ 934 PTGM_TrnkTlgtOption 4;
BA_ "UserSigValidity" SG_ 934 PTGM_TrnkTlgtOption 0;
BA_ "NetworkRequest" SG_ 934 PTGM_TrnkTlgtOption 0;
BA_ "NetworkRequestHoldingTime" SG_ 934 PTGM_TrnkTlgtOption 5000;
BA_ "Version" SG_ 934 PTGM_TrnkTlgtOption "19.05.00";
BA_ "Description" SG_ 934 PTGM_LatchType "This signal indicates the Tailgate/Trunk Latch Type. (Integrated / Separated)";
BA_ "GenSigSendType" SG_ 934 PTGM_LatchType 4;
BA_ "UserSigValidity" SG_ 934 PTGM_LatchType 0;
BA_ "Version" SG_ 934 PTGM_LatchType "19.07.01";
BA_ "Description" SG_ 934 PTGM_SpeedRValue "PTG Speed USM Setting Signal";
BA_ "GenSigSendType" SG_ 934 PTGM_SpeedRValue 4;
BA_ "UserSigValidity" SG_ 934 PTGM_SpeedRValue 0;
BA_ "NetworkRequest" SG_ 934 PTGM_SpeedRValue 0;
BA_ "Version" SG_ 934 PTGM_SpeedRValue "18.02.03";
BA_ "GenMsgCycleTime" BO_ 1807 0;
BA_ "GenMsgCycleTimeFast" BO_ 1807 0;
BA_ "GenMsgNrOfRepetition" BO_ 1807 0;
BA_ "DiagResponse" BO_ 1807 1;
BA_ "GenMsgILSupport" BO_ 1807 0;
BA_ "TpMessage" BO_ 1807 1;
BA_ "TpTxIndex" BO_ 1807 165;
BA_ "Description" SG_ 1807 RRHVU_GST_Byte0 "TP Index : 165";
BA_ "UsrSigPurpose" SG_ 1807 RRHVU_GST_Byte0 4;
BA_ "UserSigValidity" SG_ 1807 RRHVU_GST_Byte0 0;
BA_REL_ "GenSigTimeoutTime" BU_SG_REL_ CGW_CCU SG_ 1807 RRHVU_GST_Byte0 0;
BA_ "NetworkRequest" SG_ 1807 RRHVU_GST_Byte0 0;
BA_ "NetworkRequestHoldingTime" SG_ 1807 RRHVU_GST_Byte0 5000;
BA_ "Version" SG_ 1807 RRHVU_GST_Byte0 "21.02.04";
BA_ "Description" SG_ 1807 RRHVU_GST_Byte2 "TP Index : 165";
BA_ "UsrSigPurpose" SG_ 1807 RRHVU_GST_Byte2 4;
BA_ "UserSigValidity" SG_ 1807 RRHVU_GST_Byte2 0;
BA_REL_ "GenSigTimeoutTime" BU_SG_REL_ CGW_CCU SG_ 1807 RRHVU_GST_Byte2 0;
BA_ "NetworkRequest" SG_ 1807 RRHVU_GST_Byte2 0;
BA_ "NetworkRequestHoldingTime" SG_ 1807 RRHVU_GST_Byte2 5000;
BA_ "Version" SG_ 1807 RRHVU_GST_Byte2 "21.02.04";
BA_ "Description" SG_ 1807 RRHVU_GST_Byte3 "TP Index : 165";
BA_ "UsrSigPurpose" SG_ 1807 RRHVU_GST_Byte3 4;
BA_ "UserSigValidity" SG_ 1807 RRHVU_GST_Byte3 0;
BA_REL_ "GenSigTimeoutTime" BU_SG_REL_ CGW_CCU SG_ 1807 RRHVU_GST_Byte3 0;
BA_ "NetworkRequest" SG_ 1807 RRHVU_GST_Byte3 0;
BA_ "NetworkRequestHoldingTime" SG_ 1807 RRHVU_GST_Byte3 5000;
BA_ "Version" SG_ 1807 RRHVU_GST_Byte3 "21.02.04";
BA_ "Description" SG_ 1807 RRHVU_GST_Byte4 "TP Index : 165";
BA_ "UsrSigPurpose" SG_ 1807 RRHVU_GST_Byte4 4;
BA_ "UserSigValidity" SG_ 1807 RRHVU_GST_Byte4 0;
BA_REL_ "GenSigTimeoutTime" BU_SG_REL_ CGW_CCU SG_ 1807 RRHVU_GST_Byte4 0;
BA_ "NetworkRequest" SG_ 1807 RRHVU_GST_Byte4 0;
BA_ "NetworkRequestHoldingTime" SG_ 1807 RRHVU_GST_Byte4 5000;
BA_ "Version" SG_ 1807 RRHVU_GST_Byte4 "21.02.04";
BA_ "Description" SG_ 1807 RRHVU_GST_Byte5 "TP Index : 165";
BA_ "UsrSigPurpose" SG_ 1807 RRHVU_GST_Byte5 4;
BA_ "UserSigValidity" SG_ 1807 RRHVU_GST_Byte5 0;
BA_REL_ "GenSigTimeoutTime" BU_SG_REL_ CGW_CCU SG_ 1807 RRHVU_GST_Byte5 0;
BA_ "NetworkRequest" SG_ 1807 RRHVU_GST_Byte5 0;
BA_ "NetworkRequestHoldingTime" SG_ 1807 RRHVU_GST_Byte5 5000;
BA_ "Version" SG_ 1807 RRHVU_GST_Byte5 "21.02.04";
BA_ "Description" SG_ 1807 RRHVU_GST_Byte6 "TP Index : 165";
BA_ "UsrSigPurpose" SG_ 1807 RRHVU_GST_Byte6 4;
BA_ "UserSigValidity" SG_ 1807 RRHVU_GST_Byte6 0;
BA_REL_ "GenSigTimeoutTime" BU_SG_REL_ CGW_CCU SG_ 1807 RRHVU_GST_Byte6 0;
BA_ "NetworkRequest" SG_ 1807 RRHVU_GST_Byte6 0;
BA_ "NetworkRequestHoldingTime" SG_ 1807 RRHVU_GST_Byte6 5000;
BA_ "Version" SG_ 1807 RRHVU_GST_Byte6 "21.02.04";
BA_ "Description" SG_ 1807 RRHVU_GST_Byte7 "TP Index : 165";
BA_ "UsrSigPurpose" SG_ 1807 RRHVU_GST_Byte7 4;
BA_ "UserSigValidity" SG_ 1807 RRHVU_GST_Byte7 0;
BA_REL_ "GenSigTimeoutTime" BU_SG_REL_ CGW_CCU SG_ 1807 RRHVU_GST_Byte7 0;
BA_ "NetworkRequest" SG_ 1807 RRHVU_GST_Byte7 0;
BA_ "NetworkRequestHoldingTime" SG_ 1807 RRHVU_GST_Byte7 5000;
BA_ "Version" SG_ 1807 RRHVU_GST_Byte7 "21.02.04";
BA_ "Description" SG_ 1807 RRHVU_GST_Byte1 "TP Index : 165";
BA_ "UsrSigPurpose" SG_ 1807 RRHVU_GST_Byte1 4;
BA_ "UserSigValidity" SG_ 1807 RRHVU_GST_Byte1 0;
BA_REL_ "GenSigTimeoutTime" BU_SG_REL_ CGW_CCU SG_ 1807 RRHVU_GST_Byte1 0;
BA_ "NetworkRequest" SG_ 1807 RRHVU_GST_Byte1 0;
BA_ "NetworkRequestHoldingTime" SG_ 1807 RRHVU_GST_Byte1 5000;
BA_ "Version" SG_ 1807 RRHVU_GST_Byte1 "21.02.04";
BA_ "GenMsgSendType" BO_ 862 0;
BA_ "Description" SG_ 862 SBCM_RL_Crc1Val "The data area for CRC calculation is based on the data length (DLC) of the message DB.

The CRC shall be calculated over the entire data block (excluding the CRC bytes) including the user data, alive counter and Data ID 

 

- CRC Polynomial (0x1D) , Initial Value : 0x00, XOR value : 0xFF, Data ID Mode : Both, Data ID : Message ID + 0xF800 

- The initial value is for CRC calculation and the message should be sent with the calculated result value. 

The mathematical expression to 8 bit CRC polynomial is given here. G(x) = x8 + x4 + x3 + x2 + 1";
BA_ "GenSigSendType" SG_ 862 SBCM_RL_Crc1Val 4;
BA_ "GenSigStartValue" SG_ 862 SBCM_RL_Crc1Val 255;
BA_ "UserSigValidity" SG_ 862 SBCM_RL_Crc1Val 0;
BA_ "Version" SG_ 862 SBCM_RL_Crc1Val "19.07.06";
BA_ "Description" SG_ 862 RL_CrashUnlockCmd "RearLefrCrashUnlockCommand";
BA_ "GenSigSendType" SG_ 862 RL_CrashUnlockCmd 4;
BA_ "UserSigValidity" SG_ 862 RL_CrashUnlockCmd 0;
BA_REL_ "GenSigTimeoutTime" BU_SG_REL_ BLTN_CAM SG_ 862 RL_CrashUnlockCmd 1500;
BA_ "NetworkRequest" SG_ 862 RL_CrashUnlockCmd 0;
BA_ "Version" SG_ 862 RL_CrashUnlockCmd "20.09.00";
BA_ "Description" SG_ 862 SBCM_RL_AlvCnt1Val "For the first transmission request for a data element the counter shall be initialized with 0 and shall be incremented by 1

for every subsequent send request. When the counter reaches the maximum value(0xE), then it shall restart with 0 for the next send request";
BA_ "GenSigSendType" SG_ 862 SBCM_RL_AlvCnt1Val 4;
BA_ "UserSigValidity" SG_ 862 SBCM_RL_AlvCnt1Val 0;
BA_ "Version" SG_ 862 SBCM_RL_AlvCnt1Val "19.07.06";
BA_ "Description" SG_ 862 Warn_RrLftDrSwSta_SBCM "Warning Rear Left Door Switch Status";
BA_ "GenSigSendType" SG_ 862 Warn_RrLftDrSwSta_SBCM 4;
BA_ "UserSigValidity" SG_ 862 Warn_RrLftDrSwSta_SBCM 0;
BA_REL_ "GenSigTimeoutTime" BU_SG_REL_ WPC SG_ 862 Warn_RrLftDrSwSta_SBCM 1500;
BA_REL_ "GenSigTimeoutTime" BU_SG_REL_ RWPC SG_ 862 Warn_RrLftDrSwSta_SBCM 1500;
BA_REL_ "GenSigTimeoutTime" BU_SG_REL_ APSU SG_ 862 Warn_RrLftDrSwSta_SBCM 1500;
BA_REL_ "GenSigTimeoutTime" BU_SG_REL_ ATS SG_ 862 Warn_RrLftDrSwSta_SBCM 1500;
BA_REL_ "GenSigTimeoutTime" BU_SG_REL_ BLTN_CAM SG_ 862 Warn_RrLftDrSwSta_SBCM 1500;
BA_REL_ "GenSigTimeoutTime" BU_SG_REL_ WPC2 SG_ 862 Warn_RrLftDrSwSta_SBCM 1500;
BA_ "NetworkRequest" SG_ 862 Warn_RrLftDrSwSta_SBCM 0;
BA_ "Version" SG_ 862 Warn_RrLftDrSwSta_SBCM "21.07.07";
BA_ "Description" SG_ 862 DoorLock_RrLftDrUnLkSta_SBCM "Rear Left Door Unlock Status";
BA_ "GenSigSendType" SG_ 862 DoorLock_RrLftDrUnLkSta_SBCM 4;
BA_ "UserSigValidity" SG_ 862 DoorLock_RrLftDrUnLkSta_SBCM 0;
BA_REL_ "GenSigTimeoutTime" BU_SG_REL_ ATS SG_ 862 DoorLock_RrLftDrUnLkSta_SBCM 1500;
BA_ "NetworkRequest" SG_ 862 DoorLock_RrLftDrUnLkSta_SBCM 0;
BA_ "Version" SG_ 862 DoorLock_RrLftDrUnLkSta_SBCM "19.07.06";
BA_ "Description" SG_ 862 RL_SEAActivated "Rear Left SEA Activated";
BA_ "GenSigSendType" SG_ 862 RL_SEAActivated 4;
BA_ "UserSigValidity" SG_ 862 RL_SEAActivated 0;
BA_ "NetworkRequest" SG_ 862 RL_SEAActivated 0;
BA_ "Version" SG_ 862 RL_SEAActivated "19.07.06";
BA_ "Description" SG_ 862 RL_SEAWarn "RearLeftSEAWarning";
BA_ "GenSigSendType" SG_ 862 RL_SEAWarn 4;
BA_ "UserSigValidity" SG_ 862 RL_SEAWarn 0;
BA_ "NetworkRequest" SG_ 862 RL_SEAWarn 0;
BA_ "Version" SG_ 862 RL_SEAWarn "19.07.06";
BA_ "GenSigSendType" SG_ 862 RL_SEWWarn 4;
BA_ "UserSigValidity" SG_ 862 RL_SEWWarn 0;
BA_ "NetworkRequest" SG_ 862 RL_SEWWarn 0;
BA_ "Version" SG_ 862 RL_SEWWarn "20.09.00";
BA_ "GenSigSendType" SG_ 862 RL_ReleaseWarn 4;
BA_ "UserSigValidity" SG_ 862 RL_ReleaseWarn 0;
BA_ "NetworkRequest" SG_ 862 RL_ReleaseWarn 0;
BA_ "NetworkRequestHoldingTime" SG_ 862 RL_ReleaseWarn 5000;
BA_ "Version" SG_ 862 RL_ReleaseWarn "20.09.00";
BA_ "GenSigSendType" SG_ 862 RL_SWFailAlarm 4;
BA_ "UserSigValidity" SG_ 862 RL_SWFailAlarm 0;
BA_ "NetworkRequest" SG_ 862 RL_SWFailAlarm 0;
BA_ "NetworkRequestHoldingTime" SG_ 862 RL_SWFailAlarm 5000;
BA_ "Version" SG_ 862 RL_SWFailAlarm "20.09.00";
BA_ "GenSigSendType" SG_ 862 RL_ChildLock_ActnFlSta 4;
BA_ "UserSigValidity" SG_ 862 RL_ChildLock_ActnFlSta 0;
BA_ "NetworkRequest" SG_ 862 RL_ChildLock_ActnFlSta 0;
BA_ "NetworkRequestHoldingTime" SG_ 862 RL_ChildLock_ActnFlSta 5000;
BA_ "Version" SG_ 862 RL_ChildLock_ActnFlSta "19.11.05";
BA_ "GenSigSendType" SG_ 862 RL_MRActivationAlarm 4;
BA_ "UserSigValidity" SG_ 862 RL_MRActivationAlarm 0;
BA_ "NetworkRequest" SG_ 862 RL_MRActivationAlarm 0;
BA_ "NetworkRequestHoldingTime" SG_ 862 RL_MRActivationAlarm 5000;
BA_ "Version" SG_ 862 RL_MRActivationAlarm "19.11.05";
BA_ "GenSigSendType" SG_ 862 RL_ChildLock_Status 4;
BA_ "UserSigValidity" SG_ 862 RL_ChildLock_Status 0;
BA_ "NetworkRequest" SG_ 862 RL_ChildLock_Status 0;
BA_ "NetworkRequestHoldingTime" SG_ 862 RL_ChildLock_Status 5000;
BA_ "Version" SG_ 862 RL_ChildLock_Status "21.07.07";
BA_ "GenSigSendType" SG_ 862 USM_RLGhostDoorSta 4;
BA_ "UserSigValidity" SG_ 862 USM_RLGhostDoorSta 0;
BA_ "NetworkRequest" SG_ 862 USM_RLGhostDoorSta 0;
BA_ "NetworkRequestHoldingTime" SG_ 862 USM_RLGhostDoorSta 5000;
BA_ "Version" SG_ 862 USM_RLGhostDoorSta "21.03.11";
BA_ "GenSigSendType" SG_ 862 DoorLock_PDSLkSwSta_RL 4;
BA_ "UserSigValidity" SG_ 862 DoorLock_PDSLkSwSta_RL 0;
BA_ "NetworkRequest" SG_ 862 DoorLock_PDSLkSwSta_RL 0;
BA_ "Version" SG_ 862 DoorLock_PDSLkSwSta_RL "19.12.00";
BA_ "GenSigSendType" SG_ 862 PDS_TypeOption_RL 4;
BA_ "UserSigValidity" SG_ 862 PDS_TypeOption_RL 0;
BA_ "NetworkRequest" SG_ 862 PDS_TypeOption_RL 0;
BA_ "Version" SG_ 862 PDS_TypeOption_RL "19.12.00";
BA_ "GenSigSendType" SG_ 862 RLDoorPushAlarm 4;
BA_ "UserSigValidity" SG_ 862 RLDoorPushAlarm 0;
BA_ "NetworkRequest" SG_ 862 RLDoorPushAlarm 0;
BA_ "NetworkRequestHoldingTime" SG_ 862 RLDoorPushAlarm 5000;
BA_ "Version" SG_ 862 RLDoorPushAlarm "20.09.00";
BA_ "GenMsgSendType" BO_ 929 0;
BA_ "Description" SG_ 929 SCM_Opt "SCM option";
BA_ "GenSigSendType" SG_ 929 SCM_Opt 4;
BA_ "UserSigValidity" SG_ 929 SCM_Opt 0;
BA_REL_ "GenSigTimeoutTime" BU_SG_REL_ DPSU SG_ 929 SCM_Opt 1500;
BA_REL_ "GenSigTimeoutTime" BU_SG_REL_ CGW_CCU SG_ 929 SCM_Opt 1500;
BA_ "NetworkRequest" SG_ 929 SCM_Opt 0;
BA_ "NetworkRequestHoldingTime" SG_ 929 SCM_Opt 5000;
BA_ "Version" SG_ 929 SCM_Opt "21.02.00";
BA_ "Description" SG_ 929 Tilt_VirtualLimExist "Tilt virtual limit existence";
BA_ "GenSigSendType" SG_ 929 Tilt_VirtualLimExist 4;
BA_ "UserSigValidity" SG_ 929 Tilt_VirtualLimExist 0;
BA_REL_ "GenSigTimeoutTime" BU_SG_REL_ CGW_CCU SG_ 929 Tilt_VirtualLimExist 1500;
BA_ "NetworkRequest" SG_ 929 Tilt_VirtualLimExist 0;
BA_ "NetworkRequestHoldingTime" SG_ 929 Tilt_VirtualLimExist 5000;
BA_ "Version" SG_ 929 Tilt_VirtualLimExist "21.02.00";
BA_ "Description" SG_ 929 Tele_SnsrErr "Telescopic operating error by Hall Sensor";
BA_ "GenSigSendType" SG_ 929 Tele_SnsrErr 4;
BA_ "TimeoutValue" SG_ 929 Tele_SnsrErr "0x0";
BA_ "UserSigValidity" SG_ 929 Tele_SnsrErr 0;
BA_REL_ "GenSigTimeoutTime" BU_SG_REL_ CGW_CCU SG_ 929 Tele_SnsrErr 1500;
BA_ "NetworkRequest" SG_ 929 Tele_SnsrErr 0;
BA_ "NetworkRequestHoldingTime" SG_ 929 Tele_SnsrErr 5000;
BA_ "Version" SG_ 929 Tele_SnsrErr "22.02.02";
BA_ "Description" SG_ 929 Tele_VirtualLim "Reached to Telescopic Virtual Limit";
BA_ "GenSigSendType" SG_ 929 Tele_VirtualLim 4;
BA_ "TimeoutValue" SG_ 929 Tele_VirtualLim "0x0";
BA_ "UserSigValidity" SG_ 929 Tele_VirtualLim 0;
BA_REL_ "GenSigTimeoutTime" BU_SG_REL_ CGW_CCU SG_ 929 Tele_VirtualLim 1500;
BA_ "NetworkRequest" SG_ 929 Tele_VirtualLim 0;
BA_ "NetworkRequestHoldingTime" SG_ 929 Tele_VirtualLim 5000;
BA_ "Version" SG_ 929 Tele_VirtualLim "21.02.00";
BA_ "Description" SG_ 929 Tele_VirtualLimExist "Telescopic virtual limit existence";
BA_ "GenSigSendType" SG_ 929 Tele_VirtualLimExist 4;
BA_ "UserSigValidity" SG_ 929 Tele_VirtualLimExist 0;
BA_REL_ "GenSigTimeoutTime" BU_SG_REL_ CGW_CCU SG_ 929 Tele_VirtualLimExist 1500;
BA_ "NetworkRequest" SG_ 929 Tele_VirtualLimExist 0;
BA_ "NetworkRequestHoldingTime" SG_ 929 Tele_VirtualLimExist 5000;
BA_ "Version" SG_ 929 Tele_VirtualLimExist "21.02.00";
BA_ "Description" SG_ 929 TiltTele_Profile1MemoryExist "Profile1 memory existence";
BA_ "GenSigSendType" SG_ 929 TiltTele_Profile1MemoryExist 4;
BA_ "UserSigValidity" SG_ 929 TiltTele_Profile1MemoryExist 0;
BA_REL_ "GenSigTimeoutTime" BU_SG_REL_ CGW_CCU SG_ 929 TiltTele_Profile1MemoryExist 1500;
BA_ "NetworkRequest" SG_ 929 TiltTele_Profile1MemoryExist 0;
BA_ "NetworkRequestHoldingTime" SG_ 929 TiltTele_Profile1MemoryExist 5000;
BA_ "Version" SG_ 929 TiltTele_Profile1MemoryExist "21.02.00";
BA_ "Description" SG_ 929 Tilt_MnlSwSta "Tilt manual switch state";
BA_ "GenSigSendType" SG_ 929 Tilt_MnlSwSta 4;
BA_ "TimeoutValue" SG_ 929 Tilt_MnlSwSta "0x0";
BA_ "UserSigValidity" SG_ 929 Tilt_MnlSwSta 0;
BA_REL_ "GenSigTimeoutTime" BU_SG_REL_ CGW_CCU SG_ 929 Tilt_MnlSwSta 1500;
BA_ "NetworkRequest" SG_ 929 Tilt_MnlSwSta 0;
BA_ "NetworkRequestHoldingTime" SG_ 929 Tilt_MnlSwSta 5000;
BA_ "Version" SG_ 929 Tilt_MnlSwSta "21.02.00";
BA_ "Description" SG_ 929 TiltTele_Profile2MemoryExist "Profile2 memory existence";
BA_ "GenSigSendType" SG_ 929 TiltTele_Profile2MemoryExist 4;
BA_ "UserSigValidity" SG_ 929 TiltTele_Profile2MemoryExist 0;
BA_REL_ "GenSigTimeoutTime" BU_SG_REL_ CGW_CCU SG_ 929 TiltTele_Profile2MemoryExist 1500;
BA_ "NetworkRequest" SG_ 929 TiltTele_Profile2MemoryExist 0;
BA_ "NetworkRequestHoldingTime" SG_ 929 TiltTele_Profile2MemoryExist 5000;
BA_ "Version" SG_ 929 TiltTele_Profile2MemoryExist "21.02.00";
BA_ "Description" SG_ 929 TiltTele_GuestMemoryExist "Guest memory existence";
BA_ "GenSigSendType" SG_ 929 TiltTele_GuestMemoryExist 4;
BA_ "UserSigValidity" SG_ 929 TiltTele_GuestMemoryExist 0;
BA_REL_ "GenSigTimeoutTime" BU_SG_REL_ CGW_CCU SG_ 929 TiltTele_GuestMemoryExist 1500;
BA_ "NetworkRequest" SG_ 929 TiltTele_GuestMemoryExist 0;
BA_ "NetworkRequestHoldingTime" SG_ 929 TiltTele_GuestMemoryExist 5000;
BA_ "Version" SG_ 929 TiltTele_GuestMemoryExist "21.02.00";
BA_ "Description" SG_ 929 TiltTele_IMS1MemoryExist "IMS1 memory existence";
BA_ "GenSigSendType" SG_ 929 TiltTele_IMS1MemoryExist 4;
BA_ "UserSigValidity" SG_ 929 TiltTele_IMS1MemoryExist 0;
BA_REL_ "GenSigTimeoutTime" BU_SG_REL_ CGW_CCU SG_ 929 TiltTele_IMS1MemoryExist 1500;
BA_ "NetworkRequest" SG_ 929 TiltTele_IMS1MemoryExist 0;
BA_ "NetworkRequestHoldingTime" SG_ 929 TiltTele_IMS1MemoryExist 5000;
BA_ "Version" SG_ 929 TiltTele_IMS1MemoryExist "21.02.00";
BA_ "Description" SG_ 929 TiltTele_IMS2MemoryExist "IMS2 memory existence";
BA_ "GenSigSendType" SG_ 929 TiltTele_IMS2MemoryExist 4;
BA_ "UserSigValidity" SG_ 929 TiltTele_IMS2MemoryExist 0;
BA_REL_ "GenSigTimeoutTime" BU_SG_REL_ CGW_CCU SG_ 929 TiltTele_IMS2MemoryExist 1500;
BA_ "NetworkRequest" SG_ 929 TiltTele_IMS2MemoryExist 0;
BA_ "NetworkRequestHoldingTime" SG_ 929 TiltTele_IMS2MemoryExist 5000;
BA_ "Version" SG_ 929 TiltTele_IMS2MemoryExist "21.02.00";
BA_ "Description" SG_ 929 TiltTele_IMS3MemoryExist "IMS3 memory existence";
BA_ "GenSigSendType" SG_ 929 TiltTele_IMS3MemoryExist 4;
BA_ "UserSigValidity" SG_ 929 TiltTele_IMS3MemoryExist 0;
BA_REL_ "GenSigTimeoutTime" BU_SG_REL_ CGW_CCU SG_ 929 TiltTele_IMS3MemoryExist 1500;
BA_ "NetworkRequest" SG_ 929 TiltTele_IMS3MemoryExist 0;
BA_ "NetworkRequestHoldingTime" SG_ 929 TiltTele_IMS3MemoryExist 5000;
BA_ "Version" SG_ 929 TiltTele_IMS3MemoryExist "21.02.00";
BA_ "Description" SG_ 929 TiltTele_ReturnMemoryExist "Auto Return memory existence";
BA_ "GenSigSendType" SG_ 929 TiltTele_ReturnMemoryExist 4;
BA_ "UserSigValidity" SG_ 929 TiltTele_ReturnMemoryExist 0;
BA_REL_ "GenSigTimeoutTime" BU_SG_REL_ CGW_CCU SG_ 929 TiltTele_ReturnMemoryExist 1500;
BA_ "NetworkRequest" SG_ 929 TiltTele_ReturnMemoryExist 0;
BA_ "NetworkRequestHoldingTime" SG_ 929 TiltTele_ReturnMemoryExist 5000;
BA_ "Version" SG_ 929 TiltTele_ReturnMemoryExist "21.02.00";
BA_ "Description" SG_ 929 Tilt_OpSta "Tilt operating state (Motor output command, not real motor output)";
BA_ "GenSigSendType" SG_ 929 Tilt_OpSta 4;
BA_ "TimeoutValue" SG_ 929 Tilt_OpSta "0x0";
BA_ "UserSigValidity" SG_ 929 Tilt_OpSta 0;
BA_REL_ "GenSigTimeoutTime" BU_SG_REL_ CGW_CCU SG_ 929 Tilt_OpSta 1500;
BA_ "NetworkRequest" SG_ 929 Tilt_OpSta 0;
BA_ "NetworkRequestHoldingTime" SG_ 929 Tilt_OpSta 5000;
BA_ "Version" SG_ 929 Tilt_OpSta "22.02.02";
BA_ "Description" SG_ 929 Tele_OpSta "Telescopic operating state (Motor output command, not real motor output)";
BA_ "GenSigSendType" SG_ 929 Tele_OpSta 4;
BA_ "TimeoutValue" SG_ 929 Tele_OpSta "0x0";
BA_ "UserSigValidity" SG_ 929 Tele_OpSta 0;
BA_REL_ "GenSigTimeoutTime" BU_SG_REL_ CGW_CCU SG_ 929 Tele_OpSta 1500;
BA_ "NetworkRequest" SG_ 929 Tele_OpSta 0;
BA_ "NetworkRequestHoldingTime" SG_ 929 Tele_OpSta 5000;
BA_ "Version" SG_ 929 Tele_OpSta "22.02.02";
BA_ "Description" SG_ 929 Tele_MnlSwSta "Telescopic manual switch state";
BA_ "GenSigSendType" SG_ 929 Tele_MnlSwSta 4;
BA_ "TimeoutValue" SG_ 929 Tele_MnlSwSta "0x0";
BA_ "UserSigValidity" SG_ 929 Tele_MnlSwSta 0;
BA_REL_ "GenSigTimeoutTime" BU_SG_REL_ CGW_CCU SG_ 929 Tele_MnlSwSta 1500;
BA_ "NetworkRequest" SG_ 929 Tele_MnlSwSta 0;
BA_ "NetworkRequestHoldingTime" SG_ 929 Tele_MnlSwSta 5000;
BA_ "Version" SG_ 929 Tele_MnlSwSta "21.02.02";
BA_ "Description" SG_ 929 Tilt_SnsrErr "Tilt operating error by Hall Sensor";
BA_ "GenSigSendType" SG_ 929 Tilt_SnsrErr 4;
BA_ "TimeoutValue" SG_ 929 Tilt_SnsrErr "0x0";
BA_ "UserSigValidity" SG_ 929 Tilt_SnsrErr 0;
BA_REL_ "GenSigTimeoutTime" BU_SG_REL_ CGW_CCU SG_ 929 Tilt_SnsrErr 1500;
BA_ "NetworkRequest" SG_ 929 Tilt_SnsrErr 0;
BA_ "NetworkRequestHoldingTime" SG_ 929 Tilt_SnsrErr 5000;
BA_ "Version" SG_ 929 Tilt_SnsrErr "22.02.02";
BA_ "Description" SG_ 929 Tilt_VirtualLim "Reached to Tilt virtual limit";
BA_ "GenSigSendType" SG_ 929 Tilt_VirtualLim 4;
BA_ "TimeoutValue" SG_ 929 Tilt_VirtualLim "0x0";
BA_ "UserSigValidity" SG_ 929 Tilt_VirtualLim 0;
BA_REL_ "GenSigTimeoutTime" BU_SG_REL_ CGW_CCU SG_ 929 Tilt_VirtualLim 1500;
BA_ "NetworkRequest" SG_ 929 Tilt_VirtualLim 0;
BA_ "NetworkRequestHoldingTime" SG_ 929 Tilt_VirtualLim 5000;
BA_ "Version" SG_ 929 Tilt_VirtualLim "21.02.00";
VAL_ 2281835009 ACU_SysWrngLmpDis 0 "Warning Lamp off" 1 "Warning Lamp on" 2 "Warning Lamp flash" 3 "Reserved" 4 "Reserved" 5 "Reserved" 6 "Not used" 7 "Error Indicator" ;
VAL_ 2281835009 ACU_TlltlLmpDis 0 "ON Lamp off OFF Lamp off" 1 "ON Lamp off  OFF Lamp on" 2 "ON Lamp on OFF Lamp off" 3 "ON Lamp on OFF Lamp on" 4 "Reserved" 5 "Reserved" 6 "Reserved" 7 "Error Indicator" ;
VAL_ 2281835009 ACU_OdsIDReq 0 "Request to send ODS Identifier" 1 "Acknowledgement for the Correct ODS Identifier Received" 2 "Not used" 3 "Error Indicator" ;
VAL_ 2281835009 SeatBelt_PassBcklFltSta 0 "No Fault" 1 "Fault condition exists" 2 "Not used" 3 "Error Indicator" ;
VAL_ 2281835009 SeatBelt_DrvrBcklFltSta 0 "No Fault" 1 "Fault condition exists" 2 "Not used" 3 "Error Indicator" ;
VAL_ 2281835009 SeatBelt_PassBcklSta 0 "Passenger Seat Belt Not Latched" 1 "Passenger Seat Belt Latched" 2 "Not used" 3 "Error Indicator" ;
VAL_ 2281835009 SeatBelt_DrvrBcklSta 0 "Driver Seat Belt Not Latched" 1 "Driver Seat Belt Latched" 2 "Not used" 3 "Error Indicator" ;
VAL_ 2281835010 ACU_ActvFltSta 0 "Fault status is active" 1 "Fault status is historic" 2 "Fault does not exist" 3 "Reserved" 4 "Reserved" 5 "Reserved" 6 "Not used" 7 "Error Indicator" ;
VAL_ 2281835010 ACU_SdArbgExtTyp 0 "Side(or Side/Curtain) Airbag doesn't exist." 1 "Side(or Side/Curtain) Airbag exists." 2 "ACU EOL Programming Mode" 3 "Reserved" 4 "Reserved" 5 "Reserved" 6 "Not used" 7 "Error Indicator" ;
VAL_ 2281835010 ACU_PassArbg_SW_Sta 0 "NOT_APPLIED" 1 "PAB_OFF" 2 "PAB_ON" 3 "Invalid" ;
VAL_ 2281835010 ACU_HDPSpprtSWVer 0 "Not Support(init)" 1 "SW Version" 2 "SW Version" 3 "SW Version" 4 "SW Version" 5 "SW Version" 6 "SW Version" 7 "SW Version" 8 "SW Version" 9 "SW Version" 10 "SW Version" 11 "SW Version" 12 "SW Version" 13 "SW Version" 14 "SW Version" 15 "SW Version" 16 "SW Version" 17 "SW Version" 18 "SW Version" 19 "SW Version" 20 "SW Version" 21 "SW Version" ;
VAL_ 2281835010 ACU_EmerModSta 0 "ACU is NOT Emergency mode" 1 "ACU is Emergency mode" ;
VAL_ 2281835010 ACU_EvtTrigSta 0 "EDR Not triggered." 1 "EDR triggered." ;
VAL_ 2239851010 RSPA_Var 0 "init" 1 "RSPA (ENTRY)" 2 "RSPA" 3 "RSPA II" 4 "Reserved" 5 "Reserved" 6 "Reserved" 7 "Reserved" 8 "Reserved" 9 "Reserved" 10 "Reserved" 11 "Reserved" 12 "Reserved" 13 "Reserved" 14 "Reserved" 15 "Invalid" ;
VAL_ 2239851010 RSPA_Sta 0 "RSPA not recognized" 1 "Init" 2 "New Start" 3 "Ready OK" 4 "Assist Req" 5 "Assist OK" 6 "Assist Fail" 7 "Abort" 8 "Ready Fail" ;
VAL_ 2239851010 RSPA_Actv 0 "RSPA Off" 1 "RSPA On" 2 "Reserved" 3 "Reserved" ;
VAL_ 2239851010 RSPA_EvasiveStrBtnDis 0 "Initial" 1 "Do not display evasive steering on/off button" 2 "Display evasive steering on/off button" 3 "Invalid" ;
VAL_ 2239851012 RSPA_HdLmpReq 0 "Initial (Inactive)" 1 "HeadLamp On" 2 "Not Used" 3 "Error Indicator" ;
VAL_ 2239851012 RSPA_OSMirFoldReq 0 "Off" 1 "OS Mirror Fold" 2 "OS Mirror Unfold" 3 "Invalid" ;
VAL_ 951 BLTN_CAM_RecSet_OWD 0 "Default" 1 "Off" 2 "On" 3 "Invalid" ;
VAL_ 951 BLTN_CAM_Set_Tim_Stm 0 "Default" 1 "Off" 2 "On" 3 "Invalid" ;
VAL_ 951 BLTN_CAM_Set_Spd_Stm 0 "Default" 1 "Off" 2 "On" 3 "Invalid" ;
VAL_ 951 BLTN_CAM_Set_Locatn_Stm 0 "Default" 1 "Off" 2 "On" 3 "Invalid" ;
VAL_ 951 BLTN_CAM_Set_TrnSig_Stm 0 "Default" 1 "Off" 2 "On" 3 "Invalid" ;
VAL_ 951 BLTN_CAM_Set_AclBrk_Stm 0 "Default" 1 "Off" 2 "On" 3 "Invalid" ;
VAL_ 951 BLTN_CAM_RecSet_DEV 0 "Default" 1 "Off" 2 "On" 3 "Invalid" ;
VAL_ 951 BLTN_CAM_Set_GearPos_Stm 0 "Default" 1 "Off" 2 "On" 3 "Invalid" ;
VAL_ 951 BLTN_CAM_Set_EVSen_Stm 0 "Default" 1 "Off" 2 "On" 3 "Invalid" ;
VAL_ 951 BLTN_CAM_Set_StrAngl_Stm 0 "Default" 1 "Off" 2 "On" 3 "Invalid" ;
VAL_ 951 BLTN_CAM_Set_PrkTime 0 "Default" 1 "0x01~0xFB: 1~ 251 hr" 251 "0x01~0xFB: 1~ 251 hr" 252 "RESERVED" 253 "RESERVED" 254 "Not Supported" 255 "Invalid" ;
VAL_ 951 BLTN_CAM_Set_EV_BfrTime 0 "10~20 sec" 1 "10~20 sec" 2 "10~20 sec" 3 "10~20 sec" 4 "10~20 sec" 5 "10~20 sec" 6 "10~20 sec" 7 "10~20 sec" 8 "10~20 sec" 9 "10~20 sec" 10 "10~20 sec" 11 "Reserved" 12 "Reserved" 13 "Reserved" 14 "Reserved" 15 "Reserved" 16 "Reserved" 17 "Reserved" 18 "Reserved" 19 "Reserved" 20 "Reserved" 21 "Reserved" 22 "Reserved" 23 "Reserved" 24 "Reserved" 25 "Reserved" 26 "Reserved" 27 "Reserved" 28 "Reserved" 29 "Reserved" 30 "Reserved" 31 "Invalid" ;
VAL_ 951 BLTN_CAM_RecSet_OWP 0 "Default" 1 "Off" 2 "On" 3 "Invalid" ;
VAL_ 951 BLTN_CAM_Set_EV_AftTime 0 "10~20 sec" 1 "10~20 sec" 2 "10~20 sec" 3 "10~20 sec" 4 "10~20 sec" 5 "10~20 sec" 6 "10~20 sec" 7 "10~20 sec" 8 "10~20 sec" 9 "10~20 sec" 10 "10~20 sec" 11 "Reserved" 12 "Reserved" 13 "Reserved" 14 "Reserved" 15 "Reserved" 16 "Reserved" 17 "Reserved" 18 "Reserved" 19 "Reserved" 20 "Reserved" 21 "Reserved" 22 "Reserved" 23 "Reserved" 24 "Reserved" 25 "Reserved" 26 "Reserved" 27 "Reserved" 28 "Reserved" 29 "Reserved" 30 "Reserved" 31 "Invalid" ;
VAL_ 951 BLTN_CAM_Set_Drv_TML_Int 0 "Default" 1 "1~ 10 sec" 2 "1~ 10 sec" 3 "1~ 10 sec" 4 "1~ 10 sec" 5 "1~ 10 sec" 6 "1~ 10 sec" 7 "1~ 10 sec" 8 "1~ 10 sec" 9 "1~ 10 sec" 10 "1~ 10 sec" 11 "Reserved" 12 "Reserved" 13 "Reserved" 14 "Reserved" 15 "Invalid" ;
VAL_ 951 BLTN_CAM_SenSet_DEV 0 "Default" 1 "Level 1" 2 "Level 2" 3 "Level 3" 4 "Level 4" 5 "Level 5" 6 "Reserved" 7 "Reserved" 8 "Reserved" 9 "Reserved" 10 "Reserved" 11 "Reserved" 12 "Reserved" 13 "Reserved" 14 "Reserved" 15 "Invalid" ;
VAL_ 951 BLTN_CAM_SenSet_PEV 0 "Default" 1 "Level 1" 2 "Level 2" 3 "Level 3" 4 "Level 4" 5 "Level 5" 6 "Reserved" 7 "Reserved" 8 "Reserved" 9 "Reserved" 10 "Reserved" 11 "Reserved" 12 "Reserved" 13 "Reserved" 14 "Reserved" 15 "Invalid" ;
VAL_ 951 BLTN_CAM_RecSet_PEV 0 "Default" 1 "Off" 2 "On" 3 "Invalid" ;
VAL_ 951 BLTN_CAM_AudRec_Set 0 "Default" 1 "Off" 2 "On" 3 "Invalid" ;
VAL_ 952 BLTN_CAM_Set_FR_Ver_Pos 0 "Mid" 1 "Upper Level (1 ~ 10)" 2 "Upper Level (1 ~ 10)" 3 "Upper Level (1 ~ 10)" 4 "Upper Level (1 ~ 10)" 5 "Upper Level (1 ~ 10)" 6 "Upper Level (1 ~ 10)" 7 "Upper Level (1 ~ 10)" 8 "Upper Level (1 ~ 10)" 9 "Upper Level (1 ~ 10)" 10 "Upper Level (1 ~ 10)" 10 "Reserved" 11 "Reserved" 12 "Reserved" 13 "Reserved" 14 "Reserved" 15 "Reserved" 16 "Reserved" 17 "Lower Level (-1 ~ -10)" 18 "Lower Level (-1 ~ -10)" 19 "Lower Level (-1 ~ -10)" 20 "Lower Level (-1 ~ -10)" 21 "Lower Level (-1 ~ -10)" 22 "Lower Level (-1 ~ -10)" 23 "Lower Level (-1 ~ -10)" 24 "Lower Level (-1 ~ -10)" 25 "Lower Level (-1 ~ -10)" 26 "Lower Level (-1 ~ -10)" 27 "Reserved" 28 "Reserved" 29 "Reserved" 30 "Reserved" 31 "Invalid" ;
VAL_ 952 BLTN_CAM_Set_PEV_AppNoti 0 "Default" 1 "Off" 2 "On" 3 "Invalid" ;
VAL_ 952 BLTN_CAM_Set_WiFi_AutoOn 0 "Default" 1 "Off" 2 "On" 3 "Invalid" ;
VAL_ 952 BLTN_CAM_StrgPropSet 0 "Normal" 1 "On While Recordings" 2 "On While Parked" 3 "Driving Events" 4 "Parked Events" 5 "Reserved" 6 "Reserved" 7 "Reserved" 8 "Reserved" 9 "Reserved" 10 "Reserved" 11 "Reserved" 12 "Reserved" 13 "Reserved" 14 "Reserved" 15 "Invalid" ;
VAL_ 952 BLTN_CAM_File_DEL_CPY_Op_State 0 "Default" 1 "On Deleting" 2 "On Copying" 3 "operation completed" 4 "pausing the operation" 5 "operation canceled" 6 "Reserved" 7 "Reserved" 8 "Reserved" 9 "Reserved" 10 "Delete Error, No file(s)" 11 "Copy Error, No file(s)" 12 "Copy Error, Not enough target stroage space." 13 "The space not existed(not mounted)" 14 "the commend file is wrong." 15 "Invalid" ;
VAL_ 952 BLTN_CAM_File_DEL_CPY_NumTot 0 "Default" 1 "0x001~0xFFFB:Number of files" 65531 "0x001~0xFFFB:Number of files" 65532 "not operated" 65533 "The space not existed(not mounted)" 65534 "Not enough space" 65535 "Invalid" ;
VAL_ 952 BLTN_CAM_File_DEL_CPYed_Num 0 "Default" 1 "0x001~0xFFFB:Number of files" 65531 "0x001~0xFFFB:Number of files" 65532 "not operated" 65533 "The space not existed(not mounted)" 65534 "Not enough space" 65535 "Invalid" ;
VAL_ 952 BLTN_CAM_Set_RR_Ver_Pos 0 "Mid" 1 "Upper Level (1 ~ 10)" 2 "Upper Level (1 ~ 10)" 3 "Upper Level (1 ~ 10)" 4 "Upper Level (1 ~ 10)" 5 "Upper Level (1 ~ 10)" 6 "Upper Level (1 ~ 10)" 7 "Upper Level (1 ~ 10)" 8 "Upper Level (1 ~ 10)" 9 "Upper Level (1 ~ 10)" 10 "Upper Level (1 ~ 10)" 10 "Reserved" 11 "Reserved" 12 "Reserved" 13 "Reserved" 14 "Reserved" 15 "Reserved" 16 "Reserved" 17 "Lower Level (-1 ~ -10)" 18 "Lower Level (-1 ~ -10)" 19 "Lower Level (-1 ~ -10)" 20 "Lower Level (-1 ~ -10)" 21 "Lower Level (-1 ~ -10)" 22 "Lower Level (-1 ~ -10)" 23 "Lower Level (-1 ~ -10)" 24 "Lower Level (-1 ~ -10)" 25 "Lower Level (-1 ~ -10)" 26 "Lower Level (-1 ~ -10)" 27 "Reserved" 28 "Reserved" 29 "Reserved" 30 "Reserved" 31 "Invalid" ;
VAL_ 950 BLTN_CAM_State 0 "BLTN_CAM Valid" 1 "BLTN_CAM Front Camera Invalid" 2 "BLTN_CAM Rear Camera Invalid" 3 "BLTN_CAM Front/Rear Camera Inavlid" 4 "BLTN_CAM Record Invalid" 5 "Reserved" 6 "Reserved" 7 "Reserved" 8 "Reserved" 9 "Reserved" 10 "Reserved" 11 "Reserved" 12 "Reserved" 13 "Reserved" 14 "Reserved" 15 "Invalid" ;
VAL_ 950 BLTN_CAM_RecSta_DEV 0 "Off" 1 "Recording" 2 "Reserved" 3 "invalid" ;
VAL_ 950 BLTN_CAM_RecSta_MAR 0 "Off" 1 "Recording" 2 "Reserved" 3 "invalid" ;
VAL_ 950 BLTN_CAM_RecSta_TML 0 "Off" 1 "Recording" 2 "Reserved" 3 "invalid" ;
VAL_ 950 BLTN_CAM_RecSta_OWP 0 "Off" 1 "Recording" 2 "Reserved" 3 "invalid" ;
VAL_ 950 BLTN_CAM_RecSta_PEV 0 "Off" 1 "Recording" 2 "Reserved" 3 "invalid" ;
VAL_ 950 BLTN_CAM_Prk_EV_Cnt 0 "0x0x0~0xC8:the number of the Park Event Record(0~200)" 200 "0x0x0~0xC8:the number of the Park Event Record(0~200)" 201 "Reserved" 202 "Reserved" 203 "Reserved" 204 "Reserved" 205 "Reserved" 206 "Reserved" 207 "Reserved" 208 "Reserved" 209 "Reserved" 210 "Reserved" 211 "Reserved" 212 "Reserved" 213 "Reserved" 214 "Reserved" 215 "Reserved" 216 "Reserved" 217 "Reserved" 218 "Reserved" 219 "Reserved" 220 "Reserved" 221 "Reserved" 222 "Reserved" 223 "Reserved" 224 "Reserved" 225 "Reserved" 226 "Reserved" 227 "Reserved" 228 "Reserved" 229 "Reserved" 230 "Reserved" 231 "Reserved" 232 "Reserved" 233 "Reserved" 234 "Reserved" 235 "Reserved" 236 "Reserved" 237 "Reserved" 238 "Reserved" 239 "Reserved" 240 "Reserved" 241 "Reserved" 242 "Reserved" 243 "Reserved" 244 "Reserved" 245 "Reserved" 246 "Reserved" 247 "Reserved" 248 "Reserved" 249 "Reserved" 250 "Reserved" 251 "Reserved" 252 "Over than 200 count" 253 "Park Mode was not Excuted" 254 "Park Mode was not Supported" 255 "invalid" ;
VAL_ 950 BLTN_CAM_Prk_Oped_Time 0 "Park Mode was not Excuted" 1 "0x1~0xFB:the hours of Park Mode Operated" 251 "0x1~0xFB:the hours of Park Mode Operated" 252 "Prak Mode is not set.( Aux. Bat. is connected)" 253 "Auxiliary Battery Is not connected. - Auxiliary Battery not applicable on this vehicle model" 255 "invalid" ;
VAL_ 950 BLTN_CAM_Prk_Oprable_Time 0 "0x0x0~0xFB:the hours of Park Mode Operatable" 251 "0x0x0~0xFB:the hours of Park Mode Operatable" 252 "Park Mode is not set.( Aux. Bat. Is connected)" 253 "Auxiliary Battery is not connected. - Auxiliary Battery applicable on this vehicle model" 254 "Auxiliary Battery is not connected. ? Auxiliary Battery not applicable on this vehicle model" 255 "Invalid" ;
VAL_ 950 BLTN_CAM_SD_Card_State 0 "Good, SD card is OK.(Green State)" 1 "SD card replacement recommend.(Yallow State)" 2 "SD card replacement required or Health State is not available.(Red State)" 3 "SD card unrecognizable or No SD card found." 4 "SD card total capacity spec less than 64GByte (Built-in Cam Support 64GByte or higher)" 5 "SD card file system is not for Built-in Cam(Built-in CAM only support exFAT filesystem)" 6 "SD card not enough free space, need more free space for built-in Cam(less than 32GByte, must be 32GB" 7 "RESERVED" 8 "RESERVED" 9 "RESERVED" 10 "RESERVED" 11 "RESERVED" 12 "RESERVED" 13 "RESERVED" 14 "RESERVED" 15 "Invalid(Red State)" ;
VAL_ 950 BLTN_CAM_Prk_Oprable_Time_Max 0 "0x0x0~0xFB:the hours of Park Mode Operatable" 251 "0x0x0~0xFB:the hours of Park Mode Operatable" 252 "Park Mode is not set.( Aux. Bat. Is connected)" 253 "Auxiliary Battery is not connected. - Auxiliary Battery applicable on this vehicle model" 254 "Auxiliary Battery is not connected. ? Auxiliary Battery not applicable on this vehicle model" 255 "Invalid" ;
VAL_ 950 BLTN_CAM_AuxBat_Conn_State 0 "Default" 1 "Auxiliary Battery is connected.(P-LBM or B-LBM)" 2 "Auxiliary Battery is not connected. - Auxiliary Battery applicable on this vehicle model" 3 "Auxiliary Battery is not connected. ? Auxiliary Battery not applicable on this vehicle model" ;
VAL_ 950 BLTN_CAM_AuxBat_CapPer 0 "0x0x0~0x64: Aux Bat Capacity Percent(0~100%)" 100 "0x0x0~0x64: Aux Bat Capacity Percent(0~100%)" 100 "Reserved" 101 "Reserved" 102 "Reserved" 103 "Reserved" 104 "Reserved" 105 "Reserved" 106 "Reserved" 107 "Reserved" 108 "Reserved" 109 "Reserved" 110 "Reserved" 111 "Reserved" 112 "Reserved" 113 "Reserved" 114 "Reserved" 115 "Reserved" 116 "Reserved" 117 "Reserved" 118 "Reserved" 119 "Reserved" 120 "Reserved" 121 "Reserved" 122 "Reserved" 123 "Reserved" 124 "Reserved" 125 "Reserved" 126 "Reserved" 127 "Invalid" ;
VAL_ 950 BLTN_CAM_RecSta_OWD 0 "Off" 1 "Recording" 2 "Reserved" 3 "invalid" ;
VAL_ 2382594305 DATC_RrDrvTempCDis 0 "Blank Display" 1 "'LO' Display" 254 "'HI' Display" 255 "Error Indicator" ;
VAL_ 2382594305 DATC_RrDrvTempFDis 0 "Blank Display" 1 "'LO' Display" 254 "'HI' Display" 255 "Error Indicator" ;
VAL_ 2382594305 DATC_RrPassTempCDis 0 "Blank Display" 1 "'LO' Display" 254 "'HI' Display" 255 "Error Indicator" ;
VAL_ 2382594305 DATC_RrPassTempFDis 0 "Blank Display" 1 "'LO' Display" 254 "'HI' Display" 255 "Error Indicator" ;
VAL_ 2382594305 DATC_RrDrvMTCTempLvlDis 0 "Off Display" 1 "0 Level" 2 "1 Level" 3 "2 Level" 4 "3 Level" 5 "4 Level" 6 "5 Level" 7 "6 Level" 8 "7 Level" 9 "8 Level" 10 "NOT Used" 15 "Error Indicator" ;
VAL_ 847 Drv_SHVU_DTCdisplay 0 "DTC is not exist(Fail is not exist)" 1 "IGN2 Fuse Open Detection" 2 "Switch Input Detection at Same Time" 3 "NTC/Heating wire Open Detection" 4 "NTC+/NTC- Terminal Short Detection" 5 "NTC+/Heater+ Terminal Short Detection" 6 "NTC+/Heater-, Heater+/Heater-, Heater+/NTC- Terminal Short Detection" 7 "NTC+/Heater- Wiring Short Detection" 8 "NTC+/Heater-, Heater+/Heater-, Heater+/NTC- Wiring Short Detection" 9 "Target Temperature Dissatisfied" 10 "Blower+/Blower- Short, Blower+/Blower Speed, Blower-/Blower Speed Wiring Short Detection" 11 "Blower+/Blower RPM, Blower-/Blower RPM, Blower Speed/Blower RPM Short Detection" 12 "Blower+, Blower-, Blower Speed Signal open Detection" 13 "Blower RPM signal Open Detection" 14 "0x0E~0xFD:Unused" 253 "0x0E~0xFD:Unused" 254 "No Display" 255 "Invalid" ;
VAL_ 847 Drv_SHVU_DiagMode 0 "Default" 1 "DTC Mode" 2 "Normal Mode" 3 "Invalid" ;
VAL_ 2319620609 HUD_HghtSta 0 "Step 1" 1 "Step 2" 2 "Step 3" 3 "Step 4" 4 "Step 5" 5 "Step 6" 6 "Step 7" 7 "Step 8" 8 "Step 9" 9 "Step 10" 10 "Step 11" 11 "Step 12" 12 "Step 13" 13 "Step 14" 14 "Step 15" 15 "Step 16" 16 "Step 17" 17 "Step 18" 18 "Step 19" 19 "Step 20" ;
VAL_ 2319620609 HUD_PbackSta 0 "Stop" 1 "Play 1" 2 "Play 2" 3 "Health Care IMS" 4 "Profile1" 5 "Profile2" 6 "Guest" 7 "Invalid" ;
VAL_ 2319620609 HUD_BrgtnsSta 0 "Step 1" 1 "Step 2" 2 "Step 3" 3 "Step 4" 4 "Step 5" 5 "Step 6" 6 "Step 7" 7 "Step 8" 8 "Step 9" 9 "Step 10" 10 "Step 11" 11 "Step 12" 12 "Step 13" 13 "Step 14" 14 "Step 15" 15 "Step 16" 16 "Step 17" 17 "Step 18" 18 "Step 19" 19 "Step 20" ;
VAL_ 2319620609 HUD_Type 0 "windshield type" 1 "combiner type" 2 "reserved" 3 "invalid" ;
VAL_ 2319620609 HUD_RotatSta 0 "CENTER" 1 "CCW 1" 17 "CW 1" 18 "CW 2" 19 "CW 3" 20 "CW 4" 21 "CW 5" 22 "CW 6" 23 "CW 7" 24 "CW 8" 25 "CW 9" 26 "CW 10" 2 "CCW 2" 3 "CCW 3" 4 "CCW 4" 5 "CCW 5" 6 "CCW 6" 7 "CCW 7" 8 "CCW 8" 9 "CCW 9" 10 "CCW 10" ;
VAL_ 2319620609 HUD_setSW 0 "OFF" 1 "ON" 2 "reserved" 3 "invalid" ;
VAL_ 2319620609 HUD_ContentsTBTStatus 0 "OFF" 1 "ON" 2 "reserved" 3 "invalid" ;
VAL_ 2319620609 HUD_ContentsDISStatus 0 "OFF" 1 "ON" 2 "reserved" 3 "invalid" ;
VAL_ 2319620609 HUD_ContentsSCCStatus 0 "OFF" 1 "ON" 2 "reserved" 3 "invalid" ;
VAL_ 2319620609 HUD_SportHUD 0 "Default" 1 "Off" 2 "Sport HUD" 3 "Invalid" ;
VAL_ 2319620609 HUD_ContentsBCWStatus 0 "OFF" 1 "ON" 2 "reserved" 3 "invalid" ;
VAL_ 2319620609 HUD_ContentsAVStatus 0 "OFF" 1 "ON" 2 "reserved" 3 "invalid" ;
VAL_ 2319620609 HUD_ContentsSpeedStatus 0 "Default" 1 "Off" 2 "On" 3 "Invaild" ;
VAL_ 2319620609 HUD_ImsAutoSaveStatus 0 "Default" 1 "Off" 2 "On" 3 "Invalid" ;
VAL_ 942 AMP_Beep1VolumeStep 0 "0x0x0~0xFD:Beep1 Volume" 253 "0x0x0~0xFD:Beep1 Volume" 254 "Req.amp. Beep1 settings" 255 "Invalid" ;
VAL_ 942 AMP_Analog_OutputCh_Select 65535 "Invalid" ;
VAL_ 942 AMP_Beep1_OutputCh_Select 65535 "Invaild" ;
VAL_ 942 AMP_Beep1KBDVolumeStep 0 "0x0x0~0xFE:keyboard Beep Volume" 254 "0x0x0~0xFE:keyboard Beep Volume" 255 "Invalid" ;
VAL_ 942 AMP_SPDIF_OutputCh_Select 65535 "Invaild" ;
VAL_ 939 PSB_LHFlrSta 0 "No failure" 1 "Failure, Service Required" 2 "Defect, PSB warning light off" 3 "Signal not valid" ;
VAL_ 939 PSB_LHActvSta 0 "No PSB motor activation" 1 "PSB retract cycle active" 2 "Reserved" 3 "Reserved" ;
VAL_ 939 PSB_RHFlrSta 0 "No failure" 1 "Failure, Service Required" 2 "Defect, PSB warning light off" 3 "Signal not valid" ;
VAL_ 939 PSB_RHActvSta 0 "No PSB motor activation" 1 "PSB retract cycle active" 2 "Reserved" 3 "Reserved" ;
VAL_ 939 PSB_ActForAcu 0 "Inactive" 1 "Active" 2 "Reserved" 3 "Failure" ;
VAL_ 939 PSB_HapticWarnSta 0 "No PSB activation" 1 "PSB Haptic active-1st step" 2 "PSB Haptic active-2nd step" 3 "Reserved" ;
VAL_ 939 PSB_RHActForPss 0 "No PSB motor activation" 1 "PSB retract cycle active" 2 "Reserved" 3 "Reserved" ;
VAL_ 939 PSB_LHActForPss 0 "No PSB motor activation" 1 "PSB retract cycle active" 2 "Reserved" 3 "Reserved" ;
VAL_ 934 PTGM_HazardSta 0 "Off" 1 "On" 2 "Inactive" 3 "RESERVED" ;
VAL_ 934 PTGM_ModSta 0 "Power Mode" 1 "Manual Mode" 2 "RESERVED" 3 "Error Indicator" ;
VAL_ 934 PTGM_MovSta 0 "Stop" 1 "Moving" 2 "RESERVED" 3 "Error Indicator" ;
VAL_ 934 PTGM_OptTyp 0 "Off" 1 "On(PTG is applied)" 2 "RESERVED" 3 "Error Indicator" ;
VAL_ 934 PTGM_ReleaseRlySta 0 "Off" 1 "On" 2 "RESERVED" 3 "Error Indicator" ;
VAL_ 934 PTGM_TrnkLkSwSta 0 "Off" 1 "Close & Lock" 2 "RESERVED" 3 "Error Indicator" ;
VAL_ 934 PTGM_UsmSetSta 0 "Default" 1 "Power Mode" 2 "Manual Mode" 3 "Invalid" ;
VAL_ 934 PTGM_HeightRValue 0 "Default" 1 "Level1" 2 "Level2" 3 "Level3" 4 "Level4" 5 "RESERVED" 6 "User Setting" 7 "Invalid" ;
VAL_ 934 PTGM_OpnClsState 0 "Default" 1 "Closed" 2 "1 lvl open" 3 "2 lvl open" 4 "3 lvl open" 5 "4 lvl open" 6 "Full open" 7 "RESERVED" 8 "Closing operation" 9 "Opening operation" 10 "Position Error" 11 "RESERVED" 12 "RESERVED" 13 "RESERVED" 14 "RESERVED" 15 "Invalid" ;
VAL_ 934 PTGM_CmdWarn 0 "Default" 1 "Gear Not P or Vehicle speed" 2 "Obstacle detected" 3 "System temporary error" 4 "Power mode OFF" 5 "RESERVED" 6 "RESERVED" 7 "Invalid" ;
VAL_ 934 PTGM_AntiPinchSnsr 0 "Default" 1 "Applied" 2 "Not applied" 3 "Invalid" ;
VAL_ 934 PTGM_AutoWashModeSta 0 "Default" 1 "PTGM Auto Wash Mode Off (Ready)" 2 "PTGM Auto Wash Mode Off (Error)" 3 "PTGM Auto Wash Mode On" 4 "RESERVED" 5 "RESERVED" 6 "RESERVED" 7 "Invalid" ;
VAL_ 934 PTGM_FobSrch_Req 0 "Off" 1 "Initial Srch Req" 2 "Srch Req After Detect" 3 "Invalid" ;
VAL_ 934 PTGM_TlgtAwayCloseRValue 0 "Default" 1 "Off" 2 "On" 3 "Invalid" ;
VAL_ 934 PTGM_TrnkTlgtOption 0 "Default" 1 "Power Trunk" 2 "Power Tailgate" 3 "Invalid" ;
VAL_ 934 PTGM_LatchType 0 "Default" 1 "Integrated Latch" 2 "Separated Latch" 3 "Invalid" ;
VAL_ 934 PTGM_SpeedRValue 0 "Default" 1 "Fast" 2 "Slow" 3 "Invalid" ;
VAL_ 862 RL_CrashUnlockCmd 0 "Off" 1 "Unlock(Crash)" ;
VAL_ 862 Warn_RrLftDrSwSta_SBCM 0 "Close" 1 "Open" 2 "RESERVED" 3 "Error Indicator" ;
VAL_ 862 DoorLock_RrLftDrUnLkSta_SBCM 0 "Lock" 1 "Unlock" 2 "Not Used" 3 "Error Indicator" ;
VAL_ 862 RL_SEAActivated 0 "InActivated" 1 "Activated" 2 "Not Used" 3 "Error Indicator" ;
VAL_ 862 RL_SEAWarn 0 "SEA Left Warning OFF" 1 "SEA Left Warning ON" 2 "Reserved" 3 "Invalid" ;
VAL_ 862 RL_SEWWarn 0 "SEW Left Warning OFF" 1 "SEW Left Warning ON" 2 "Reserved" 3 "InvalidInvalid" ;
VAL_ 862 RL_ReleaseWarn 0 "Release Warning OFF" 1 "Release Warning ON" 2 "Reserved" 3 "Invalid" ;
VAL_ 862 RL_SWFailAlarm 0 "Off" 1 "On" 2 "Not Used" 3 "Error Indicator" ;
VAL_ 862 RL_ChildLock_ActnFlSta 0 "OK" 1 "Failed" 2 "Not Used" 3 "Error Indicator" ;
VAL_ 862 RL_MRActivationAlarm 0 "Off" 1 "On" 2 "Not Used" 3 "Error Indicator" ;
VAL_ 862 RL_ChildLock_Status 0 "ChildLock On" 1 "ChildLock Off" 2 "RESERVED" 3 "RESERVED" ;
VAL_ 862 USM_RLGhostDoorSta 0 "Default" 1 "Off" 2 "On" 3 "Invalid" ;
VAL_ 862 DoorLock_PDSLkSwSta_RL 0 "Lock" 1 "Unlock" 2 "Not Used" 3 "Error Indicator" ;
VAL_ 862 PDS_TypeOption_RL 0 "Off" 1 "On" 2 "Not Used" 3 "Error Indicator" ;
VAL_ 862 RLDoorPushAlarm 0 "Off" 1 "On" 2 "Not Used" 3 "Error Indicator" ;
VAL_ 929 SCM_Opt 0 "Default" 1 "SCM" 2 "Not Used" 3 "Error Indicator" ;
VAL_ 929 Tilt_VirtualLimExist 0 "Off" 1 "On" 2 "Not Used" 3 "Error Indicator" ;
VAL_ 929 Tele_SnsrErr 0 "Off" 1 "On" 2 "Not Used" 3 "Error Indicator" ;
VAL_ 929 Tele_VirtualLim 0 "Off" 1 "Fwd" 2 "Bwd" 3 "Error Indicator" ;
VAL_ 929 Tele_VirtualLimExist 0 "Off" 1 "On" 2 "Not Used" 3 "Error Indicator" ;
VAL_ 929 TiltTele_Profile1MemoryExist 0 "Off" 1 "On" 2 "Not Used" 3 "Error Indicator" ;
VAL_ 929 Tilt_MnlSwSta 0 "Off" 1 "Up" 2 "Down" 3 "Error Indicator" ;
VAL_ 929 TiltTele_Profile2MemoryExist 0 "Off" 1 "On" 2 "Not Used" 3 "Error Indicator" ;
VAL_ 929 TiltTele_GuestMemoryExist 0 "Off" 1 "On" 2 "Not Used" 3 "Error Indicator" ;
VAL_ 929 TiltTele_IMS1MemoryExist 0 "Off" 1 "On" 2 "Not Used" 3 "Error Indicator" ;
VAL_ 929 TiltTele_IMS2MemoryExist 0 "Off" 1 "On" 2 "Not Used" 3 "Error Indicator" ;
VAL_ 929 TiltTele_IMS3MemoryExist 0 "Off" 1 "On" 2 "Not Used" 3 "Error Indicator" ;
VAL_ 929 TiltTele_ReturnMemoryExist 0 "Off" 1 "On" 2 "Not Used" 3 "Error Indicator" ;
VAL_ 929 Tilt_OpSta 0 "Off" 1 "Moving" 2 "MovingInhibit" 3 "AlreadyReached" ;
VAL_ 929 Tele_OpSta 0 "Off" 1 "Moving" 2 "MovingInhibit" 3 "AlreadyReached" ;
VAL_ 929 Tele_MnlSwSta 0 "Off" 1 "Fwd" 2 "Bwd" 3 "Error Indicator" ;
VAL_ 929 Tilt_SnsrErr 0 "Off" 1 "On" 2 "Not Used" 3 "Error Indicator" ;
VAL_ 929 Tilt_VirtualLim 0 "Off" 1 "Up" 2 "Down" 3 "Error Indicator" ;
